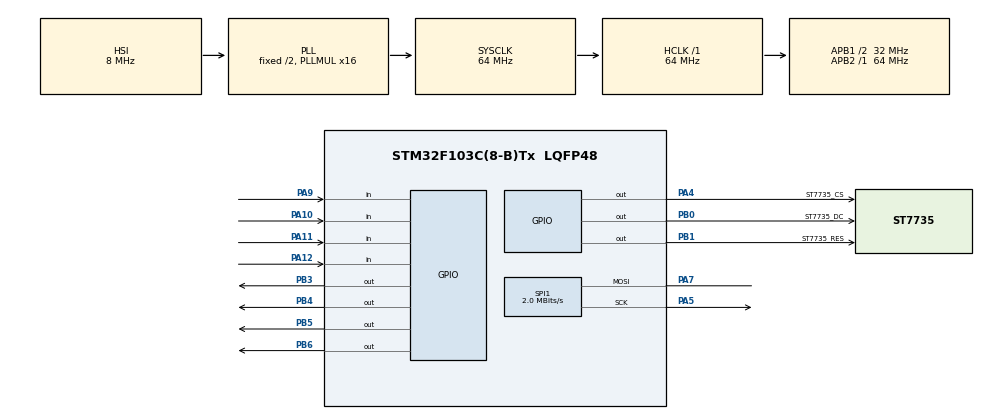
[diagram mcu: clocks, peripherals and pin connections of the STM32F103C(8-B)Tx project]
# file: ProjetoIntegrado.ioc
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Mcu.Family=STM32F1
Mcu.Name=STM32F103C(8-B)Tx
Mcu.Package=LQFP48
NVIC.PriorityGroup=NVIC_PRIORITYGROUP_4
PA10.GPIO_PuPd=GPIO_PULLUP
PA10.Signal=GPIO_Input
PA11.GPIO_PuPd=GPIO_PULLUP
PA11.Signal=GPIO_Input
PA12.GPIO_PuPd=GPIO_PULLUP
PA12.Signal=GPIO_Input
PA13.Mode=Serial_Wire
PA13.Signal=SYS_JTMS-SWDIO
PA14.Mode=Serial_Wire
PA14.Signal=SYS_JTCK-SWCLK
PA4.GPIO_Label=ST7735_CS
PA4.Signal=GPIO_Output
PA5.Mode=Simplex_Bidirectional_Master
PA5.Signal=SPI1_SCK
PA7.Mode=Simplex_Bidirectional_Master
PA7.Signal=SPI1_MOSI
PA9.GPIO_PuPd=GPIO_PULLUP
PA9.Signal=GPIO_Input
PB0.GPIO_Label=ST7735_DC
PB0.Signal=GPIO_Output
PB1.GPIO_Label=ST7735_RES
PB1.Signal=GPIO_Output
PB3.Signal=GPIO_Output
PB4.Signal=GPIO_Output
PB5.Signal=GPIO_Output
PB6.Signal=GPIO_Output
ProjectManager.HeapSize=0x200
ProjectManager.StackSize=0x400
ProjectManager.TargetToolchain=STM32CubeIDE
RCC.AHBFreq_Value=64000000
RCC.APB1CLKDivider=RCC_HCLK_DIV2
RCC.APB1Freq_Value=32000000
RCC.APB1TimFreq_Value=64000000
RCC.APB2Freq_Value=64000000
RCC.APB2TimFreq_Value=64000000
RCC.HCLKFreq_Value=64000000
RCC.PLLMUL=RCC_PLL_MUL16
RCC.SYSCLKFreq_VALUE=64000000
RCC.SYSCLKSource=RCC_SYSCLKSOURCE_PLLCLK
RCC.USBFreq_Value=64000000
SPI1.BaudRatePrescaler=SPI_BAUDRATEPRESCALER_32
SPI1.CalculateBaudRate=2.0 MBits/s
SPI1.Direction=SPI_DIRECTION_1LINE
SPI1.Mode=SPI_MODE_MASTER
SPI1.VirtualType=VM_MASTER
board=custom

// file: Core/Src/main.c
/* USER CODE BEGIN Header */
/**
  ******************************************************************************
  * @file           : main.c
  * @brief          : Main program body
  ******************************************************************************
  * @attention
  *
  * <h2><center>&copy; Copyright (c) 2025 STMicroelectronics.
  * All rights reserved.</center></h2>
  *
  * This software component is licensed by ST under BSD 3-Clause license,
  * the "License"; You may not use this file except in compliance with the
  * License. You may obtain a copy of the License at:
  *                        opensource.org/licenses/BSD-3-Clause
  *
  ******************************************************************************
  */
/* USER CODE END Header */
#include "main.h"
/* USER CODE BEGIN Includes */
#include "st7735\st7735.h"
#include <stdlib.h>
/* USER CODE END Includes */

SPI_HandleTypeDef hspi1;

/* USER CODE BEGIN PV */

static const uint16_t ImagemVitoria4[][60*80/2]   = {
  0x0000, 0x0000, 0x0000, 0x0000, 0x0000, 0x0000, 0x0000, 0x0000, 0x0000, 0x0000, 0x0000, 0x0000, 0x0000, 0x0000, 0x0000, 0x0000, 0x0000, 0x0000, 0x0000, 0x0000, 0x0000, 0x0000, 0x0000, 0x0000, 0x0000, 0x0000, 0x0000, 0x0000, 0x0000, 0x0000, 0x0000, 0x0000, 0x0000, 0x0000, 0x0000, 0x0000, 0x0000, 0x0000, 0x0000, 0x0000, 0x0000, 0x0000, 0x0000, 0x0000, 0x0000, 0x0000, 0x0000, 0x0000, 0x0000, 0x0000, 0x0000, 0x0000, 0x0000, 0x0000, 0x0000, 0x0000, 0x0000, 0x0000, 0x0000, 0x0000, 0x0000, 0x0000, 0x0000, 0x0000, 0x0000, 0x0000, 0x0000, 0x0000, 0x0000, 0x0000, 0x0000, 0x0000, 0x0000, 0x0000, 0x0000, 0x0000, 0x0000, 0x0000, 0x0000, 0x0000,
  0x0000, 0x0000, 0x0000, 0x0000, 0x0000, 0x0000, 0x0000, 0x0000, 0x0000, 0x0000, 0x0000, 0x0000, 0x0000, 0x0000, 0x0000, 0x0000, 0x0000, 0x0000, 0x0000, 0x0000, 0x0000, 0x0000, 0x0000, 0x0000, 0x0000, 0x0000, 0x0000, 0x0000, 0x0000, 0x0000, 0x0000, 0x0000, 0x0000, 0x0000, 0x0000, 0x0000, 0x0000, 0x0000, 0x0000, 0x0000, 0x0000, 0x0000, 0x0000, 0x0000, 0x0000, 0x0000, 0x0000, 0x0000, 0x0000, 0x0000, 0x0000, 0x0000, 0x0000, 0x0000, 0x0000, 0x0000, 0x0000, 0x0000, 0x0000, 0x0000, 0x0000, 0x0000, 0x0000, 0x0000, 0x0000, 0x0000, 0x0000, 0x0000, 0x0000, 0x0000, 0x0000, 0x0000, 0x0000, 0x0000, 0x0000, 0x0000, 0x0000, 0x0000, 0x0000, 0x0000,
  0x0000, 0x0000, 0x0000, 0x0000, 0x0000, 0x0000, 0x0000, 0x0000, 0x0000, 0x0000, 0x0000, 0x0000, 0x0000, 0x0000, 0x0000, 0x0000, 0x0000, 0x0000, 0x0000, 0x0000, 0x0000, 0x0000, 0x0000, 0x0000, 0x0000, 0x0000, 0x0000, 0x0000, 0x0000, 0x0000, 0x0000, 0x0000, 0x0000, 0x0000, 0x0000, 0x0000, 0x0000, 0x0000, 0x0000, 0x0000, 0x0000, 0x0000, 0x0000, 0x0000, 0x0000, 0x0000, 0x0000, 0x0000, 0x0000, 0x0000, 0x0000, 0x0000, 0x0000, 0x0000, 0x0000, 0x0000, 0x0000, 0x0000, 0x0000, 0x0000, 0x0000, 0x0000, 0x0000, 0x0000, 0x0000, 0x0000, 0x0000, 0x0000, 0x0000, 0x0000, 0x0000, 0x0000, 0x0000, 0x0000, 0x0000, 0x0000, 0x0000, 0x0000, 0x0000, 0x0000,
  0x0000, 0x0000, 0x0000, 0x0000, 0x0000, 0x0000, 0x0000, 0x0000, 0x0000, 0x0000, 0x0000, 0x0000, 0x0000, 0x0000, 0x0000, 0x0000, 0x0000, 0x0000, 0x0000, 0x0000, 0x0000, 0x0000, 0x0000, 0x0000, 0x0000, 0x0000, 0x0000, 0x0000, 0x0000, 0x0000, 0x0000, 0x0000, 0x0000, 0x0000, 0x0000, 0x0000, 0x0000, 0x0000, 0x0000, 0x0000, 0x0000, 0x0000, 0x0000, 0x0000, 0x0000, 0x0000, 0x0000, 0x0000, 0x0000, 0x0000, 0x0000, 0x0000, 0x0000, 0x0000, 0x0000, 0x0000, 0x0000, 0x0000, 0x0000, 0x0000, 0x0000, 0x0000, 0x0000, 0x0000, 0x0000, 0x0000, 0x0000, 0x0000, 0x0000, 0x0000, 0x0000, 0x0000, 0x0000, 0x0000, 0x0000, 0x0000, 0x0000, 0x0000, 0x0000, 0x0000,
  0x0000, 0x0000, 0x0000, 0x0000, 0x0000, 0x0000, 0x0000, 0x0000, 0x0000, 0x0000, 0x0000, 0x0000, 0x0000, 0x0000, 0x0000, 0x0000, 0x0000, 0x0000, 0x0000, 0x0000, 0x0000, 0x0000, 0x0000, 0x0000, 0x0000, 0x0000, 0x0000, 0x0000, 0x0000, 0x0000, 0x0000, 0x0000, 0x0000, 0x0000, 0x0000, 0x0000, 0x0000, 0x0000, 0x0000, 0x0000, 0x0000, 0x0000, 0x0000, 0x0000, 0x0000, 0x0000, 0x0000, 0x0000, 0x0000, 0x0000, 0x0000, 0x0000, 0x0000, 0x0000, 0x0000, 0x0000, 0x0000, 0x0000, 0x0000, 0x0000, 0x0000, 0x0000, 0x0000, 0x0000, 0x0000, 0x0000, 0x0000, 0x0000, 0x0000, 0x0000, 0x0000, 0x0000, 0x0000, 0x0000, 0x0000, 0x0000, 0x0000, 0x0000, 0x0000, 0x0000,
  0x0000, 0x0000, 0x0000, 0x0000, 0x0000, 0x0000, 0x0000, 0x0000, 0x0000, 0x0000, 0x0000, 0x0000, 0x0000, 0x0000, 0x0000, 0x0000, 0x0000, 0x0000, 0x0000, 0x0000, 0x0000, 0x0000, 0x0000, 0x0000, 0x0000, 0x0000, 0x0000, 0x0000, 0x0000, 0x0000, 0x0000, 0x0000, 0x0000, 0x0000, 0x0000, 0x0000, 0x0000, 0x0000, 0x0000, 0x0000, 0x0000, 0x0000, 0x0000, 0x0000, 0x0000, 0x0000, 0x0000, 0x0000, 0x0000, 0x0000, 0x0000, 0x0000, 0x0000, 0x0000, 0x0000, 0x0000, 0x0000, 0x0000, 0x0000, 0x0000, 0x0000, 0x0000, 0x0000, 0x0000, 0x0000, 0x0000, 0x0000, 0x0000, 0x0000, 0x0000, 0x0000, 0x0000, 0x0000, 0x0000, 0x0000, 0x0000, 0x0000, 0x0000, 0x0000, 0x0000,
  0x0000, 0x0000, 0x0000, 0x0000, 0x0000, 0x0000, 0x0000, 0x0000, 0x0000, 0x0000, 0x0000, 0x0000, 0x0000, 0x0000, 0x0000, 0x0000, 0x0000, 0x0000, 0x0000, 0x0000, 0x0000, 0x0000, 0x0000, 0x0000, 0x0000, 0x0000, 0x0000, 0x0000, 0x0000, 0x0000, 0x0000, 0x0000, 0x0000, 0x0000, 0x0000, 0x0000, 0x0000, 0x0000, 0x0000, 0x0000, 0x0000, 0x0000, 0x0000, 0x0000, 0x0000, 0x0000, 0x0000, 0x0000, 0x0000, 0x0000, 0x0000, 0x0000, 0x0000, 0x0000, 0x0000, 0x0000, 0x0000, 0x0000, 0x0000, 0x0000, 0x0000, 0x0000, 0x0000, 0x0000, 0x0000, 0x0000, 0x0000, 0x0000, 0x0000, 0x0000, 0x0000, 0x0000, 0x0000, 0x0000, 0x0000, 0x0000, 0x0000, 0x0000, 0x0000, 0x0000,
  0x0000, 0x0000, 0x0000, 0x0000, 0x0000, 0x0000, 0x0000, 0x0000, 0x0000, 0x0000, 0x0000, 0x0000, 0x0000, 0x0000, 0x0000, 0x0000, 0x0000, 0x0000, 0x0000, 0x0000, 0x0000, 0x0000, 0x0000, 0x0000, 0x0000, 0x0000, 0x0000, 0x0000, 0x0000, 0x0000, 0x0000, 0x0000, 0x0000, 0x0000, 0x0000, 0x0000, 0x0000, 0x0000, 0x0000, 0x0000, 0x0000, 0x0000, 0x0000, 0x0000, 0x0000, 0x0000, 0x0000, 0x0000, 0x0000, 0x0000, 0x0000, 0x0000, 0x0000, 0x0000, 0x0000, 0x0000, 0x0000, 0x0000, 0x0000, 0x0000, 0x0000, 0x0000, 0x0000, 0x0000, 0x0000, 0x0000, 0x0000, 0x0000, 0x0000, 0x0000, 0x0000, 0x0000, 0x0000, 0x0000, 0x0000, 0x0000, 0x0000, 0x0000, 0x0000, 0x0000,
  0x0000, 0x0000, 0x0000, 0x0000, 0x0000, 0x0000, 0x0000, 0x0000, 0x0000, 0x0000, 0x0000, 0x0000, 0x0000, 0x0000, 0x0000, 0x0000, 0x0000, 0x0000, 0x0000, 0x0000, 0x0000, 0x0000, 0x0000, 0x0000, 0x0000, 0x0000, 0x0000, 0x0000, 0x0000, 0x0000, 0x0000, 0x0000, 0x0000, 0x0000, 0x0000, 0x0000, 0x0000, 0x0000, 0x0000, 0x0000, 0x0000, 0x0000, 0x0000, 0x0000, 0x0000, 0x0000, 0x0000, 0x0000, 0x0000, 0x0000, 0x0000, 0x0000, 0x0000, 0x0000, 0x0000, 0x0000, 0x0000, 0x0000, 0x0000, 0x0000, 0x0000, 0x0000, 0x0000, 0x0000, 0x0000, 0x0000, 0x0000, 0x0000, 0x0000, 0x0000, 0x0000, 0x0000, 0x0000, 0x0000, 0x0000, 0x0000, 0x0000, 0x0000, 0x0000, 0x0000,
  0x0000, 0x0000, 0x0000, 0x0000, 0x0000, 0x0000, 0x0000, 0x0000, 0x0000, 0x0000, 0x0000, 0x0000, 0x0000, 0x0000, 0x0000, 0x0000, 0x0000, 0x0000, 0x0000, 0x0000, 0x0000, 0x0000, 0x0000, 0x0000, 0x0000, 0x0000, 0x0000, 0x0000, 0x0000, 0x0000, 0x0000, 0x0000, 0x0000, 0x0000, 0x0000, 0x0000, 0x0000, 0x0000, 0x0000, 0x0000, 0x0000, 0x0000, 0x0000, 0x0000, 0x0000, 0x0000, 0x0000, 0x0000, 0x0000, 0x0000, 0x0000, 0x0000, 0x0000, 0x0000, 0x0000, 0x0000, 0x0000, 0x0000, 0x0000, 0x0000, 0x0000, 0x0000, 0x0000, 0x0000, 0x0000, 0x0000, 0x0000, 0x0000, 0x0000, 0x0000, 0x0000, 0x0000, 0x0000, 0x0000, 0x0000, 0x0000, 0x0000, 0x0000, 0x0000, 0x0000,
  0x0000, 0x0000, 0x0000, 0x0000, 0x0000, 0x0000, 0x0000, 0x0000, 0x0000, 0x0000, 0x0000, 0x0000, 0x0000, 0x0000, 0x0000, 0x0000, 0x0000, 0x0000, 0x0000, 0x0000, 0x0000, 0x0000, 0x0000, 0x0000, 0x0000, 0x0000, 0x0000, 0x0000, 0x0000, 0x0000, 0x0000, 0x0000, 0x0000, 0x0000, 0x0000, 0x0000, 0x0000, 0x0000, 0x0000, 0x0000, 0x0000, 0x0000, 0x0000, 0x0000, 0x0000, 0x0000, 0x0000, 0x0000, 0x0000, 0x0000, 0x0000, 0x0000, 0x0000, 0x0000, 0x0000, 0x0000, 0x0000, 0x0000, 0x0000, 0x0000, 0x0000, 0x0000, 0x0000, 0x0000, 0x0000, 0x0000, 0x0000, 0x0000, 0x0000, 0x0000, 0x0000, 0x0000, 0x0000, 0x0000, 0x0000, 0x0000, 0x0000, 0x0000, 0x0000, 0x0000,
  0x0000, 0x0000, 0x0000, 0x0000, 0x0000, 0x0000, 0x0000, 0x0000, 0x0000, 0x0000, 0x0000, 0x0000, 0x0000, 0x0000, 0x0000, 0x0000, 0x0000, 0x0000, 0x0000, 0x0000, 0x0000, 0x0000, 0x0000, 0x0000, 0x0000, 0x0000, 0x0000, 0x0000, 0x0000, 0x0000, 0x0000, 0x0000, 0x0000, 0x0000, 0x0000, 0x0000, 0x0000, 0x0000, 0x0000, 0x0000, 0x0000, 0x0000, 0x0000, 0x0000, 0x0000, 0x0000, 0x0000, 0x0000, 0x0000, 0x0000, 0x0000, 0x0000, 0x0000, 0x0000, 0x0000, 0x0000, 0x0000, 0x0000, 0x0000, 0x0000, 0x0000, 0x0000, 0x0000, 0x0000, 0x0000, 0x0000, 0x0000, 0x0000, 0x0000, 0x0000, 0x0000, 0x0000, 0x0000, 0x0000, 0x0000, 0x0000, 0x0000, 0x0000, 0x0000, 0x0000,
  0x0000, 0x0000, 0x0000, 0x0000, 0x0000, 0x0000, 0x0000, 0x0000, 0x0000, 0x0000, 0x0000, 0x0000, 0x0000, 0x0000, 0x0000, 0x0000, 0x0000, 0x0000, 0x0000, 0x0000, 0x0000, 0x0000, 0x0000, 0x0000, 0x0000, 0x0000, 0x0000, 0x0000, 0x0000, 0x0000, 0x0000, 0x0000, 0x0000, 0x0000, 0x0000, 0x0000, 0x0000, 0x0000, 0x0000, 0x0000, 0x0000, 0x0000, 0x0000, 0x0000, 0x0000, 0x0000, 0x0000, 0x0000, 0x0000, 0x0000, 0x0000, 0x0000, 0x0000, 0x0000, 0x0000, 0x0000, 0x0000, 0x0000, 0x0000, 0x0000, 0x0000, 0x0000, 0x0000, 0x0000, 0x0000, 0x0000, 0x0000, 0x0000, 0x0000, 0x0000, 0x0000, 0x0000, 0x0000, 0x0000, 0x0000, 0x0000, 0x0000, 0x0000, 0x0000, 0x0000,
  0x0000, 0x0000, 0x0000, 0x0000, 0x0000, 0x0000, 0x0000, 0x0000, 0x0000, 0x0000, 0x0000, 0x0000, 0x0000, 0x0000, 0x0000, 0x0000, 0x0000, 0x0000, 0x0000, 0x0000, 0x0000, 0x0000, 0x0000, 0x0000, 0x0000, 0x0000, 0x0000, 0x0000, 0x0000, 0x0000, 0x0000, 0x0000, 0x0000, 0x0000, 0x0000, 0x0000, 0x0000, 0x0000, 0x0000, 0x0000, 0x0000, 0x0000, 0x0000, 0x0000, 0x0000, 0x0000, 0x0000, 0x0000, 0x0000, 0x0000, 0x0000, 0x0000, 0x0000, 0x0000, 0x0000, 0x0000, 0x0000, 0x0000, 0x0000, 0x0000, 0x0000, 0x0000, 0x0000, 0x0000, 0x0000, 0x0000, 0x0000, 0x0000, 0x0000, 0x0000, 0x0000, 0x0000, 0x0000, 0x0000, 0x0000, 0x0000, 0x0000, 0x0000, 0x0000, 0x0000,
  0x0000, 0x0000, 0x0000, 0x0000, 0x0000, 0x0000, 0x0000, 0x0000, 0x0000, 0x0000, 0x0000, 0x0000, 0x0000, 0x0000, 0x0000, 0x0000, 0x0000, 0x0000, 0x0000, 0x0000, 0x0000, 0x0000, 0x0000, 0x0000, 0x0000, 0x0000, 0x0000, 0x0000, 0x0000, 0x0000, 0x0000, 0x0000, 0x0000, 0x0000, 0x0000, 0x0000, 0x0000, 0x0000, 0x0000, 0x0000, 0x0000, 0x0000, 0x0000, 0x0000, 0x0000, 0x0000, 0x0000, 0x0000, 0x0000, 0x0000, 0x0000, 0x0000, 0x0000, 0x0000, 0x0000, 0x0000, 0x0000, 0x0000, 0x0000, 0x0000, 0x0000, 0x0000, 0x0000, 0x0000, 0x0000, 0x0000, 0x0000, 0x0000, 0x0000, 0x0000, 0x0000, 0x0000, 0x0000, 0x0000, 0x0000, 0x0000, 0x0000, 0x0000, 0x0000, 0x0000,
  0x0000, 0x0000, 0x0000, 0x0000, 0x0000, 0x0000, 0x0000, 0x0000, 0x0000, 0x0000, 0x0000, 0x0000, 0x0000, 0x0000, 0x0000, 0x0000, 0x0000, 0x0000, 0x0000, 0x0000, 0x0000, 0x0000, 0x0000, 0x0000, 0x0000, 0x0000, 0x0000, 0x0000, 0x0000, 0x0000, 0x0000, 0x0000, 0x0000, 0x0000, 0x0000, 0x0000, 0x0000, 0x0000, 0x0000, 0x0000, 0x0000, 0x0000, 0x0000, 0x0000, 0x0000, 0x0000, 0x0000, 0x0000, 0x0000, 0x0000, 0x0000, 0x0000, 0x0000, 0x0000, 0x0000, 0x0000, 0x0000, 0x0000, 0x0000, 0x0000, 0x0000, 0x0000, 0x0000, 0x0000, 0x0000, 0x0000, 0x0000, 0x0000, 0x0000, 0x0000, 0x0000, 0x0000, 0x0000, 0x0000, 0x0000, 0x0000, 0x0000, 0x0000, 0x0000, 0x0000,
  0x0000, 0x0000, 0x0000, 0x0000, 0x0000, 0x0000, 0x0000, 0x0000, 0x0000, 0x0000, 0x0000, 0x0000, 0x0000, 0x0000, 0x0000, 0x0000, 0x0000, 0x0000, 0x0000, 0x0000, 0x0000, 0x0000, 0x0000, 0x0000, 0x0000, 0x0000, 0x0000, 0x0000, 0x0000, 0x0000, 0x0000, 0x0000, 0x0000, 0x0000, 0x0000, 0x0000, 0x0000, 0x0000, 0x0000, 0x0000, 0x0000, 0x0000, 0x0000, 0x0000, 0x0000, 0x0000, 0x0000, 0x0000, 0x0000, 0x0000, 0x0000, 0x0000, 0x0000, 0x0000, 0x0000, 0x0000, 0x0000, 0x0000, 0x0000, 0x0000, 0x0000, 0x0000, 0x0000, 0x0000, 0x0000, 0x0000, 0x0000, 0x0000, 0x0000, 0x0000, 0x0000, 0x0000, 0x0000, 0x0000, 0x0000, 0x0000, 0x0000, 0x0000, 0x0000, 0x0000,
  0x0000, 0x0000, 0x0000, 0x0000, 0x0000, 0x0000, 0x0000, 0x0000, 0x0000, 0x0000, 0x0000, 0x0000, 0x0000, 0x0000, 0x0000, 0x0000, 0x0000, 0x0000, 0x0000, 0x0000, 0x0000, 0x0000, 0x0000, 0x0000, 0x0000, 0x0000, 0x0000, 0x0000, 0x0000, 0x0000, 0x0000, 0x0000, 0x0000, 0x0000, 0x0000, 0x0000, 0x0000, 0x0000, 0x0000, 0x0000, 0x0000, 0x0000, 0x0000, 0x0000, 0x0000, 0x0000, 0x0000, 0x0000, 0x0000, 0x0000, 0x0000, 0x0000, 0x0000, 0x0000, 0x0000, 0x0000, 0x0000, 0x0000, 0x0000, 0x0000, 0x0000, 0x0000, 0x0000, 0x0000, 0x0000, 0x0000, 0x0000, 0x0000, 0x0000, 0x0000, 0x0000, 0x0000, 0x0000, 0x0000, 0x0000, 0x0000, 0x0000, 0x0000, 0x0000, 0x0000,
  0x0000, 0x0000, 0x0000, 0x0000, 0x0000, 0x0000, 0x0000, 0x0000, 0x0000, 0x0000, 0x0000, 0x0000, 0x0000, 0x0000, 0x0000, 0x0000, 0x0000, 0x0000, 0x0000, 0x0000, 0x0000, 0x0000, 0x0000, 0x0000, 0x0000, 0x0000, 0x0000, 0x0000, 0x0000, 0x0000, 0x0000, 0x0000, 0x0000, 0x0000, 0x0000, 0x0000, 0x0000, 0x0000, 0x0000, 0x0000, 0x0000, 0x0000, 0x0000, 0x0000, 0x0000, 0x0000, 0x0000, 0x0000, 0x0000, 0x0000, 0x0000, 0x0000, 0x0000, 0x0000, 0x0000, 0x0000, 0x0000, 0x0000, 0x0000, 0x0000, 0x0000, 0x0000, 0x0000, 0x0000, 0x0000, 0x0000, 0x0000, 0x0000, 0x0000, 0x0000, 0x0000, 0x0000, 0x0000, 0x0000, 0x0000, 0x0000, 0x0000, 0x0000, 0x0000, 0x0000,
  0x0000, 0x0000, 0x0000, 0x0000, 0x0000, 0x0000, 0x0000, 0x0000, 0x0000, 0x0000, 0x0000, 0x0000, 0x0000, 0x0000, 0x0000, 0x0000, 0x0000, 0x0000, 0x0000, 0x0000, 0x0000, 0x0000, 0x0000, 0x0000, 0x0000, 0x0000, 0x0000, 0x0000, 0x0000, 0x0000, 0x0000, 0x0000, 0x0000, 0x0000, 0x0000, 0x0000, 0x0000, 0x0000, 0x0000, 0x0000, 0x0000, 0x0000, 0x0000, 0x0000, 0x0000, 0x0000, 0x0000, 0x0000, 0x0000, 0x0000, 0x0000, 0x0000, 0x0000, 0x0000, 0x0000, 0x0000, 0x0000, 0x0000, 0x0000, 0x0000, 0x0000, 0x0000, 0x0000, 0x0000, 0x0000, 0x0000, 0x0000, 0x0000, 0x0000, 0x0000, 0x0000, 0x0000, 0x0000, 0x0000, 0x0000, 0x0000, 0x0000, 0x0000, 0x0000, 0x0000,
  0x0000, 0x0000, 0x0000, 0x0000, 0x0000, 0x0000, 0x0000, 0x0000, 0x0000, 0x0000, 0x0000, 0x0000, 0x0000, 0x0000, 0x0000, 0x0000, 0x0000, 0x0000, 0x0000, 0x0000, 0x0000, 0x0000, 0x0000, 0x0000, 0x0000, 0x0000, 0x0000, 0x0000, 0x0000, 0x0000, 0x0000, 0x0000, 0x0000, 0x0000, 0x0000, 0x0000, 0x0000, 0x0000, 0x0000, 0x0000, 0x0000, 0x0000, 0x0000, 0x0000, 0x0000, 0x0000, 0x0000, 0x0000, 0x0000, 0x0000, 0x0000, 0x0000, 0x0000, 0x0000, 0x0000, 0x0000, 0x0000, 0x0000, 0x0000, 0x0000, 0x0000, 0x0000, 0x0000, 0x0000, 0x0000, 0x0000, 0x0000, 0x0000, 0x0000, 0x0000, 0x0000, 0x0000, 0x0000, 0x0000, 0x0000, 0x0000, 0x0000, 0x0000, 0x0000, 0x0000,
  0x0000, 0x0000, 0x0000, 0x0000, 0x0000, 0x0000, 0x0000, 0x0000, 0x0000, 0x0000, 0x0000, 0x0000, 0x0000, 0x0000, 0x0000, 0x0000, 0x0000, 0x0000, 0x0000, 0x0000, 0x0000, 0x0000, 0x0000, 0x0000, 0x0000, 0x0000, 0x0000, 0x0000, 0x0000, 0x0000, 0x0000, 0x0000, 0x0000, 0x0000, 0x0000, 0x0000, 0x0000, 0x0000, 0x0000, 0x0000, 0x0000, 0x0000, 0x0000, 0x0000, 0x0000, 0x0000, 0x0000, 0x0000, 0x0000, 0x0000, 0x0000, 0x0000, 0x0000, 0x0000, 0x0000, 0x0000, 0x0000, 0x0000, 0x0000, 0x0000, 0x0000, 0x0000, 0x0000, 0x0000, 0x0000, 0x0000, 0x0000, 0x0000, 0x0000, 0x0000, 0x0000, 0x0000, 0x0000, 0x0000, 0x0000, 0x0000, 0x0000, 0x0000, 0x0000, 0x0000,
  0x0000, 0x0000, 0x0000, 0x0000, 0x0000, 0x0000, 0x0000, 0x0000, 0x0000, 0x0000, 0x0000, 0x0000, 0x0000, 0x0000, 0x0000, 0x0000, 0x0000, 0x0000, 0x0000, 0x0000, 0x0000, 0x0000, 0x0000, 0x0000, 0x0000, 0x0000, 0x0000, 0x0000, 0x0000, 0x0000, 0x0000, 0x0000, 0x0000, 0x0000, 0x0000, 0x0000, 0x0000, 0x0000, 0x0000, 0x0000, 0x0000, 0x0000, 0x0000, 0x0000, 0x0000, 0x0000, 0x0000, 0x0000, 0x0000, 0x0000, 0x0000, 0x0000, 0x0000, 0x0000, 0x0000, 0x0000, 0x0000, 0x0000, 0x0000, 0x0000, 0x0000, 0x0000, 0x0000, 0x0000, 0x0000, 0x0000, 0x0000, 0x0000, 0x0000, 0x0000, 0x0000, 0x0000, 0x0000, 0x0000, 0x0000, 0x0000, 0x0000, 0x0000, 0x0000, 0x0000,
  0x0000, 0x0000, 0x0000, 0x0000, 0x0000, 0x0000, 0x0000, 0x0000, 0x0000, 0x0000, 0x0000, 0x0000, 0x0000, 0x0000, 0x0000, 0x0000, 0x0000, 0x0000, 0x0000, 0x0000, 0x0000, 0x0000, 0x0000, 0x0000, 0x0000, 0x0000, 0x0000, 0x0000, 0x0000, 0x0000, 0x0000, 0x0000, 0x0000, 0x0000, 0x0000, 0x0000, 0x0000, 0x0000, 0x0000, 0x0000, 0x0000, 0x0000, 0x0000, 0x0000, 0x0000, 0x0000, 0x0000, 0x0000, 0x0000, 0x0000, 0x0000, 0x0000, 0x0000, 0x0000, 0x0000, 0x0000, 0x0000, 0x0000, 0x0000, 0x0000, 0x0000, 0x0000, 0x0000, 0x0000, 0x0000, 0x0000, 0x0000, 0x0000, 0x0000, 0x0000, 0x0000, 0x0000, 0x0000, 0x0000, 0x0000, 0x0000, 0x0000, 0x0000, 0x0000, 0x0000,
  0x0000, 0x0000, 0x0000, 0x0000, 0x0000, 0x0000, 0x0000, 0x0000, 0x0000, 0x0000, 0x0000, 0x0000, 0x0000, 0x0000, 0x0000, 0x0000, 0x0000, 0x0000, 0x0000, 0x0000, 0x0000, 0x0000, 0x0000, 0x0000, 0x0000, 0x0000, 0x0000, 0x0000, 0x619c, 0x619c, 0x619c, 0x619c, 0x0000, 0x619c, 0x619c, 0x619c, 0x619c, 0x0000, 0x619c, 0x619c, 0x619c, 0x619c, 0x619c, 0x619c, 0x619c, 0x629c, 0x0000, 0x0000, 0x619c, 0x619c, 0x619c, 0x619c, 0x0000, 0x0000, 0x629c, 0x619c, 0x619c, 0x619c, 0x0000, 0x0000, 0x0000, 0x0000, 0x0000, 0x0000, 0x0000, 0x0000, 0x0000, 0x0000, 0x0000, 0x0000, 0x0000, 0x0000, 0x0000, 0x0000, 0x0000, 0x0000, 0x0000, 0x0000, 0x0000, 0x0000,
  0x0000, 0x0000, 0x0000, 0x0000, 0x0000, 0x0000, 0x0000, 0x0000, 0x0000, 0x0000, 0x0000, 0x0000, 0x0000, 0x0000, 0x0000, 0x0000, 0x0000, 0x0000, 0x0000, 0x0000, 0x0000, 0x0000, 0x0000, 0x0000, 0x0000, 0x0000, 0x0000, 0x00ce, 0xc0cd, 0x60bd, 0x81a4, 0x419c, 0x00ce, 0xc0cd, 0x60bd, 0x81a4, 0x419c, 0x00ce, 0xc0cd, 0x80bd, 0x80bd, 0x80bd, 0x80bd, 0x20b5, 0x619c, 0x619c, 0x619c, 0x00ce, 0xc0cd, 0x60bd, 0x81a4, 0x419c, 0x0000, 0xe0cd, 0xe0cd, 0x80c5, 0xc1a4, 0x419c, 0x0000, 0x0000, 0x0000, 0x0000, 0x0000, 0x0000, 0x0000, 0x0000, 0x0000, 0x0000, 0x0000, 0x0000, 0x0000, 0x0000, 0x0000, 0x0000, 0x0000, 0x0000, 0x0000, 0x0000, 0x0000, 0x0000,
  0x0000, 0x0000, 0x0000, 0x0000, 0x0000, 0x0000, 0x0000, 0x0000, 0x0000, 0x0000, 0x0000, 0x0000, 0x0000, 0x0000, 0x0000, 0x0000, 0x0000, 0x0000, 0x0000, 0x0000, 0x0000, 0x0000, 0x0000, 0x0000, 0x0000, 0x0000, 0x0000, 0xe0cd, 0x00ce, 0xc0cd, 0x81a4, 0x419c, 0xe0cd, 0x00ce, 0xc0cd, 0x81a4, 0x60bd, 0x00ce, 0xa0c5, 0xc1ac, 0x80bd, 0xe0cd, 0x00ce, 0xe0cd, 0x80bd, 0x81a4, 0x419c, 0xe0cd, 0x00ce, 0xc0cd, 0x81a4, 0x419c, 0x0000, 0x00ce, 0x00ce, 0x00ce, 0xe1ac, 0x419c, 0x0000, 0x0000, 0x0000, 0x0000, 0x0000, 0x0000, 0x0000, 0x0000, 0x0000, 0x0000, 0x0000, 0x0000, 0x0000, 0x0000, 0x0000, 0x0000, 0x0000, 0x0000, 0x0000, 0x0000, 0x0000, 0x0000,
  0x0000, 0x0000, 0x0000, 0x0000, 0x0000, 0x0000, 0x0000, 0x0000, 0x0000, 0x0000, 0x0000, 0x0000, 0x0000, 0x0000, 0x0000, 0x0000, 0x0000, 0x0000, 0x0000, 0x0000, 0x0000, 0x0000, 0x0000, 0x0000, 0x0000, 0x0000, 0x0000, 0xe0cd, 0x00ce, 0xc0cd, 0x81a4, 0x619c, 0x40b5, 0x00ce, 0x00ce, 0x01b5, 0xe0cd, 0x00ce, 0x80bd, 0x619c, 0x419c, 0x0000, 0xe0cd, 0x00ce, 0xc0cd, 0x81a4, 0x419c, 0xe0cd, 0x00ce, 0xc0cd, 0x81a4, 0x419c, 0x0000, 0x00ce, 0x00ce, 0x00ce, 0xe1ac, 0x419c, 0x0000, 0x0000, 0x0000, 0x0000, 0x0000, 0x0000, 0x0000, 0x0000, 0x0000, 0x0000, 0x0000, 0x0000, 0x0000, 0x0000, 0x0000, 0x0000, 0x0000, 0x0000, 0x0000, 0x0000, 0x0000, 0x0000,
  0x0000, 0x0000, 0x0000, 0x0000, 0x0000, 0x0000, 0x0000, 0x0000, 0x0000, 0x0000, 0x0000, 0x0000, 0x0000, 0x0000, 0x0000, 0x0000, 0x0000, 0x0000, 0x0000, 0x0000, 0x0000, 0x0000, 0x0000, 0x0000, 0x0000, 0x0000, 0x0000, 0x20c6, 0xe0cd, 0xe0cd, 0xc0cd, 0xc0cd, 0xe0cd, 0x00ce, 0x40d6, 0x40ad, 0x00ce, 0x00ce, 0x80bd, 0x619c, 0x419c, 0x0000, 0xe0cd, 0x00ce, 0xc0cd, 0x81a4, 0x419c, 0xe0cd, 0x00ce, 0xc0cd, 0x81a4, 0x419c, 0x0000, 0x00ce, 0x00ce, 0x00ce, 0xe1ac, 0x419c, 0x0000, 0x0000, 0x0000, 0x0000, 0x0000, 0x0000, 0x0000, 0x0000, 0x0000, 0x0000, 0x0000, 0x0000, 0x0000, 0x0000, 0x0000, 0x0000, 0x0000, 0x0000, 0x0000, 0x0000, 0x0000, 0x0000,
  0x0000, 0x0000, 0x0000, 0x0000, 0x0000, 0x0000, 0x0000, 0x0000, 0x0000, 0x0000, 0x0000, 0x0000, 0x0000, 0x0000, 0x0000, 0x0000, 0x0000, 0x0000, 0x0000, 0x0000, 0x0000, 0x0000, 0x0000, 0x0000, 0x0000, 0x0000, 0x0000, 0x0000, 0x40ad, 0x01ce, 0x00ce, 0x00ce, 0x20b5, 0x619c, 0x0000, 0x0000, 0x00ce, 0x00ce, 0x80bd, 0x619c, 0x419c, 0x0000, 0xe0cd, 0x00ce, 0xc0cd, 0x81a4, 0x419c, 0xe0cd, 0x00ce, 0xc0cd, 0x81a4, 0x419c, 0x0000, 0x00ce, 0x00ce, 0x00ce, 0xe1ac, 0x419c, 0x0000, 0x0000, 0x0000, 0x0000, 0x0000, 0x0000, 0x0000, 0x0000, 0x0000, 0x0000, 0x0000, 0x0000, 0x0000, 0x0000, 0x0000, 0x0000, 0x0000, 0x0000, 0x0000, 0x0000, 0x0000, 0x0000,
  0x0000, 0x0000, 0x0000, 0x0000, 0x0000, 0x0000, 0x0000, 0x0000, 0x0000, 0x0000, 0x0000, 0x0000, 0x0000, 0x0000, 0x0000, 0x0000, 0x0000, 0x0000, 0x0000, 0x0000, 0x0000, 0x0000, 0x0000, 0x0000, 0x0000, 0x0000, 0x0000, 0x0000, 0x0000, 0xc1cd, 0x00ce, 0x00ce, 0x20b5, 0x619c, 0x0000, 0x0000, 0x00ce, 0x00ce, 0x80c5, 0x619c, 0x619c, 0x619c, 0x20b5, 0x00ce, 0x00ce, 0x00ce, 0x0000, 0x00ce, 0x00ce, 0xc0cd, 0xa1a4, 0x619c, 0x619c, 0xe1ac, 0x00ce, 0x00ce, 0x00ce, 0x0000, 0x0000, 0x0000, 0x0000, 0x0000, 0x0000, 0x0000, 0x0000, 0x0000, 0x0000, 0x0000, 0x0000, 0x0000, 0x0000, 0x0000, 0x0000, 0x0000, 0x0000, 0x0000, 0x0000, 0x0000, 0x0000, 0x0000,
  0x0000, 0x0000, 0x0000, 0x0000, 0x0000, 0x0000, 0x0000, 0x0000, 0x0000, 0x0000, 0x0000, 0x0000, 0x0000, 0x0000, 0x0000, 0x0000, 0x0000, 0x0000, 0x0000, 0x0000, 0x0000, 0x0000, 0x0000, 0x0000, 0x0000, 0x0000, 0x0000, 0x0000, 0x0000, 0x40d6, 0x00ce, 0x00ce, 0xe0cd, 0x0000, 0x0000, 0x0000, 0x0000, 0xe0cd, 0x00ce, 0x00ce, 0x00ce, 0x00ce, 0x00ce, 0x00ce, 0x0000, 0x0000, 0x0000, 0x0000, 0x00ce, 0x00ce, 0x00ce, 0x00ce, 0x00ce, 0x00ce, 0x00ce, 0x40d6, 0x0000, 0x0000, 0x0000, 0x0000, 0x0000, 0x0000, 0x0000, 0x0000, 0x0000, 0x0000, 0x0000, 0x0000, 0x0000, 0x0000, 0x0000, 0x0000, 0x0000, 0x0000, 0x0000, 0x0000, 0x0000, 0x0000, 0x0000, 0x0000,
  0x0000, 0x0000, 0x0000, 0x0000, 0x0000, 0x0000, 0x0000, 0x0000, 0x0000, 0x0000, 0x0000, 0x0000, 0x0000, 0x0000, 0x0000, 0x0000, 0x0000, 0x0000, 0x0000, 0x0000, 0x0000, 0x0000, 0x0000, 0x0000, 0x0000, 0x0000, 0x819c, 0x619c, 0x819c, 0x0000, 0x0000, 0x0000, 0x0000, 0x0000, 0x0000, 0x0000, 0x819c, 0x619c, 0x819c, 0x0000, 0x0000, 0x819c, 0x619c, 0x619c, 0x619c, 0x619c, 0x409c, 0x0000, 0x409c, 0x619c, 0x619c, 0x409c, 0x0000, 0x0000, 0x0000, 0x0000, 0x0000, 0x819c, 0x619c, 0x60a4, 0x00bc, 0x0000, 0x0000, 0x0000, 0x0000, 0x0000, 0x0000, 0x0000, 0x0000, 0x0000, 0x0000, 0x0000, 0x0000, 0x0000, 0x0000, 0x0000, 0x0000, 0x0000, 0x0000, 0x0000,
  0x0000, 0x0000, 0x0000, 0x0000, 0x0000, 0x0000, 0x0000, 0x0000, 0x0000, 0x0000, 0x0000, 0x0000, 0x0000, 0x0000, 0x0000, 0x0000, 0x0000, 0x0000, 0x0000, 0x0000, 0x0000, 0x0000, 0x0000, 0x0000, 0xa0d6, 0xe0cd, 0xe1ac, 0x81a4, 0x619c, 0x0000, 0x0000, 0x609c, 0x619c, 0x609c, 0xa0d6, 0xe0cd, 0xe1ac, 0x81a4, 0x619c, 0xa0d6, 0xe0cd, 0xe1ac, 0xc1ac, 0xc1ac, 0xc1ac, 0x619c, 0x419c, 0xc1cd, 0x20b5, 0xc1a4, 0x619c, 0x619c, 0x819c, 0x0000, 0x0000, 0x0000, 0xe0cd, 0x01ad, 0xa1a4, 0x619c, 0x419c, 0x0000, 0x0000, 0x0000, 0x0000, 0x0000, 0x0000, 0x0000, 0x0000, 0x0000, 0x0000, 0x0000, 0x0000, 0x0000, 0x0000, 0x0000, 0x0000, 0x0000, 0x0000, 0x0000,
  0x0000, 0x0000, 0x0000, 0x0000, 0x0000, 0x0000, 0x0000, 0x0000, 0x0000, 0x0000, 0x0000, 0x0000, 0x0000, 0x0000, 0x0000, 0x0000, 0x0000, 0x0000, 0x0000, 0x0000, 0x0000, 0x0000, 0x0000, 0x0000, 0xc1cd, 0x00ce, 0x00ce, 0x20b5, 0x619c, 0xe0bd, 0x00ce, 0x01b5, 0xa1a4, 0x619c, 0xc1cd, 0x00ce, 0x00ce, 0x20b5, 0x619c, 0x20d6, 0x00ce, 0x00ce, 0x00ce, 0xc0cd, 0x80c5, 0x81bd, 0x0000, 0xe0cd, 0x00ce, 0xe0cd, 0x01ad, 0x81a4, 0x619c, 0x619c, 0x0000, 0x0000, 0x00ce, 0x00ce, 0x80bd, 0x619c, 0x419c, 0x0000, 0x0000, 0x0000, 0x0000, 0x0000, 0x0000, 0x0000, 0x0000, 0x0000, 0x0000, 0x0000, 0x0000, 0x0000, 0x0000, 0x0000, 0x0000, 0x0000, 0x0000, 0x0000,
  0x0000, 0x0000, 0x0000, 0x0000, 0x0000, 0x0000, 0x0000, 0x0000, 0x0000, 0x0000, 0x0000, 0x0000, 0x0000, 0x0000, 0x0000, 0x0000, 0x0000, 0x0000, 0x0000, 0x0000, 0x0000, 0x0000, 0x0000, 0x0000, 0xc1cd, 0x00ce, 0x00ce, 0x20b5, 0x619c, 0xc1cd, 0x00ce, 0x00ce, 0x20b5, 0x619c, 0xc1cd, 0x00ce, 0x00ce, 0x20b5, 0x619c, 0x0000, 0x0000, 0x00ce, 0x00ce, 0x80bd, 0x619c, 0x419c, 0x0000, 0xe0cd, 0x00ce, 0x00ce, 0x00ce, 0x40bd, 0xa1a4, 0x619c, 0x619c, 0x009c, 0x00ce, 0x00ce, 0x80bd, 0x619c, 0x419c, 0x0000, 0x0000, 0x0000, 0x0000, 0x0000, 0x0000, 0x0000, 0x0000, 0x0000, 0x0000, 0x0000, 0x0000, 0x0000, 0x0000, 0x0000, 0x0000, 0x0000, 0x0000, 0x0000,
  0x0000, 0x0000, 0x0000, 0x0000, 0x0000, 0x0000, 0x0000, 0x0000, 0x0000, 0x0000, 0x0000, 0x0000, 0x0000, 0x0000, 0x0000, 0x0000, 0x0000, 0x0000, 0x0000, 0x0000, 0x0000, 0x0000, 0x0000, 0x0000, 0xc1cd, 0x00ce, 0x00ce, 0x20b5, 0x619c, 0xc1cd, 0x00ce, 0x00ce, 0x20b5, 0x619c, 0xc1cd, 0x00ce, 0x00ce, 0x20b5, 0x619c, 0x0000, 0x0000, 0x00ce, 0x00ce, 0x80bd, 0x619c, 0x419c, 0x0000, 0xe0cd, 0x00ce, 0xe0cd, 0x60bd, 0xc0cd, 0x80c5, 0xe1ac, 0x619c, 0x619c, 0xc0c5, 0x00ce, 0x80bd, 0x619c, 0x419c, 0x0000, 0x0000, 0x0000, 0x0000, 0x0000, 0x0000, 0x0000, 0x0000, 0x0000, 0x0000, 0x0000, 0x0000, 0x0000, 0x0000, 0x0000, 0x0000, 0x0000, 0x0000, 0x0000,
  0x0000, 0x0000, 0x0000, 0x0000, 0x0000, 0x0000, 0x0000, 0x0000, 0x0000, 0x0000, 0x0000, 0x0000, 0x0000, 0x0000, 0x0000, 0x0000, 0x0000, 0x0000, 0x0000, 0x0000, 0x0000, 0x0000, 0x0000, 0x0000, 0xc1cd, 0x00ce, 0x00ce, 0x20b5, 0x619c, 0xa1a4, 0xe0cd, 0x00ce, 0x20b5, 0x619c, 0xa1a4, 0xe0cd, 0x00ce, 0x60bd, 0x619c, 0x0000, 0x0000, 0x00ce, 0x00ce, 0x80bd, 0x619c, 0x419c, 0x0000, 0xe0cd, 0x00ce, 0xc0cd, 0x81a4, 0x40b5, 0x00ce, 0xc0c5, 0x20b5, 0x819c, 0x80bd, 0x00ce, 0x80bd, 0x619c, 0x419c, 0x0000, 0x0000, 0x0000, 0x0000, 0x0000, 0x0000, 0x0000, 0x0000, 0x0000, 0x0000, 0x0000, 0x0000, 0x0000, 0x0000, 0x0000, 0x0000, 0x0000, 0x0000, 0x0000,
  0x0000, 0x0000, 0x0000, 0x0000, 0x0000, 0x0000, 0x0000, 0x0000, 0x0000, 0x0000, 0x0000, 0x0000, 0x0000, 0x0000, 0x0000, 0x0000, 0x0000, 0x0000, 0x0000, 0x0000, 0x0000, 0x0000, 0x0000, 0x0000, 0xc0d5, 0x00ce, 0xe0cd, 0xa0c5, 0x40bd, 0x60bd, 0xe0cd, 0x00ce, 0xa0c5, 0x40bd, 0x60bd, 0xe0cd, 0x00ce, 0x00d6, 0x0000, 0x0000, 0x0000, 0x00ce, 0x00ce, 0x80bd, 0x619c, 0x619c, 0x61a4, 0xe0cd, 0x00ce, 0xc0cd, 0x81a4, 0x419c, 0x00d6, 0x00ce, 0xe0cd, 0x60bd, 0xc0cd, 0x00ce, 0x80bd, 0x619c, 0x419c, 0x0000, 0x0000, 0x0000, 0x0000, 0x0000, 0x0000, 0x0000, 0x0000, 0x0000, 0x0000, 0x0000, 0x0000, 0x0000, 0x0000, 0x0000, 0x0000, 0x0000, 0x0000, 0x0000,
  0x0000, 0x0000, 0x0000, 0x0000, 0x0000, 0x0000, 0x0000, 0x0000, 0x0000, 0x0000, 0x0000, 0x0000, 0x0000, 0x0000, 0x0000, 0x0000, 0x0000, 0x0000, 0x0000, 0x0000, 0x0000, 0x0000, 0x0000, 0x0000, 0x0000, 0x0000, 0x00d6, 0x00ce, 0x00ce, 0x00ce, 0x00ce, 0xe0cd, 0x00ce, 0x00ce, 0x00ce, 0x00ce, 0xe1d5, 0x0000, 0x0000, 0xe0cd, 0x00ce, 0x00ce, 0x00ce, 0xc0cd, 0x60bd, 0xa1a4, 0x819c, 0xe0cd, 0x00ce, 0xe0cd, 0xc0ac, 0x819c, 0x0000, 0xe1d5, 0xe0cd, 0xe0cd, 0x00ce, 0x00ce, 0xc0c5, 0x619c, 0x009c, 0x0000, 0x0000, 0x0000, 0x0000, 0x0000, 0x0000, 0x0000, 0x0000, 0x0000, 0x0000, 0x0000, 0x0000, 0x0000, 0x0000, 0x0000, 0x0000, 0x0000, 0x0000, 0x0000,
  0x0000, 0x0000, 0x0000, 0x0000, 0x0000, 0x0000, 0x0000, 0x0000, 0x0000, 0x0000, 0x0000, 0x0000, 0x0000, 0x0000, 0x0000, 0x0000, 0x0000, 0x0000, 0x0000, 0x0000, 0x0000, 0x0000, 0x0000, 0x0000, 0x0000, 0x0000, 0x0000, 0x00d6, 0x00ce, 0x00ce, 0xe0bd, 0x0000, 0x00d6, 0x00ce, 0x00ce, 0xe0bd, 0x0000, 0x0000, 0x0000, 0xe0bd, 0x00ce, 0x00ce, 0x00ce, 0x00ce, 0x00ce, 0xe0bd, 0x0000, 0x00d6, 0x00ce, 0x00ce, 0xe0bd, 0x0000, 0x0000, 0x0000, 0x0000, 0x0000, 0xe0cd, 0x00ce, 0xe0cd, 0x0000, 0x0000, 0x0000, 0x0000, 0x0000, 0x0000, 0x0000, 0x0000, 0x0000, 0x0000, 0x0000, 0x0000, 0x0000, 0x0000, 0x0000, 0x0000, 0x0000, 0x0000, 0x0000, 0x0000, 0x0000,
  0x0000, 0x0000, 0x0000, 0x0000, 0x0000, 0x0000, 0x0000, 0x0000, 0x0000, 0x0000, 0x0000, 0x0000, 0x0000, 0x0000, 0x0000, 0x0000, 0x0000, 0x0000, 0x0000, 0x0000, 0x0000, 0x0000, 0x0000, 0x0000, 0x0000, 0x0000, 0x0000, 0x0000, 0x0000, 0x0000, 0x0000, 0x0000, 0x0000, 0x0000, 0x0000, 0x0000, 0x0000, 0x0000, 0x0000, 0x0000, 0x0000, 0x0000, 0x0000, 0x0000, 0x0000, 0x0000, 0x0000, 0x0000, 0x0000, 0x0000, 0x0000, 0x0000, 0x0000, 0x0000, 0x0000, 0x0000, 0x0000, 0x0000, 0x0000, 0x0000, 0x0000, 0x0000, 0x0000, 0x0000, 0x0000, 0x0000, 0x0000, 0x0000, 0x0000, 0x0000, 0x0000, 0x0000, 0x0000, 0x0000, 0x0000, 0x0000, 0x0000, 0x0000, 0x0000, 0x0000,
  0x0000, 0x0000, 0x0000, 0x0000, 0x0000, 0x0000, 0x0000, 0x0000, 0x0000, 0x0000, 0x0000, 0x0000, 0x0000, 0x0000, 0x0000, 0x0000, 0x0000, 0x0000, 0x0000, 0x0000, 0x0000, 0x0000, 0x0000, 0x0000, 0x0000, 0x0000, 0x0000, 0x0000, 0x0000, 0x0000, 0x0000, 0x0000, 0x0000, 0x0000, 0x0000, 0x0000, 0x0000, 0x0000, 0x0000, 0x0000, 0x0000, 0x0000, 0x0000, 0x0000, 0x0000, 0x0000, 0x0000, 0x0000, 0x0000, 0x0000, 0x0000, 0x0000, 0x0000, 0x0000, 0x0000, 0x0000, 0x0000, 0x0000, 0x0000, 0x0000, 0x0000, 0x0000, 0x0000, 0x0000, 0x0000, 0x0000, 0x0000, 0x0000, 0x0000, 0x0000, 0x0000, 0x0000, 0x0000, 0x0000, 0x0000, 0x0000, 0x0000, 0x0000, 0x0000, 0x0000,
  0x0000, 0x0000, 0x0000, 0x0000, 0x0000, 0x0000, 0x0000, 0x0000, 0x0000, 0x0000, 0x0000, 0x0000, 0x0000, 0x0000, 0x0000, 0x0000, 0x0000, 0x0000, 0x0000, 0x0000, 0x0000, 0x0000, 0x0000, 0x0000, 0x0000, 0x0000, 0x0000, 0x0000, 0x0000, 0x0000, 0x0000, 0x0000, 0x0000, 0x0000, 0x0000, 0x0000, 0x0000, 0x0000, 0x0000, 0x0000, 0x0000, 0x0000, 0x0000, 0x0000, 0x0000, 0x0000, 0x0000, 0x0000, 0x0000, 0x0000, 0x0000, 0x0000, 0x0000, 0x0000, 0x0000, 0x0000, 0x0000, 0x0000, 0x0000, 0x0000, 0x0000, 0x0000, 0x0000, 0x0000, 0x0000, 0x0000, 0x0000, 0x0000, 0x0000, 0x0000, 0x0000, 0x0000, 0x0000, 0x0000, 0x0000, 0x0000, 0x0000, 0x0000, 0x0000, 0x0000,
  0x0000, 0x0000, 0x0000, 0x0000, 0x0000, 0x0000, 0x0000, 0x0000, 0x0000, 0x0000, 0x0000, 0x0000, 0x0000, 0x0000, 0x0000, 0x0000, 0x0000, 0x0000, 0x0000, 0x0000, 0x0000, 0x0000, 0x0000, 0x0000, 0x0000, 0x0000, 0x0000, 0x0000, 0x0000, 0x0000, 0x0000, 0x0000, 0x0000, 0x0000, 0x0000, 0x0000, 0x0000, 0x0000, 0x0000, 0x0000, 0x0000, 0x0000, 0x0000, 0x0000, 0x0000, 0x0000, 0x0000, 0x0000, 0x0000, 0x0000, 0x0000, 0x0000, 0x0000, 0x0000, 0x0000, 0x0000, 0x0000, 0x0000, 0x0000, 0x0000, 0x0000, 0x0000, 0x0000, 0x0000, 0x0000, 0x0000, 0x0000, 0x0000, 0x0000, 0x0000, 0x0000, 0x0000, 0x0000, 0x0000, 0x0000, 0x0000, 0x0000, 0x0000, 0x0000, 0x0000,
  0x0000, 0x0000, 0x0000, 0x0000, 0x0000, 0x0000, 0x0000, 0x0000, 0x0000, 0x0000, 0x0000, 0x0000, 0x0000, 0x0000, 0x0000, 0x0000, 0x0000, 0x0000, 0x0000, 0x0000, 0x0000, 0x0000, 0x0000, 0x0000, 0x0000, 0x0000, 0x0000, 0x0000, 0x0000, 0x0000, 0x0000, 0x0000, 0x0000, 0x0000, 0x0000, 0x0000, 0x0000, 0x0000, 0x0000, 0x0000, 0x0000, 0x0000, 0x0000, 0x0000, 0x0000, 0x0000, 0x0000, 0x0000, 0x0000, 0x0000, 0x0000, 0x0000, 0x0000, 0x0000, 0x0000, 0x0000, 0x0000, 0x0000, 0x0000, 0x0000, 0x0000, 0x0000, 0x0000, 0x0000, 0x0000, 0x0000, 0x0000, 0x0000, 0x0000, 0x0000, 0x0000, 0x0000, 0x0000, 0x0000, 0x0000, 0x0000, 0x0000, 0x0000, 0x0000, 0x0000,
  0x0000, 0x0000, 0x0000, 0x0000, 0x0000, 0x0000, 0x0000, 0x0000, 0x0000, 0x0000, 0x0000, 0x0000, 0x0000, 0x0000, 0x0000, 0x0000, 0x0000, 0x0000, 0x0000, 0x0000, 0x0000, 0x0000, 0x0000, 0x0000, 0x0000, 0x0000, 0x0000, 0x0000, 0x0000, 0x0000, 0x0000, 0x0000, 0x0000, 0x0000, 0x0000, 0x0000, 0x0000, 0x0000, 0x0000, 0x0000, 0x0000, 0x0000, 0x0000, 0x0000, 0x0000, 0x0000, 0x0000, 0x0000, 0x0000, 0x0000, 0x0000, 0x0000, 0x0000, 0x0000, 0x0000, 0x0000, 0x0000, 0x0000, 0x0000, 0x0000, 0x0000, 0x0000, 0x0000, 0x0000, 0x0000, 0x0000, 0x0000, 0x0000, 0x0000, 0x0000, 0x0000, 0x0000, 0x0000, 0x0000, 0x0000, 0x0000, 0x0000, 0x0000, 0x0000, 0x0000,
  0x0000, 0x0000, 0x0000, 0x0000, 0x0000, 0x0000, 0x0000, 0x0000, 0x0000, 0x0000, 0x0000, 0x0000, 0x0000, 0x0000, 0x0000, 0x0000, 0x0000, 0x0000, 0x0000, 0x0000, 0x0000, 0x0000, 0x0000, 0x0000, 0x0000, 0x0000, 0x0000, 0x0000, 0x0000, 0x0000, 0x0000, 0x0000, 0x0000, 0x0000, 0x0000, 0x0000, 0x0000, 0x0000, 0x0000, 0x0000, 0x0000, 0x0000, 0x0000, 0x0000, 0x0000, 0x0000, 0x0000, 0x0000, 0x0000, 0x0000, 0x0000, 0x0000, 0x0000, 0x0000, 0x0000, 0x0000, 0x0000, 0x0000, 0x0000, 0x0000, 0x0000, 0x0000, 0x0000, 0x0000, 0x0000, 0x0000, 0x0000, 0x0000, 0x0000, 0x0000, 0x0000, 0x0000, 0x0000, 0x0000, 0x0000, 0x0000, 0x0000, 0x0000, 0x0000, 0x0000,
  0x0000, 0x0000, 0x0000, 0x0000, 0x0000, 0x0000, 0x0000, 0x0000, 0x0000, 0x0000, 0x0000, 0x0000, 0x0000, 0x0000, 0x0000, 0x0000, 0x0000, 0x0000, 0x0000, 0x0000, 0x0000, 0x0000, 0x0000, 0x0000, 0x0000, 0x0000, 0x0000, 0x0000, 0x0000, 0x0000, 0x0000, 0x0000, 0x0000, 0x0000, 0x0000, 0x0000, 0x0000, 0x0000, 0x0000, 0x0000, 0x0000, 0x0000, 0x0000, 0x0000, 0x0000, 0x0000, 0x0000, 0x0000, 0x0000, 0x0000, 0x0000, 0x0000, 0x0000, 0x0000, 0x0000, 0x0000, 0x0000, 0x0000, 0x0000, 0x0000, 0x0000, 0x0000, 0x0000, 0x0000, 0x0000, 0x0000, 0x0000, 0x0000, 0x0000, 0x0000, 0x0000, 0x0000, 0x0000, 0x0000, 0x0000, 0x0000, 0x0000, 0x0000, 0x0000, 0x0000,
  0x0000, 0x0000, 0x0000, 0x0000, 0x0000, 0x0000, 0x0000, 0x0000, 0x0000, 0x0000, 0x0000, 0x0000, 0x0000, 0x0000, 0x0000, 0x0000, 0x0000, 0x0000, 0x0000, 0x0000, 0x0000, 0x0000, 0x0000, 0x0000, 0x0000, 0x0000, 0x0000, 0x0000, 0x0000, 0x0000, 0x0000, 0x0000, 0x0000, 0x0000, 0x0000, 0x0000, 0x0000, 0x0000, 0x0000, 0x0000, 0x0000, 0x0000, 0x0000, 0x0000, 0x0000, 0x0000, 0x0000, 0x0000, 0x0000, 0x0000, 0x0000, 0x0000, 0x0000, 0x0000, 0x0000, 0x0000, 0x0000, 0x0000, 0x0000, 0x0000, 0x0000, 0x0000, 0x0000, 0x0000, 0x0000, 0x0000, 0x0000, 0x0000, 0x0000, 0x0000, 0x0000, 0x0000, 0x0000, 0x0000, 0x0000, 0x0000, 0x0000, 0x0000, 0x0000, 0x0000,
  0x0000, 0x0000, 0x0000, 0x0000, 0x0000, 0x0000, 0x0000, 0x0000, 0x0000, 0x0000, 0x0000, 0x0000, 0x0000, 0x0000, 0x0000, 0x0000, 0x0000, 0x0000, 0x0000, 0x0000, 0x0000, 0x0000, 0x0000, 0x0000, 0x0000, 0x0000, 0x0000, 0x0000, 0x0000, 0x0000, 0x0000, 0x0000, 0x0000, 0x0000, 0x0000, 0x0000, 0x0000, 0x0000, 0x0000, 0x0000, 0x0000, 0x0000, 0x0000, 0x0000, 0x0000, 0x0000, 0x0000, 0x0000, 0x0000, 0x0000, 0x0000, 0x0000, 0x0000, 0x0000, 0x0000, 0x0000, 0x0000, 0x0000, 0x0000, 0x0000, 0x0000, 0x0000, 0x0000, 0x0000, 0x0000, 0x0000, 0x0000, 0x0000, 0x0000, 0x0000, 0x0000, 0x0000, 0x0000, 0x0000, 0x0000, 0x0000, 0x0000, 0x0000, 0x0000, 0x0000,
  0x0000, 0x0000, 0x0000, 0x0000, 0x0000, 0x0000, 0x0000, 0x0000, 0x0000, 0x0000, 0x0000, 0x0000, 0x0000, 0x0000, 0x0000, 0x0000, 0x0000, 0x0000, 0x0000, 0x0000, 0x0000, 0x0000, 0x0000, 0x0000, 0x0000, 0x0000, 0x0000, 0x0000, 0x0000, 0x0000, 0x0000, 0x0000, 0x0000, 0x0000, 0x0000, 0x0000, 0x0000, 0x0000, 0x0000, 0x0000, 0x0000, 0x0000, 0x0000, 0x0000, 0x0000, 0x0000, 0x0000, 0x0000, 0x0000, 0x0000, 0x0000, 0x0000, 0x0000, 0x0000, 0x0000, 0x0000, 0x0000, 0x0000, 0x0000, 0x0000, 0x0000, 0x0000, 0x0000, 0x0000, 0x0000, 0x0000, 0x0000, 0x0000, 0x0000, 0x0000, 0x0000, 0x0000, 0x0000, 0x0000, 0x0000, 0x0000, 0x0000, 0x0000, 0x0000, 0x0000,
  0x0000, 0x0000, 0x0000, 0x0000, 0x0000, 0x0000, 0x0000, 0x0000, 0x0000, 0x0000, 0x0000, 0x0000, 0x0000, 0x0000, 0x0000, 0x0000, 0x0000, 0x0000, 0x0000, 0x0000, 0x0000, 0x0000, 0x0000, 0x0000, 0x0000, 0x0000, 0x0000, 0x0000, 0x0000, 0x0000, 0x0000, 0x0000, 0x0000, 0x0000, 0x0000, 0x0000, 0x0000, 0x0000, 0x0000, 0x0000, 0x0000, 0x0000, 0x0000, 0x0000, 0x0000, 0x0000, 0x0000, 0x0000, 0x0000, 0x0000, 0x0000, 0x0000, 0x0000, 0x0000, 0x0000, 0x0000, 0x0000, 0x0000, 0x0000, 0x0000, 0x0000, 0x0000, 0x0000, 0x0000, 0x0000, 0x0000, 0x0000, 0x0000, 0x0000, 0x0000, 0x0000, 0x0000, 0x0000, 0x0000, 0x0000, 0x0000, 0x0000, 0x0000, 0x0000, 0x0000,
  0x0000, 0x0000, 0x0000, 0x0000, 0x0000, 0x0000, 0x0000, 0x0000, 0x0000, 0x0000, 0x0000, 0x0000, 0x0000, 0x0000, 0x0000, 0x0000, 0x0000, 0x0000, 0x0000, 0x0000, 0x0000, 0x0000, 0x0000, 0x0000, 0x0000, 0x0000, 0x0000, 0x0000, 0x0000, 0x0000, 0x0000, 0x0000, 0x0000, 0x0000, 0x0000, 0x0000, 0x0000, 0x0000, 0x0000, 0x0000, 0x0000, 0x0000, 0x0000, 0x0000, 0x0000, 0x0000, 0x0000, 0x0000, 0x0000, 0x0000, 0x0000, 0x0000, 0x0000, 0x0000, 0x0000, 0x0000, 0x0000, 0x0000, 0x0000, 0x0000, 0x0000, 0x0000, 0x0000, 0x0000, 0x0000, 0x0000, 0x0000, 0x0000, 0x0000, 0x0000, 0x0000, 0x0000, 0x0000, 0x0000, 0x0000, 0x0000, 0x0000, 0x0000, 0x0000, 0x0000,
  0x0000, 0x0000, 0x0000, 0x0000, 0x0000, 0x0000, 0x0000, 0x0000, 0x0000, 0x0000, 0x0000, 0x0000, 0x0000, 0x0000, 0x0000, 0x0000, 0x0000, 0x0000, 0x0000, 0x0000, 0x0000, 0x0000, 0x0000, 0x0000, 0x0000, 0x0000, 0x0000, 0x0000, 0x0000, 0x0000, 0x0000, 0x0000, 0x0000, 0x0000, 0x0000, 0x0000, 0x0000, 0x0000, 0x0000, 0x0000, 0x0000, 0x0000, 0x0000, 0x0000, 0x0000, 0x0000, 0x0000, 0x0000, 0x0000, 0x0000, 0x0000, 0x0000, 0x0000, 0x0000, 0x0000, 0x0000, 0x0000, 0x0000, 0x0000, 0x0000, 0x0000, 0x0000, 0x0000, 0x0000, 0x0000, 0x0000, 0x0000, 0x0000, 0x0000, 0x0000, 0x0000, 0x0000, 0x0000, 0x0000, 0x0000, 0x0000, 0x0000, 0x0000, 0x0000, 0x0000,
  0x0000, 0x0000, 0x0000, 0x0000, 0x0000, 0x0000, 0x0000, 0x0000, 0x0000, 0x0000, 0x0000, 0x0000, 0x0000, 0x0000, 0x0000, 0x0000, 0x0000, 0x0000, 0x0000, 0x0000, 0x0000, 0x0000, 0x0000, 0x0000, 0x0000, 0x0000, 0x0000, 0x0000, 0x0000, 0x0000, 0x0000, 0x0000, 0x0000, 0x0000, 0x0000, 0x0000, 0x0000, 0x0000, 0x0000, 0x0000, 0x0000, 0x0000, 0x0000, 0x0000, 0x0000, 0x0000, 0x0000, 0x0000, 0x0000, 0x0000, 0x0000, 0x0000, 0x0000, 0x0000, 0x0000, 0x0000, 0x0000, 0x0000, 0x0000, 0x0000, 0x0000, 0x0000, 0x0000, 0x0000, 0x0000, 0x0000, 0x0000, 0x0000, 0x0000, 0x0000, 0x0000, 0x0000, 0x0000, 0x0000, 0x0000, 0x0000, 0x0000, 0x0000, 0x0000, 0x0000,
  0x0000, 0x0000, 0x0000, 0x0000, 0x0000, 0x0000, 0x0000, 0x0000, 0x0000, 0x0000, 0x0000, 0x0000, 0x0000, 0x0000, 0x0000, 0x0000, 0x0000, 0x0000, 0x0000, 0x0000, 0x0000, 0x0000, 0x0000, 0x0000, 0x0000, 0x0000, 0x0000, 0x0000, 0x0000, 0x0000, 0x0000, 0x0000, 0x0000, 0x0000, 0x0000, 0x0000, 0x0000, 0x0000, 0x0000, 0x0000, 0x0000, 0x0000, 0x0000, 0x0000, 0x0000, 0x0000, 0x0000, 0x0000, 0x0000, 0x0000, 0x0000, 0x0000, 0x0000, 0x0000, 0x0000, 0x0000, 0x0000, 0x0000, 0x0000, 0x0000, 0x0000, 0x0000, 0x0000, 0x0000, 0x0000, 0x0000, 0x0000, 0x0000, 0x0000, 0x0000, 0x0000, 0x0000, 0x0000, 0x0000, 0x0000, 0x0000, 0x0000, 0x0000, 0x0000, 0x0000,
  0x0000, 0x0000, 0x0000, 0x0000, 0x0000, 0x0000, 0x0000, 0x0000, 0x0000, 0x0000, 0x0000, 0x0000, 0x0000, 0x0000, 0x0000, 0x0000, 0x0000, 0x0000, 0x0000, 0x0000, 0x0000, 0x0000, 0x0000, 0x0000, 0x0000, 0x0000, 0x0000, 0x0000, 0x0000, 0x0000, 0x0000, 0x0000, 0x0000, 0x0000, 0x0000, 0x0000, 0x0000, 0x0000, 0x0000, 0x0000, 0x0000, 0x0000, 0x0000, 0x0000, 0x0000, 0x0000, 0x0000, 0x0000, 0x0000, 0x0000, 0x0000, 0x0000, 0x0000, 0x0000, 0x0000, 0x0000, 0x0000, 0x0000, 0x0000, 0x0000, 0x0000, 0x0000, 0x0000, 0x0000, 0x0000, 0x0000, 0x0000, 0x0000, 0x0000, 0x0000, 0x0000, 0x0000, 0x0000, 0x0000, 0x0000, 0x0000, 0x0000, 0x0000, 0x0000, 0x0000,
  0x0000, 0x0000, 0x0000, 0x0000, 0x0000, 0x0000, 0x0000, 0x0000, 0x0000, 0x0000, 0x0000, 0x0000, 0x0000, 0x0000, 0x0000, 0x0000, 0x0000, 0x0000, 0x0000, 0x0000, 0x0000, 0x0000, 0x0000, 0x0000, 0x0000, 0x0000, 0x0000, 0x0000, 0x0000, 0x0000, 0x0000, 0x0000, 0x0000, 0x0000, 0x0000, 0x0000, 0x0000, 0x0000, 0x0000, 0x0000, 0x0000, 0x0000, 0x0000, 0x0000, 0x0000, 0x0000, 0x0000, 0x0000, 0x0000, 0x0000, 0x0000, 0x0000, 0x0000, 0x0000, 0x0000, 0x0000, 0x0000, 0x0000, 0x0000, 0x0000, 0x0000, 0x0000, 0x0000, 0x0000, 0x0000, 0x0000, 0x0000, 0x0000, 0x0000, 0x0000, 0x0000, 0x0000, 0x0000, 0x0000, 0x0000, 0x0000, 0x0000, 0x0000, 0x0000, 0x0000,
  0x0000, 0x0000, 0x0000, 0x0000, 0x0000, 0x0000, 0x0000, 0x0000, 0x0000, 0x0000, 0x0000, 0x0000, 0x0000, 0x0000, 0x0000, 0x0000, 0x0000, 0x0000, 0x0000, 0x0000, 0x0000, 0x0000, 0x0000, 0x0000, 0x0000, 0x0000, 0x0000, 0x0000, 0x0000, 0x0000, 0x0000, 0x0000, 0x0000, 0x0000, 0x0000, 0x0000, 0x0000, 0x0000, 0x0000, 0x0000, 0x0000, 0x0000, 0x0000, 0x0000, 0x0000, 0x0000, 0x0000, 0x0000, 0x0000, 0x0000, 0x0000, 0x0000, 0x0000, 0x0000, 0x0000, 0x0000, 0x0000, 0x0000, 0x0000, 0x0000, 0x0000, 0x0000, 0x0000, 0x0000, 0x0000, 0x0000, 0x0000, 0x0000, 0x0000, 0x0000, 0x0000, 0x0000, 0x0000, 0x0000, 0x0000, 0x0000, 0x0000, 0x0000, 0x0000, 0x0000
};

static const uint16_t ImagemVitoria3[][60*80/2] = {
  0x0000, 0x0000, 0x0000, 0x0000, 0x0000, 0x0000, 0x0000, 0x0000, 0x0000, 0x0000, 0x0000, 0x0000, 0x0000, 0x0000, 0x0000, 0x0000, 0x0000, 0x0000, 0x0000, 0x0000, 0x0000, 0x0000, 0x0000, 0x0000, 0x0000, 0x0000, 0x0000, 0x0000, 0x0000, 0x0000, 0x0000, 0x0000, 0x0000, 0x0000, 0x0000, 0x0000, 0x0000, 0x0000, 0x0000, 0x0000, 0x0000, 0x0000, 0x0000, 0x0000, 0x0000, 0x0000, 0x0000, 0x0000, 0x0000, 0x0000, 0x0000, 0x0000, 0x0000, 0x0000, 0x0000, 0x0000, 0x0000, 0x0000, 0x0000, 0x0000, 0x0000, 0x0000, 0x0000, 0x0000, 0x0000, 0x0000, 0x0000, 0x0000, 0x0000, 0x0000, 0x0000, 0x0000, 0x0000, 0x0000, 0x0000, 0x0000, 0x0000, 0x0000, 0x0000, 0x0000,
  0x0000, 0x0000, 0x0000, 0x0000, 0x0000, 0x0000, 0x0000, 0x0000, 0x0000, 0x0000, 0x0000, 0x0000, 0x0000, 0x0000, 0x0000, 0x0000, 0x0000, 0x0000, 0x0000, 0x0000, 0x0000, 0x0000, 0x0000, 0x0000, 0x0000, 0x0000, 0x0000, 0x0000, 0x0000, 0x0000, 0x0000, 0x0000, 0x0000, 0x0000, 0x0000, 0x0000, 0x0000, 0x0000, 0x0000, 0x0000, 0x0000, 0x0000, 0x0000, 0x0000, 0x0000, 0x0000, 0x0000, 0x0000, 0x0000, 0x0000, 0x0000, 0x0000, 0x0000, 0x0000, 0x0000, 0x0000, 0x0000, 0x0000, 0x0000, 0x0000, 0x0000, 0x0000, 0x0000, 0x0000, 0x0000, 0x0000, 0x0000, 0x0000, 0x0000, 0x0000, 0x0000, 0x0000, 0x0000, 0x0000, 0x0000, 0x0000, 0x0000, 0x0000, 0x0000, 0x0000,
  0x0000, 0x0000, 0x0000, 0x0000, 0x0000, 0x0000, 0x0000, 0x0000, 0x0000, 0x0000, 0x0000, 0x0000, 0x0000, 0x0000, 0x0000, 0x0000, 0x0000, 0x0000, 0x0000, 0x0000, 0x0000, 0x0000, 0x0000, 0x0000, 0x0000, 0x0000, 0x0000, 0x0000, 0x0000, 0x0000, 0x0000, 0x0000, 0x0000, 0x0000, 0x0000, 0x0000, 0x0000, 0x0000, 0x0000, 0x0000, 0x0000, 0x0000, 0x0000, 0x0000, 0x0000, 0x0000, 0x0000, 0x0000, 0x0000, 0x0000, 0x0000, 0x0000, 0x0000, 0x0000, 0x0000, 0x0000, 0x0000, 0x0000, 0x0000, 0x0000, 0x0000, 0x0000, 0x0000, 0x0000, 0x0000, 0x0000, 0x0000, 0x0000, 0x0000, 0x0000, 0x0000, 0x0000, 0x0000, 0x0000, 0x0000, 0x0000, 0x0000, 0x0000, 0x0000, 0x0000,
  0x0000, 0x0000, 0x0000, 0x0000, 0x0000, 0x0000, 0x0000, 0x0000, 0x0000, 0x0000, 0x0000, 0x0000, 0x0000, 0x0000, 0x0000, 0x0000, 0x0000, 0x0000, 0x0000, 0x0000, 0x0000, 0x0000, 0x0000, 0x0000, 0x0000, 0x0000, 0x0000, 0x0000, 0x0000, 0x0000, 0x0000, 0x0000, 0x0000, 0x0000, 0x0000, 0x0000, 0x0000, 0x0000, 0x0000, 0x0000, 0x0000, 0x0000, 0x0000, 0x0000, 0x0000, 0x0000, 0x0000, 0x0000, 0x0000, 0x0000, 0x0000, 0x0000, 0x0000, 0x0000, 0x0000, 0x0000, 0x0000, 0x0000, 0x0000, 0x0000, 0x0000, 0x0000, 0x0000, 0x0000, 0x0000, 0x0000, 0x0000, 0x0000, 0x0000, 0x0000, 0x0000, 0x0000, 0x0000, 0x0000, 0x0000, 0x0000, 0x0000, 0x0000, 0x0000, 0x0000,
  0x0000, 0x0000, 0x0000, 0x0000, 0x0000, 0x0000, 0x0000, 0x0000, 0x0000, 0x0000, 0x0000, 0x0000, 0x0000, 0x0000, 0x0000, 0x0000, 0x0000, 0x0000, 0x0000, 0x0000, 0x0000, 0x0000, 0x0000, 0x0000, 0x0000, 0x0000, 0x0000, 0x0000, 0x0000, 0x0000, 0x0000, 0x0000, 0x0000, 0x0000, 0x0000, 0x0000, 0x0000, 0x0000, 0x0000, 0x0000, 0x0000, 0x0000, 0x0000, 0x0000, 0x0000, 0x0000, 0x0000, 0x0000, 0x0000, 0x0000, 0x0000, 0x0000, 0x0000, 0x0000, 0x0000, 0x0000, 0x0000, 0x0000, 0x0000, 0x0000, 0x0000, 0x0000, 0x0000, 0x0000, 0x0000, 0x0000, 0x0000, 0x0000, 0x0000, 0x0000, 0x0000, 0x0000, 0x0000, 0x0000, 0x0000, 0x0000, 0x0000, 0x0000, 0x0000, 0x0000,
  0x0000, 0x0000, 0x0000, 0x0000, 0x0000, 0x0000, 0x0000, 0x0000, 0x0000, 0x0000, 0x0000, 0x0000, 0x0000, 0x0000, 0x0000, 0x0000, 0x0000, 0x0000, 0x0000, 0x0000, 0x0000, 0x0000, 0x0000, 0x0000, 0x0000, 0x0000, 0x0000, 0x0000, 0x0000, 0x0000, 0x0000, 0x0000, 0x0000, 0x0000, 0x0000, 0x0000, 0x0000, 0x0000, 0x0000, 0x0000, 0x0000, 0x0000, 0x0000, 0x0000, 0x0000, 0x0000, 0x0000, 0x0000, 0x0000, 0x0000, 0x0000, 0x0000, 0x0000, 0x0000, 0x0000, 0x0000, 0x0000, 0x0000, 0x0000, 0x0000, 0x0000, 0x0000, 0x0000, 0x0000, 0x0000, 0x0000, 0x0000, 0x0000, 0x0000, 0x0000, 0x0000, 0x0000, 0x0000, 0x0000, 0x0000, 0x0000, 0x0000, 0x0000, 0x0000, 0x0000,
  0x0000, 0x0000, 0x0000, 0x0000, 0x0000, 0x0000, 0x0000, 0x0000, 0x0000, 0x0000, 0x0000, 0x0000, 0x0000, 0x0000, 0x0000, 0x0000, 0x0000, 0x0000, 0x0000, 0x0000, 0x0000, 0x0000, 0x0000, 0x0000, 0x0000, 0x0000, 0x0000, 0x0000, 0x0000, 0x0000, 0x0000, 0x0000, 0x0000, 0x0000, 0x0000, 0x0000, 0x0000, 0x0000, 0x0000, 0x0000, 0x0000, 0x0000, 0x0000, 0x0000, 0x0000, 0x0000, 0x0000, 0x0000, 0x0000, 0x0000, 0x0000, 0x0000, 0x0000, 0x0000, 0x0000, 0x0000, 0x0000, 0x0000, 0x0000, 0x0000, 0x0000, 0x0000, 0x0000, 0x0000, 0x0000, 0x0000, 0x0000, 0x0000, 0x0000, 0x0000, 0x0000, 0x0000, 0x0000, 0x0000, 0x0000, 0x0000, 0x0000, 0x0000, 0x0000, 0x0000,
  0x0000, 0x0000, 0x0000, 0x0000, 0x0000, 0x0000, 0x0000, 0x0000, 0x0000, 0x0000, 0x0000, 0x0000, 0x0000, 0x0000, 0x0000, 0x0000, 0x0000, 0x0000, 0x0000, 0x0000, 0x0000, 0x0000, 0x0000, 0x0000, 0x0000, 0x0000, 0x0000, 0x0000, 0x0000, 0x0000, 0x0000, 0x0000, 0x0000, 0x0000, 0x0000, 0x0000, 0x0000, 0x0000, 0x0000, 0x0000, 0x0000, 0x0000, 0x0000, 0x0000, 0x0000, 0x0000, 0x0000, 0x0000, 0x0000, 0x0000, 0x0000, 0x0000, 0x0000, 0x0000, 0x0000, 0x0000, 0x0000, 0x0000, 0x0000, 0x0000, 0x0000, 0x0000, 0x0000, 0x0000, 0x0000, 0x0000, 0x0000, 0x0000, 0x0000, 0x0000, 0x0000, 0x0000, 0x0000, 0x0000, 0x0000, 0x0000, 0x0000, 0x0000, 0x0000, 0x0000,
  0x0000, 0x0000, 0x0000, 0x0000, 0x0000, 0x0000, 0x0000, 0x0000, 0x0000, 0x0000, 0x0000, 0x0000, 0x0000, 0x0000, 0x0000, 0x0000, 0x0000, 0x0000, 0x0000, 0x0000, 0x0000, 0x0000, 0x0000, 0x0000, 0x0000, 0x0000, 0x0000, 0x0000, 0x0000, 0x0000, 0x0000, 0x0000, 0x0000, 0x0000, 0x0000, 0x0000, 0x0000, 0x0000, 0x0000, 0x0000, 0x0000, 0x0000, 0x0000, 0x0000, 0x0000, 0x0000, 0x0000, 0x0000, 0x0000, 0x0000, 0x0000, 0x0000, 0x0000, 0x0000, 0x0000, 0x0000, 0x0000, 0x0000, 0x0000, 0x0000, 0x0000, 0x0000, 0x0000, 0x0000, 0x0000, 0x0000, 0x0000, 0x0000, 0x0000, 0x0000, 0x0000, 0x0000, 0x0000, 0x0000, 0x0000, 0x0000, 0x0000, 0x0000, 0x0000, 0x0000,
  0x0000, 0x0000, 0x0000, 0x0000, 0x0000, 0x0000, 0x0000, 0x0000, 0x0000, 0x0000, 0x0000, 0x0000, 0x0000, 0x0000, 0x0000, 0x0000, 0x0000, 0x0000, 0x0000, 0x0000, 0x0000, 0x0000, 0x0000, 0x0000, 0x0000, 0x0000, 0x0000, 0x0000, 0x0000, 0x0000, 0x0000, 0x0000, 0x0000, 0x0000, 0x0000, 0x0000, 0x0000, 0x0000, 0x0000, 0x0000, 0x0000, 0x0000, 0x0000, 0x0000, 0x0000, 0x0000, 0x0000, 0x0000, 0x0000, 0x0000, 0x0000, 0x0000, 0x0000, 0x0000, 0x0000, 0x0000, 0x0000, 0x0000, 0x0000, 0x0000, 0x0000, 0x0000, 0x0000, 0x0000, 0x0000, 0x0000, 0x0000, 0x0000, 0x0000, 0x0000, 0x0000, 0x0000, 0x0000, 0x0000, 0x0000, 0x0000, 0x0000, 0x0000, 0x0000, 0x0000,
  0x0000, 0x0000, 0x0000, 0x0000, 0x0000, 0x0000, 0x0000, 0x0000, 0x0000, 0x0000, 0x0000, 0x0000, 0x0000, 0x0000, 0x0000, 0x0000, 0x0000, 0x0000, 0x0000, 0x0000, 0x0000, 0x0000, 0x0000, 0x0000, 0x0000, 0x0000, 0x0000, 0x0000, 0x0000, 0x0000, 0x0000, 0x0000, 0x0000, 0x0000, 0x0000, 0x0000, 0x0000, 0x0000, 0x0000, 0x0000, 0x0000, 0x0000, 0x0000, 0x0000, 0x0000, 0x0000, 0x0000, 0x0000, 0x0000, 0x0000, 0x0000, 0x0000, 0x0000, 0x0000, 0x0000, 0x0000, 0x0000, 0x0000, 0x0000, 0x0000, 0x0000, 0x0000, 0x0000, 0x0000, 0x0000, 0x0000, 0x0000, 0x0000, 0x0000, 0x0000, 0x0000, 0x0000, 0x0000, 0x0000, 0x0000, 0x0000, 0x0000, 0x0000, 0x0000, 0x0000,
  0x0000, 0x0000, 0x0000, 0x0000, 0x0000, 0x0000, 0x0000, 0x0000, 0x0000, 0x0000, 0x0000, 0x0000, 0x0000, 0x0000, 0x0000, 0x0000, 0x0000, 0x0000, 0x0000, 0x0000, 0x0000, 0x0000, 0x0000, 0x0000, 0x0000, 0x0000, 0x0000, 0x0000, 0x0000, 0x0000, 0x0000, 0x0000, 0x0000, 0x0000, 0x0000, 0x0000, 0x0000, 0x0000, 0x0000, 0x0000, 0x0000, 0x0000, 0x0000, 0x0000, 0x0000, 0x0000, 0x0000, 0x0000, 0x0000, 0x0000, 0x0000, 0x0000, 0x0000, 0x0000, 0x0000, 0x0000, 0x0000, 0x0000, 0x0000, 0x0000, 0x0000, 0x0000, 0x0000, 0x0000, 0x0000, 0x0000, 0x0000, 0x0000, 0x0000, 0x0000, 0x0000, 0x0000, 0x0000, 0x0000, 0x0000, 0x0000, 0x0000, 0x0000, 0x0000, 0x0000,
  0x0000, 0x0000, 0x0000, 0x0000, 0x0000, 0x0000, 0x0000, 0x0000, 0x0000, 0x0000, 0x0000, 0x0000, 0x0000, 0x0000, 0x0000, 0x0000, 0x0000, 0x0000, 0x0000, 0x0000, 0x0000, 0x0000, 0x0000, 0x0000, 0x0000, 0x0000, 0x0000, 0x0000, 0x0000, 0x0000, 0x0000, 0x0000, 0x0000, 0x0000, 0x0000, 0x0000, 0x0000, 0x0000, 0x0000, 0x0000, 0x0000, 0x0000, 0x0000, 0x0000, 0x0000, 0x0000, 0x0000, 0x0000, 0x0000, 0x0000, 0x0000, 0x0000, 0x0000, 0x0000, 0x0000, 0x0000, 0x0000, 0x0000, 0x0000, 0x0000, 0x0000, 0x0000, 0x0000, 0x0000, 0x0000, 0x0000, 0x0000, 0x0000, 0x0000, 0x0000, 0x0000, 0x0000, 0x0000, 0x0000, 0x0000, 0x0000, 0x0000, 0x0000, 0x0000, 0x0000,
  0x0000, 0x0000, 0x0000, 0x0000, 0x0000, 0x0000, 0x0000, 0x0000, 0x0000, 0x0000, 0x0000, 0x0000, 0x0000, 0x0000, 0x0000, 0x0000, 0x0000, 0x0000, 0x0000, 0x0000, 0x0000, 0x0000, 0x0000, 0x0000, 0x0000, 0x0000, 0x0000, 0x0000, 0x0000, 0x0000, 0x0000, 0x0000, 0x0000, 0x0000, 0x0000, 0x0000, 0x0000, 0x0000, 0x0000, 0x0000, 0x0000, 0x0000, 0x0000, 0x0000, 0x0000, 0x0000, 0x0000, 0x0000, 0x0000, 0x0000, 0x0000, 0x0000, 0x0000, 0x0000, 0x0000, 0x0000, 0x0000, 0x0000, 0x0000, 0x0000, 0x0000, 0x0000, 0x0000, 0x0000, 0x0000, 0x0000, 0x0000, 0x0000, 0x0000, 0x0000, 0x0000, 0x0000, 0x0000, 0x0000, 0x0000, 0x0000, 0x0000, 0x0000, 0x0000, 0x0000,
  0x0000, 0x0000, 0x0000, 0x0000, 0x0000, 0x0000, 0x0000, 0x0000, 0x0000, 0x0000, 0x0000, 0x0000, 0x0000, 0x0000, 0x0000, 0x0000, 0x0000, 0x0000, 0x0000, 0x0000, 0x0000, 0x0000, 0x0000, 0x0000, 0x0000, 0x0000, 0x0000, 0x0000, 0x0000, 0x0000, 0x0000, 0x0000, 0x0000, 0x0000, 0x0000, 0x0000, 0x0000, 0x0000, 0x0000, 0x0000, 0x0000, 0x0000, 0x0000, 0x0000, 0x0000, 0x0000, 0x0000, 0x0000, 0x0000, 0x0000, 0x0000, 0x0000, 0x0000, 0x0000, 0x0000, 0x0000, 0x0000, 0x0000, 0x0000, 0x0000, 0x0000, 0x0000, 0x0000, 0x0000, 0x0000, 0x0000, 0x0000, 0x0000, 0x0000, 0x0000, 0x0000, 0x0000, 0x0000, 0x0000, 0x0000, 0x0000, 0x0000, 0x0000, 0x0000, 0x0000,
  0x0000, 0x0000, 0x0000, 0x0000, 0x0000, 0x0000, 0x0000, 0x0000, 0x0000, 0x0000, 0x0000, 0x0000, 0x0000, 0x0000, 0x0000, 0x0000, 0x0000, 0x0000, 0x0000, 0x0000, 0x0000, 0x0000, 0x0000, 0x0000, 0x0000, 0x0000, 0x0000, 0x0000, 0x0000, 0x0000, 0x0000, 0x0000, 0x0000, 0x0000, 0x0000, 0x0000, 0x0000, 0x0000, 0x0000, 0x0000, 0x0000, 0x0000, 0x0000, 0x0000, 0x0000, 0x0000, 0x0000, 0x0000, 0x0000, 0x0000, 0x0000, 0x0000, 0x0000, 0x0000, 0x0000, 0x0000, 0x0000, 0x0000, 0x0000, 0x0000, 0x0000, 0x0000, 0x0000, 0x0000, 0x0000, 0x0000, 0x0000, 0x0000, 0x0000, 0x0000, 0x0000, 0x0000, 0x0000, 0x0000, 0x0000, 0x0000, 0x0000, 0x0000, 0x0000, 0x0000,
  0x0000, 0x0000, 0x0000, 0x0000, 0x0000, 0x0000, 0x0000, 0x0000, 0x0000, 0x0000, 0x0000, 0x0000, 0x0000, 0x0000, 0x0000, 0x0000, 0x0000, 0x0000, 0x0000, 0x0000, 0x0000, 0x0000, 0x0000, 0x0000, 0x0000, 0x0000, 0x0000, 0x0000, 0x0000, 0x0000, 0x0000, 0x0000, 0x0000, 0x0000, 0x0000, 0x0000, 0x0000, 0x0000, 0x0000, 0x0000, 0x0000, 0x0000, 0x0000, 0x0000, 0x0000, 0x0000, 0x0000, 0x0000, 0x0000, 0x0000, 0x0000, 0x0000, 0x0000, 0x0000, 0x0000, 0x0000, 0x0000, 0x0000, 0x0000, 0x0000, 0x0000, 0x0000, 0x0000, 0x0000, 0x0000, 0x0000, 0x0000, 0x0000, 0x0000, 0x0000, 0x0000, 0x0000, 0x0000, 0x0000, 0x0000, 0x0000, 0x0000, 0x0000, 0x0000, 0x0000,
  0x0000, 0x0000, 0x0000, 0x0000, 0x0000, 0x0000, 0x0000, 0x0000, 0x0000, 0x0000, 0x0000, 0x0000, 0x0000, 0x0000, 0x0000, 0x0000, 0x0000, 0x0000, 0x0000, 0x0000, 0x0000, 0x0000, 0x0000, 0x0000, 0x0000, 0x0000, 0x0000, 0x0000, 0x0000, 0x0000, 0x0000, 0x0000, 0x0000, 0x0000, 0x0000, 0x0000, 0x0000, 0x0000, 0x0000, 0x0000, 0x0000, 0x0000, 0x0000, 0x0000, 0x0000, 0x0000, 0x0000, 0x0000, 0x0000, 0x0000, 0x0000, 0x0000, 0x0000, 0x0000, 0x0000, 0x0000, 0x0000, 0x0000, 0x0000, 0x0000, 0x0000, 0x0000, 0x0000, 0x0000, 0x0000, 0x0000, 0x0000, 0x0000, 0x0000, 0x0000, 0x0000, 0x0000, 0x0000, 0x0000, 0x0000, 0x0000, 0x0000, 0x0000, 0x0000, 0x0000,
  0x0000, 0x0000, 0x0000, 0x0000, 0x0000, 0x0000, 0x0000, 0x0000, 0x0000, 0x0000, 0x0000, 0x0000, 0x0000, 0x0000, 0x0000, 0x0000, 0x0000, 0x0000, 0x0000, 0x0000, 0x0000, 0x0000, 0x0000, 0x0000, 0x0000, 0x0000, 0x0000, 0x0000, 0x0000, 0x0000, 0x0000, 0x0000, 0x0000, 0x0000, 0x0000, 0x0000, 0x0000, 0x0000, 0x0000, 0x0000, 0x0000, 0x0000, 0x0000, 0x0000, 0x0000, 0x0000, 0x0000, 0x0000, 0x0000, 0x0000, 0x0000, 0x0000, 0x0000, 0x0000, 0x0000, 0x0000, 0x0000, 0x0000, 0x0000, 0x0000, 0x0000, 0x0000, 0x0000, 0x0000, 0x0000, 0x0000, 0x0000, 0x0000, 0x0000, 0x0000, 0x0000, 0x0000, 0x0000, 0x0000, 0x0000, 0x0000, 0x0000, 0x0000, 0x0000, 0x0000,
  0x0000, 0x0000, 0x0000, 0x0000, 0x0000, 0x0000, 0x0000, 0x0000, 0x0000, 0x0000, 0x0000, 0x0000, 0x0000, 0x0000, 0x0000, 0x0000, 0x0000, 0x0000, 0x0000, 0x0000, 0x0000, 0x0000, 0x0000, 0x0000, 0x0000, 0x0000, 0x0000, 0x0000, 0x0000, 0x0000, 0x0000, 0x0000, 0x0000, 0x0000, 0x0000, 0x0000, 0x0000, 0x0000, 0x0000, 0x0000, 0x0000, 0x0000, 0x0000, 0x0000, 0x0000, 0x0000, 0x0000, 0x0000, 0x0000, 0x0000, 0x0000, 0x0000, 0x0000, 0x0000, 0x0000, 0x0000, 0x0000, 0x0000, 0x0000, 0x0000, 0x0000, 0x0000, 0x0000, 0x0000, 0x0000, 0x0000, 0x0000, 0x0000, 0x0000, 0x0000, 0x0000, 0x0000, 0x0000, 0x0000, 0x0000, 0x0000, 0x0000, 0x0000, 0x0000, 0x0000,
  0x0000, 0x0000, 0x0000, 0x0000, 0x0000, 0x0000, 0x0000, 0x0000, 0x0000, 0x0000, 0x0000, 0x0000, 0x0000, 0x0000, 0x0000, 0x0000, 0x0000, 0x0000, 0x0000, 0x0000, 0x0000, 0x0000, 0x0000, 0x0000, 0x0000, 0x0000, 0x0000, 0x0000, 0x0000, 0x0000, 0x0000, 0x0000, 0x0000, 0x0000, 0x0000, 0x0000, 0x0000, 0x0000, 0x0000, 0x0000, 0x0000, 0x0000, 0x0000, 0x0000, 0x0000, 0x0000, 0x0000, 0x0000, 0x0000, 0x0000, 0x0000, 0x0000, 0x0000, 0x0000, 0x0000, 0x0000, 0x0000, 0x0000, 0x0000, 0x0000, 0x0000, 0x0000, 0x0000, 0x0000, 0x0000, 0x0000, 0x0000, 0x0000, 0x0000, 0x0000, 0x0000, 0x0000, 0x0000, 0x0000, 0x0000, 0x0000, 0x0000, 0x0000, 0x0000, 0x0000,
  0x0000, 0x0000, 0x0000, 0x0000, 0x0000, 0x0000, 0x0000, 0x0000, 0x0000, 0x0000, 0x0000, 0x0000, 0x0000, 0x0000, 0x0000, 0x0000, 0x0000, 0x0000, 0x0000, 0x0000, 0x0000, 0x0000, 0x0000, 0x0000, 0x0000, 0x0000, 0x0000, 0x0000, 0x0000, 0x0000, 0x0000, 0x0000, 0x0000, 0x0000, 0x0000, 0x0000, 0x0000, 0x0000, 0x0000, 0x0000, 0x0000, 0x0000, 0x0000, 0x0000, 0x0000, 0x0000, 0x0000, 0x0000, 0x0000, 0x0000, 0x0000, 0x0000, 0x0000, 0x0000, 0x0000, 0x0000, 0x0000, 0x0000, 0x0000, 0x0000, 0x0000, 0x0000, 0x0000, 0x0000, 0x0000, 0x0000, 0x0000, 0x0000, 0x0000, 0x0000, 0x0000, 0x0000, 0x0000, 0x0000, 0x0000, 0x0000, 0x0000, 0x0000, 0x0000, 0x0000,
  0x0000, 0x0000, 0x0000, 0x0000, 0x0000, 0x0000, 0x0000, 0x0000, 0x0000, 0x0000, 0x0000, 0x0000, 0x0000, 0x0000, 0x0000, 0x0000, 0x0000, 0x0000, 0x0000, 0x0000, 0x0000, 0x0000, 0x0000, 0x0000, 0x0000, 0x0000, 0x0000, 0x0000, 0x0000, 0x0000, 0x0000, 0x0000, 0x0000, 0x0000, 0x0000, 0x0000, 0x0000, 0x0000, 0x0000, 0x0000, 0x0000, 0x0000, 0x0000, 0x0000, 0x0000, 0x0000, 0x0000, 0x0000, 0x0000, 0x0000, 0x0000, 0x0000, 0x0000, 0x0000, 0x0000, 0x0000, 0x0000, 0x0000, 0x0000, 0x0000, 0x0000, 0x0000, 0x0000, 0x0000, 0x0000, 0x0000, 0x0000, 0x0000, 0x0000, 0x0000, 0x0000, 0x0000, 0x0000, 0x0000, 0x0000, 0x0000, 0x0000, 0x0000, 0x0000, 0x0000,
  0x0000, 0x0000, 0x0000, 0x0000, 0x0000, 0x0000, 0x0000, 0x0000, 0x0000, 0x0000, 0x0000, 0x0000, 0x0000, 0x0000, 0x0000, 0x0000, 0x0000, 0x0000, 0x0000, 0x0000, 0x0000, 0x0000, 0x0000, 0x0000, 0x0000, 0x0000, 0x0000, 0x0000, 0x0000, 0x0000, 0x0000, 0x0000, 0x0000, 0x0000, 0x0000, 0x0000, 0x0000, 0x0000, 0x0000, 0x0000, 0x0000, 0x0000, 0x0000, 0x0000, 0x0000, 0x0000, 0x0000, 0x0000, 0x0000, 0x0000, 0x0000, 0x0000, 0x0000, 0x0000, 0x0000, 0x0000, 0x0000, 0x0000, 0x0000, 0x0000, 0x0000, 0x0000, 0x0000, 0x0000, 0x0000, 0x0000, 0x0000, 0x0000, 0x0000, 0x0000, 0x0000, 0x0000, 0x0000, 0x0000, 0x0000, 0x0000, 0x0000, 0x0000, 0x0000, 0x0000,
  0x0000, 0x0000, 0x0000, 0x0000, 0x0000, 0x0000, 0x0000, 0x0000, 0x0000, 0x0000, 0x0000, 0x0000, 0x0000, 0x0000, 0x0000, 0x0000, 0x0000, 0x0000, 0x0000, 0x0000, 0x0000, 0x0000, 0x0000, 0x0000, 0x0000, 0x0000, 0x0000, 0x0000, 0x619c, 0x619c, 0x619c, 0x619c, 0x0000, 0x619c, 0x619c, 0x619c, 0x619c, 0x0000, 0x619c, 0x619c, 0x619c, 0x619c, 0x619c, 0x619c, 0x619c, 0x629c, 0x0000, 0x0000, 0x619c, 0x619c, 0x619c, 0x619c, 0x0000, 0x0000, 0x629c, 0x619c, 0x619c, 0x619c, 0x0000, 0x0000, 0x0000, 0x0000, 0x0000, 0x0000, 0x0000, 0x0000, 0x0000, 0x0000, 0x0000, 0x0000, 0x0000, 0x0000, 0x0000, 0x0000, 0x0000, 0x0000, 0x0000, 0x0000, 0x0000, 0x0000,
  0x0000, 0x0000, 0x0000, 0x0000, 0x0000, 0x0000, 0x0000, 0x0000, 0x0000, 0x0000, 0x0000, 0x0000, 0x0000, 0x0000, 0x0000, 0x0000, 0x0000, 0x0000, 0x0000, 0x0000, 0x0000, 0x0000, 0x0000, 0x0000, 0x0000, 0x0000, 0x0000, 0x00ce, 0xc0cd, 0x60bd, 0x81a4, 0x419c, 0x00ce, 0xc0cd, 0x60bd, 0x81a4, 0x419c, 0x00ce, 0xc0cd, 0x80bd, 0x80bd, 0x80bd, 0x80bd, 0x20b5, 0x619c, 0x619c, 0x619c, 0x00ce, 0xc0cd, 0x60bd, 0x81a4, 0x419c, 0x0000, 0xe0cd, 0xe0cd, 0x80c5, 0xc1a4, 0x419c, 0x0000, 0x0000, 0x0000, 0x0000, 0x0000, 0x0000, 0x0000, 0x0000, 0x0000, 0x0000, 0x0000, 0x0000, 0x0000, 0x0000, 0x0000, 0x0000, 0x0000, 0x0000, 0x0000, 0x0000, 0x0000, 0x0000,
  0x0000, 0x0000, 0x0000, 0x0000, 0x0000, 0x0000, 0x0000, 0x0000, 0x0000, 0x0000, 0x0000, 0x0000, 0x0000, 0x0000, 0x0000, 0x0000, 0x0000, 0x0000, 0x0000, 0x0000, 0x0000, 0x0000, 0x0000, 0x0000, 0x0000, 0x0000, 0x0000, 0xe0cd, 0x00ce, 0xc0cd, 0x81a4, 0x419c, 0xe0cd, 0x00ce, 0xc0cd, 0x81a4, 0x60bd, 0x00ce, 0xa0c5, 0xc1ac, 0x80bd, 0xe0cd, 0x00ce, 0xe0cd, 0x80bd, 0x81a4, 0x419c, 0xe0cd, 0x00ce, 0xc0cd, 0x81a4, 0x419c, 0x0000, 0x00ce, 0x00ce, 0x00ce, 0xe1ac, 0x419c, 0x0000, 0x0000, 0x0000, 0x0000, 0x0000, 0x0000, 0x0000, 0x0000, 0x0000, 0x0000, 0x0000, 0x0000, 0x0000, 0x0000, 0x0000, 0x0000, 0x0000, 0x0000, 0x0000, 0x0000, 0x0000, 0x0000,
  0x0000, 0x0000, 0x0000, 0x0000, 0x0000, 0x0000, 0x0000, 0x0000, 0x0000, 0x0000, 0x0000, 0x0000, 0x0000, 0x0000, 0x0000, 0x0000, 0x0000, 0x0000, 0x0000, 0x0000, 0x0000, 0x0000, 0x0000, 0x0000, 0x0000, 0x0000, 0x0000, 0xe0cd, 0x00ce, 0xc0cd, 0x81a4, 0x619c, 0x40b5, 0x00ce, 0x00ce, 0x01b5, 0xe0cd, 0x00ce, 0x80bd, 0x619c, 0x419c, 0x0000, 0xe0cd, 0x00ce, 0xc0cd, 0x81a4, 0x419c, 0xe0cd, 0x00ce, 0xc0cd, 0x81a4, 0x419c, 0x0000, 0x00ce, 0x00ce, 0x00ce, 0xe1ac, 0x419c, 0x0000, 0x0000, 0x0000, 0x0000, 0x0000, 0x0000, 0x0000, 0x0000, 0x0000, 0x0000, 0x0000, 0x0000, 0x0000, 0x0000, 0x0000, 0x0000, 0x0000, 0x0000, 0x0000, 0x0000, 0x0000, 0x0000,
  0x0000, 0x0000, 0x0000, 0x0000, 0x0000, 0x0000, 0x0000, 0x0000, 0x0000, 0x0000, 0x0000, 0x0000, 0x0000, 0x0000, 0x0000, 0x0000, 0x0000, 0x0000, 0x0000, 0x0000, 0x0000, 0x0000, 0x0000, 0x0000, 0x0000, 0x0000, 0x0000, 0x20c6, 0xe0cd, 0xe0cd, 0xc0cd, 0xc0cd, 0xe0cd, 0x00ce, 0x40d6, 0x40ad, 0x00ce, 0x00ce, 0x80bd, 0x619c, 0x419c, 0x0000, 0xe0cd, 0x00ce, 0xc0cd, 0x81a4, 0x419c, 0xe0cd, 0x00ce, 0xc0cd, 0x81a4, 0x419c, 0x0000, 0x00ce, 0x00ce, 0x00ce, 0xe1ac, 0x419c, 0x0000, 0x0000, 0x0000, 0x0000, 0x0000, 0x0000, 0x0000, 0x0000, 0x0000, 0x0000, 0x0000, 0x0000, 0x0000, 0x0000, 0x0000, 0x0000, 0x0000, 0x0000, 0x0000, 0x0000, 0x0000, 0x0000,
  0x0000, 0x0000, 0x0000, 0x0000, 0x0000, 0x0000, 0x0000, 0x0000, 0x0000, 0x0000, 0x0000, 0x0000, 0x0000, 0x0000, 0x0000, 0x0000, 0x0000, 0x0000, 0x0000, 0x0000, 0x0000, 0x0000, 0x0000, 0x0000, 0x0000, 0x0000, 0x0000, 0x0000, 0x40ad, 0x01ce, 0x00ce, 0x00ce, 0x20b5, 0x619c, 0x0000, 0x0000, 0x00ce, 0x00ce, 0x80bd, 0x619c, 0x419c, 0x0000, 0xe0cd, 0x00ce, 0xc0cd, 0x81a4, 0x419c, 0xe0cd, 0x00ce, 0xc0cd, 0x81a4, 0x419c, 0x0000, 0x00ce, 0x00ce, 0x00ce, 0xe1ac, 0x419c, 0x0000, 0x0000, 0x0000, 0x0000, 0x0000, 0x0000, 0x0000, 0x0000, 0x0000, 0x0000, 0x0000, 0x0000, 0x0000, 0x0000, 0x0000, 0x0000, 0x0000, 0x0000, 0x0000, 0x0000, 0x0000, 0x0000,
  0x0000, 0x0000, 0x0000, 0x0000, 0x0000, 0x0000, 0x0000, 0x0000, 0x0000, 0x0000, 0x0000, 0x0000, 0x0000, 0x0000, 0x0000, 0x0000, 0x0000, 0x0000, 0x0000, 0x0000, 0x0000, 0x0000, 0x0000, 0x0000, 0x0000, 0x0000, 0x0000, 0x0000, 0x0000, 0xc1cd, 0x00ce, 0x00ce, 0x20b5, 0x619c, 0x0000, 0x0000, 0x00ce, 0x00ce, 0x80c5, 0x619c, 0x619c, 0x619c, 0x20b5, 0x00ce, 0x00ce, 0x00ce, 0x0000, 0x00ce, 0x00ce, 0xc0cd, 0xa1a4, 0x619c, 0x619c, 0xe1ac, 0x00ce, 0x00ce, 0x00ce, 0x0000, 0x0000, 0x0000, 0x0000, 0x0000, 0x0000, 0x0000, 0x0000, 0x0000, 0x0000, 0x0000, 0x0000, 0x0000, 0x0000, 0x0000, 0x0000, 0x0000, 0x0000, 0x0000, 0x0000, 0x0000, 0x0000, 0x0000,
  0x0000, 0x0000, 0x0000, 0x0000, 0x0000, 0x0000, 0x0000, 0x0000, 0x0000, 0x0000, 0x0000, 0x0000, 0x0000, 0x0000, 0x0000, 0x0000, 0x0000, 0x0000, 0x0000, 0x0000, 0x0000, 0x0000, 0x0000, 0x0000, 0x0000, 0x0000, 0x0000, 0x0000, 0x0000, 0x40d6, 0x00ce, 0x00ce, 0xe0cd, 0x0000, 0x0000, 0x0000, 0x0000, 0xe0cd, 0x00ce, 0x00ce, 0x00ce, 0x00ce, 0x00ce, 0x00ce, 0x0000, 0x0000, 0x0000, 0x0000, 0x00ce, 0x00ce, 0x00ce, 0x00ce, 0x00ce, 0x00ce, 0x00ce, 0x40d6, 0x0000, 0x0000, 0x0000, 0x0000, 0x0000, 0x0000, 0x0000, 0x0000, 0x0000, 0x0000, 0x0000, 0x0000, 0x0000, 0x0000, 0x0000, 0x0000, 0x0000, 0x0000, 0x0000, 0x0000, 0x0000, 0x0000, 0x0000, 0x0000,
  0x0000, 0x0000, 0x0000, 0x0000, 0x0000, 0x0000, 0x0000, 0x0000, 0x0000, 0x0000, 0x0000, 0x0000, 0x0000, 0x0000, 0x0000, 0x0000, 0x0000, 0x0000, 0x0000, 0x0000, 0x0000, 0x0000, 0x0000, 0x0000, 0x0000, 0x0000, 0x819c, 0x619c, 0x819c, 0x0000, 0x0000, 0x0000, 0x0000, 0x0000, 0x0000, 0x0000, 0x819c, 0x619c, 0x819c, 0x0000, 0x0000, 0x819c, 0x619c, 0x619c, 0x619c, 0x619c, 0x409c, 0x0000, 0x409c, 0x619c, 0x619c, 0x409c, 0x0000, 0x0000, 0x0000, 0x0000, 0x0000, 0x819c, 0x619c, 0x60a4, 0x00bc, 0x0000, 0x0000, 0x0000, 0x0000, 0x0000, 0x0000, 0x0000, 0x0000, 0x0000, 0x0000, 0x0000, 0x0000, 0x0000, 0x0000, 0x0000, 0x0000, 0x0000, 0x0000, 0x0000,
  0x0000, 0x0000, 0x0000, 0x0000, 0x0000, 0x0000, 0x0000, 0x0000, 0x0000, 0x0000, 0x0000, 0x0000, 0x0000, 0x0000, 0x0000, 0x0000, 0x0000, 0x0000, 0x0000, 0x0000, 0x0000, 0x0000, 0x0000, 0x0000, 0xa0d6, 0xe0cd, 0xe1ac, 0x81a4, 0x619c, 0x0000, 0x0000, 0x609c, 0x619c, 0x609c, 0xa0d6, 0xe0cd, 0xe1ac, 0x81a4, 0x619c, 0xa0d6, 0xe0cd, 0xe1ac, 0xc1ac, 0xc1ac, 0xc1ac, 0x619c, 0x419c, 0xc1cd, 0x20b5, 0xc1a4, 0x619c, 0x619c, 0x819c, 0x0000, 0x0000, 0x0000, 0xe0cd, 0x01ad, 0xa1a4, 0x619c, 0x419c, 0x0000, 0x0000, 0x0000, 0x0000, 0x0000, 0x0000, 0x0000, 0x0000, 0x0000, 0x0000, 0x0000, 0x0000, 0x0000, 0x0000, 0x0000, 0x0000, 0x0000, 0x0000, 0x0000,
  0x0000, 0x0000, 0x0000, 0x0000, 0x0000, 0x0000, 0x0000, 0x0000, 0x0000, 0x0000, 0x0000, 0x0000, 0x0000, 0x0000, 0x0000, 0x0000, 0x0000, 0x0000, 0x0000, 0x0000, 0x0000, 0x0000, 0x0000, 0x0000, 0xc1cd, 0x00ce, 0x00ce, 0x20b5, 0x619c, 0xe0bd, 0x00ce, 0x01b5, 0xa1a4, 0x619c, 0xc1cd, 0x00ce, 0x00ce, 0x20b5, 0x619c, 0x20d6, 0x00ce, 0x00ce, 0x00ce, 0xc0cd, 0x80c5, 0x81bd, 0x0000, 0xe0cd, 0x00ce, 0xe0cd, 0x01ad, 0x81a4, 0x619c, 0x619c, 0x0000, 0x0000, 0x00ce, 0x00ce, 0x80bd, 0x619c, 0x419c, 0x0000, 0x0000, 0x0000, 0x0000, 0x0000, 0x0000, 0x0000, 0x0000, 0x0000, 0x0000, 0x0000, 0x0000, 0x0000, 0x0000, 0x0000, 0x0000, 0x0000, 0x0000, 0x0000,
  0x0000, 0x0000, 0x0000, 0x0000, 0x0000, 0x0000, 0x0000, 0x0000, 0x0000, 0x0000, 0x0000, 0x0000, 0x0000, 0x0000, 0x0000, 0x0000, 0x0000, 0x0000, 0x0000, 0x0000, 0x0000, 0x0000, 0x0000, 0x0000, 0xc1cd, 0x00ce, 0x00ce, 0x20b5, 0x619c, 0xc1cd, 0x00ce, 0x00ce, 0x20b5, 0x619c, 0xc1cd, 0x00ce, 0x00ce, 0x20b5, 0x619c, 0x0000, 0x0000, 0x00ce, 0x00ce, 0x80bd, 0x619c, 0x419c, 0x0000, 0xe0cd, 0x00ce, 0x00ce, 0x00ce, 0x40bd, 0xa1a4, 0x619c, 0x619c, 0x009c, 0x00ce, 0x00ce, 0x80bd, 0x619c, 0x419c, 0x0000, 0x0000, 0x0000, 0x0000, 0x0000, 0x0000, 0x0000, 0x0000, 0x0000, 0x0000, 0x0000, 0x0000, 0x0000, 0x0000, 0x0000, 0x0000, 0x0000, 0x0000, 0x0000,
  0x0000, 0x0000, 0x0000, 0x0000, 0x0000, 0x0000, 0x0000, 0x0000, 0x0000, 0x0000, 0x0000, 0x0000, 0x0000, 0x0000, 0x0000, 0x0000, 0x0000, 0x0000, 0x0000, 0x0000, 0x0000, 0x0000, 0x0000, 0x0000, 0xc1cd, 0x00ce, 0x00ce, 0x20b5, 0x619c, 0xc1cd, 0x00ce, 0x00ce, 0x20b5, 0x619c, 0xc1cd, 0x00ce, 0x00ce, 0x20b5, 0xa49b, 0x3690, 0x17a0, 0x00ce, 0x00ce, 0x80bd, 0x619c, 0x419c, 0x0000, 0xe0cd, 0x00ce, 0xe0cd, 0x60bd, 0xc0cd, 0x80c5, 0xe1ac, 0x619c, 0x619c, 0xc0c5, 0x00ce, 0x80bd, 0x619c, 0x419c, 0x0000, 0x0000, 0x4145, 0x4134, 0x4000, 0x0000, 0x0000, 0x0000, 0x0000, 0x0000, 0x0000, 0x0000, 0x0000, 0x0000, 0x0000, 0x0000, 0x0000, 0x0000, 0x0000,
  0x0000, 0x0000, 0x0000, 0x0000, 0x0000, 0x0000, 0x0000, 0x0000, 0x0000, 0x0000, 0x0000, 0x0000, 0x0000, 0x0000, 0x0000, 0x0000, 0x0000, 0x0000, 0x0000, 0x0000, 0x0000, 0x0000, 0x0000, 0x0000, 0xc1cd, 0x00ce, 0x00ce, 0x20b5, 0x619c, 0xa1a4, 0xe0cd, 0x00ce, 0x20b5, 0x619c, 0xa1a4, 0xe0cd, 0x00ce, 0x60bd, 0x279b, 0x3590, 0x1698, 0x00ce, 0x00ce, 0x80bd, 0x619c, 0x419c, 0x3690, 0x07bc, 0x00ce, 0xc0cd, 0x81a4, 0x40b5, 0x00ce, 0xc0c5, 0x20b5, 0x819c, 0x80bd, 0x00ce, 0x80bd, 0x619c, 0x419c, 0x0000, 0x0000, 0x614d, 0x613c, 0x4000, 0x0000, 0x0000, 0x0000, 0x0000, 0x0000, 0x0000, 0x0000, 0x0000, 0x0000, 0x0000, 0x0000, 0x0000, 0x0000, 0x0000,
  0x0000, 0x0000, 0x0000, 0x0000, 0x0000, 0x0000, 0x0000, 0x0000, 0x0000, 0x0000, 0x0000, 0x0000, 0x0000, 0x0000, 0x0000, 0x0000, 0x0000, 0x0000, 0x0000, 0x0000, 0x0000, 0x6145, 0x6145, 0x0000, 0xc0d5, 0x00ce, 0xe0cd, 0xa0c5, 0x40bd, 0x60bd, 0xe0cd, 0x00ce, 0xa0c5, 0x40bd, 0x60bd, 0xe0cd, 0x00ce, 0xe85b, 0x4e02, 0x0000, 0x0000, 0x00ce, 0x00ce, 0x80bd, 0x619c, 0x619c, 0xae99, 0x27bc, 0x00ce, 0xc0cd, 0x81a4, 0x419c, 0x00d6, 0x00ce, 0xe0cd, 0x60bd, 0xc0cd, 0x00ce, 0x80bd, 0x619c, 0x419c, 0x3690, 0x3690, 0x0000, 0x0000, 0x0000, 0x0000, 0x0000, 0x0000, 0x0000, 0x0000, 0x0000, 0x0000, 0x0000, 0x0000, 0x0000, 0x0000, 0x0000, 0x0000, 0x0000,
  0x0000, 0x0000, 0x0000, 0x0000, 0x0000, 0x0000, 0x0000, 0x0000, 0x0000, 0x0000, 0x0000, 0x0000, 0x0000, 0x0000, 0x0000, 0x0000, 0x0000, 0x0000, 0x0000, 0x7504, 0x9604, 0x0a2d, 0x6145, 0x0000, 0x00a8, 0x20b0, 0x80c3, 0x00ce, 0x00ce, 0x00ce, 0x00ce, 0xe0cd, 0x00ce, 0x00ce, 0x00ce, 0x00ce, 0xe1d5, 0x2e02, 0x4e02, 0xe0cd, 0x00ce, 0x00ce, 0x00ce, 0xc0cd, 0x60bd, 0xa1a4, 0x819c, 0xe0cd, 0x00ce, 0xe0cd, 0xc0ac, 0x819c, 0x0000, 0xe1d5, 0xe0cd, 0xe0cd, 0x00ce, 0x00ce, 0xc0c5, 0x619c, 0x009c, 0x5698, 0x3598, 0x9504, 0xf203, 0x4100, 0x0000, 0x0000, 0x0000, 0x0000, 0x0000, 0x0000, 0x0000, 0x0000, 0x0000, 0x0000, 0x0000, 0x0000, 0x0000, 0x0000,
  0x0000, 0x0000, 0x0000, 0x0000, 0x0000, 0x0000, 0x0000, 0x0000, 0x0000, 0x0000, 0x0000, 0x0000, 0x0000, 0x0000, 0x0000, 0x0000, 0x0000, 0x0000, 0x0000, 0x1304, 0x9604, 0xe490, 0x20b0, 0x0000, 0x0098, 0x20b0, 0x41b0, 0x00d6, 0x00ce, 0xa5a5, 0xb50c, 0x9504, 0x00d6, 0x00ce, 0x00ce, 0xe0bd, 0x20a8, 0x20b0, 0x0000, 0xe0bd, 0x00ce, 0x00ce, 0x00ce, 0x00ce, 0x00ce, 0xe0bd, 0x0000, 0x00d6, 0x00ce, 0x00ce, 0xe0bd, 0x0000, 0x4e02, 0x4e02, 0x0000, 0x0000, 0xe0cd, 0x00ce, 0xe0cd, 0x0000, 0x0000, 0x0000, 0x4e02, 0xb002, 0x5003, 0x2000, 0x0000, 0x0000, 0x0000, 0x0000, 0x0000, 0x0000, 0x0000, 0x0000, 0x0000, 0x0000, 0x0000, 0x0000, 0x0000, 0x0000,
  0x0000, 0x0000, 0x0000, 0x0000, 0x0000, 0x0000, 0x0000, 0x0000, 0x0000, 0x0000, 0x0000, 0x0000, 0x0000, 0x0000, 0x0000, 0x0000, 0x0000, 0x0000, 0x0000, 0x0000, 0x0000, 0x20b0, 0x41b0, 0x0000, 0x1698, 0x3690, 0x3690, 0x0000, 0x0000, 0x1504, 0x9504, 0x433d, 0x6145, 0x0000, 0x0000, 0x0000, 0x20b0, 0x41b0, 0x0000, 0x0000, 0x0000, 0x0000, 0x0000, 0x6145, 0x6145, 0x2145, 0x0000, 0x3590, 0x3590, 0x00b0, 0x20b0, 0x20b0, 0x6e02, 0x4e02, 0x1698, 0x3690, 0x3690, 0x0000, 0x20b0, 0x20b0, 0x00b0, 0x0000, 0x6e02, 0x4e02, 0x0000, 0x0000, 0x0000, 0x0000, 0x0000, 0x0000, 0x0000, 0x0000, 0x0000, 0x0000, 0x0000, 0x0000, 0x0000, 0x0000, 0x0000, 0x0000,
  0x0000, 0x0000, 0x0000, 0x0000, 0x0000, 0x0000, 0x0000, 0x0000, 0x0000, 0x0000, 0x0000, 0x0000, 0x0000, 0x0000, 0x0000, 0x0000, 0x0000, 0x0000, 0x0000, 0x6145, 0x6145, 0x414d, 0x0000, 0x4f02, 0x4e0a, 0xf360, 0x1698, 0x0000, 0x41a8, 0x20b0, 0x61a8, 0x4145, 0x414d, 0x414d, 0x6145, 0x6145, 0x4e02, 0x4e02, 0x0000, 0x550c, 0x9604, 0x950c, 0x0000, 0x824d, 0x614d, 0xe045, 0x0000, 0x7698, 0x5698, 0x00b8, 0x20b0, 0x00b0, 0x0000, 0x4f02, 0x4e0a, 0xf360, 0x1698, 0x9604, 0x3414, 0x20b0, 0x00b8, 0x6145, 0x6145, 0x0000, 0x0000, 0x0000, 0x0000, 0x0000, 0x0000, 0x0000, 0x0000, 0x0000, 0x0000, 0x0000, 0x0000, 0x0000, 0x0000, 0x0000, 0x0000, 0x0000,
  0x0000, 0x0000, 0x0000, 0x0000, 0x0000, 0x0000, 0x0000, 0x0000, 0x0000, 0x0000, 0x0000, 0x0000, 0x0000, 0x0000, 0x0000, 0x0000, 0x0000, 0x0000, 0x0000, 0x4055, 0x8145, 0xe044, 0x0000, 0x1002, 0x6f02, 0xaa02, 0x9604, 0x9504, 0x0098, 0x41b0, 0x00a8, 0x0000, 0x0000, 0xe044, 0x8145, 0x4055, 0x2e02, 0x7580, 0x3690, 0x5505, 0x960c, 0x1304, 0x0000, 0x20b0, 0x20b0, 0x41b0, 0x0000, 0x9504, 0x9604, 0x0000, 0x0000, 0x0000, 0x0000, 0x1002, 0x6f02, 0xaa02, 0x0000, 0x5604, 0x7504, 0x0000, 0x0000, 0x4145, 0x824d, 0x0000, 0x0000, 0x0000, 0x0000, 0x0000, 0x0000, 0x0000, 0x0000, 0x0000, 0x0000, 0x0000, 0x0000, 0x0000, 0x0000, 0x0000, 0x0000, 0x0000,
  0x0000, 0x0000, 0x0000, 0x0000, 0x0000, 0x0000, 0x0000, 0x0000, 0x0000, 0x0000, 0x0000, 0x0000, 0x0000, 0x0000, 0x0000, 0x0000, 0x0000, 0x0000, 0x0000, 0x0000, 0x0000, 0x0000, 0x0000, 0x0000, 0x0000, 0x0000, 0x2000, 0x0000, 0x0000, 0x0000, 0x0000, 0x0000, 0x0000, 0x0000, 0x0000, 0x0000, 0x0000, 0x0000, 0x0000, 0x0000, 0x0000, 0x0000, 0x0000, 0x0000, 0x0000, 0x0000, 0x0000, 0x0000, 0x2000, 0x0000, 0x0000, 0x0000, 0x0000, 0x0000, 0x0000, 0x0000, 0x0000, 0x0000, 0x0000, 0x0000, 0x0000, 0x0000, 0x0000, 0x0000, 0x0000, 0x0000, 0x0000, 0x0000, 0x0000, 0x0000, 0x0000, 0x0000, 0x0000, 0x0000, 0x0000, 0x0000, 0x0000, 0x0000, 0x0000, 0x0000,
  0x0000, 0x0000, 0x0000, 0x0000, 0x0000, 0x0000, 0x0000, 0x0000, 0x0000, 0x0000, 0x0000, 0x0000, 0x0000, 0x0000, 0x0000, 0x0000, 0x0000, 0x0000, 0x0000, 0x0000, 0x0000, 0x0000, 0x0000, 0x0000, 0x0000, 0x0000, 0x0000, 0x0000, 0x0000, 0x0000, 0x0000, 0x0000, 0x0000, 0x0000, 0x0000, 0x0000, 0x0000, 0x0000, 0x0000, 0x0000, 0x0000, 0x0000, 0x0000, 0x0000, 0x0000, 0x0000, 0x0000, 0x0000, 0x0000, 0x0000, 0x0000, 0x0000, 0x0000, 0x0000, 0x0000, 0x0000, 0x0000, 0x0000, 0x0000, 0x0000, 0x0000, 0x0000, 0x0000, 0x0000, 0x0000, 0x0000, 0x0000, 0x0000, 0x0000, 0x0000, 0x0000, 0x0000, 0x0000, 0x0000, 0x0000, 0x0000, 0x0000, 0x0000, 0x0000, 0x0000,
  0x0000, 0x0000, 0x0000, 0x0000, 0x0000, 0x0000, 0x0000, 0x0000, 0x0000, 0x0000, 0x0000, 0x0000, 0x0000, 0x0000, 0x0000, 0x0000, 0x0000, 0x0000, 0x0000, 0x0000, 0x0000, 0x0000, 0x0000, 0x0000, 0x0000, 0x0000, 0x0000, 0x0000, 0x0000, 0x0000, 0x0000, 0x0000, 0x0000, 0x0000, 0x0000, 0x0000, 0x0000, 0x0000, 0x0000, 0x0000, 0x0000, 0x0000, 0x0000, 0x0000, 0x0000, 0x0000, 0x0000, 0x0000, 0x0000, 0x0000, 0x0000, 0x0000, 0x0000, 0x0000, 0x0000, 0x0000, 0x0000, 0x0000, 0x0000, 0x0000, 0x0000, 0x0000, 0x0000, 0x0000, 0x0000, 0x0000, 0x0000, 0x0000, 0x0000, 0x0000, 0x0000, 0x0000, 0x0000, 0x0000, 0x0000, 0x0000, 0x0000, 0x0000, 0x0000, 0x0000,
  0x0000, 0x0000, 0x0000, 0x0000, 0x0000, 0x0000, 0x0000, 0x0000, 0x0000, 0x0000, 0x0000, 0x0000, 0x0000, 0x0000, 0x0000, 0x0000, 0x0000, 0x0000, 0x0000, 0x0000, 0x0000, 0x0000, 0x0000, 0x0000, 0x0000, 0x0000, 0x0000, 0x0000, 0x0000, 0x0000, 0x0000, 0x0000, 0x0000, 0x0000, 0x0000, 0x0000, 0x0000, 0x0000, 0x0000, 0x0000, 0x0000, 0x0000, 0x0000, 0x0000, 0x0000, 0x0000, 0x0000, 0x0000, 0x0000, 0x0000, 0x0000, 0x0000, 0x0000, 0x0000, 0x0000, 0x0000, 0x0000, 0x0000, 0x0000, 0x0000, 0x0000, 0x0000, 0x0000, 0x0000, 0x0000, 0x0000, 0x0000, 0x0000, 0x0000, 0x0000, 0x0000, 0x0000, 0x0000, 0x0000, 0x0000, 0x0000, 0x0000, 0x0000, 0x0000, 0x0000,
  0x0000, 0x0000, 0x0000, 0x0000, 0x0000, 0x0000, 0x0000, 0x0000, 0x0000, 0x0000, 0x0000, 0x0000, 0x0000, 0x0000, 0x0000, 0x0000, 0x0000, 0x0000, 0x0000, 0x0000, 0x0000, 0x0000, 0x0000, 0x0000, 0x0000, 0x0000, 0x0000, 0x0000, 0x0000, 0x0000, 0x0000, 0x0000, 0x0000, 0x0000, 0x0000, 0x0000, 0x0000, 0x0000, 0x0000, 0x0000, 0x0000, 0x0000, 0x0000, 0x0000, 0x0000, 0x0000, 0x0000, 0x0000, 0x0000, 0x0000, 0x0000, 0x0000, 0x0000, 0x0000, 0x0000, 0x0000, 0x0000, 0x0000, 0x0000, 0x0000, 0x0000, 0x0000, 0x0000, 0x0000, 0x0000, 0x0000, 0x0000, 0x0000, 0x0000, 0x0000, 0x0000, 0x0000, 0x0000, 0x0000, 0x0000, 0x0000, 0x0000, 0x0000, 0x0000, 0x0000,
  0x0000, 0x0000, 0x0000, 0x0000, 0x0000, 0x0000, 0x0000, 0x0000, 0x0000, 0x0000, 0x0000, 0x0000, 0x0000, 0x0000, 0x0000, 0x0000, 0x0000, 0x0000, 0x0000, 0x0000, 0x0000, 0x0000, 0x0000, 0x0000, 0x0000, 0x0000, 0x0000, 0x0000, 0x0000, 0x0000, 0x0000, 0x0000, 0x0000, 0x0000, 0x0000, 0x0000, 0x0000, 0x0000, 0x0000, 0x0000, 0x0000, 0x0000, 0x0000, 0x0000, 0x0000, 0x0000, 0x0000, 0x0000, 0x0000, 0x0000, 0x0000, 0x0000, 0x0000, 0x0000, 0x0000, 0x0000, 0x0000, 0x0000, 0x0000, 0x0000, 0x0000, 0x0000, 0x0000, 0x0000, 0x0000, 0x0000, 0x0000, 0x0000, 0x0000, 0x0000, 0x0000, 0x0000, 0x0000, 0x0000, 0x0000, 0x0000, 0x0000, 0x0000, 0x0000, 0x0000,
  0x0000, 0x0000, 0x0000, 0x0000, 0x0000, 0x0000, 0x0000, 0x0000, 0x0000, 0x0000, 0x0000, 0x0000, 0x0000, 0x0000, 0x0000, 0x0000, 0x0000, 0x0000, 0x0000, 0x0000, 0x0000, 0x0000, 0x0000, 0x0000, 0x0000, 0x0000, 0x0000, 0x0000, 0x0000, 0x0000, 0x0000, 0x0000, 0x0000, 0x0000, 0x0000, 0x0000, 0x0000, 0x0000, 0x0000, 0x0000, 0x0000, 0x0000, 0x0000, 0x0000, 0x0000, 0x0000, 0x0000, 0x0000, 0x0000, 0x0000, 0x0000, 0x0000, 0x0000, 0x0000, 0x0000, 0x0000, 0x0000, 0x0000, 0x0000, 0x0000, 0x0000, 0x0000, 0x0000, 0x0000, 0x0000, 0x0000, 0x0000, 0x0000, 0x0000, 0x0000, 0x0000, 0x0000, 0x0000, 0x0000, 0x0000, 0x0000, 0x0000, 0x0000, 0x0000, 0x0000,
  0x0000, 0x0000, 0x0000, 0x0000, 0x0000, 0x0000, 0x0000, 0x0000, 0x0000, 0x0000, 0x0000, 0x0000, 0x0000, 0x0000, 0x0000, 0x0000, 0x0000, 0x0000, 0x0000, 0x0000, 0x0000, 0x0000, 0x0000, 0x0000, 0x0000, 0x0000, 0x0000, 0x0000, 0x0000, 0x0000, 0x0000, 0x0000, 0x0000, 0x0000, 0x0000, 0x0000, 0x0000, 0x0000, 0x0000, 0x0000, 0x0000, 0x0000, 0x0000, 0x0000, 0x0000, 0x0000, 0x0000, 0x0000, 0x0000, 0x0000, 0x0000, 0x0000, 0x0000, 0x0000, 0x0000, 0x0000, 0x0000, 0x0000, 0x0000, 0x0000, 0x0000, 0x0000, 0x0000, 0x0000, 0x0000, 0x0000, 0x0000, 0x0000, 0x0000, 0x0000, 0x0000, 0x0000, 0x0000, 0x0000, 0x0000, 0x0000, 0x0000, 0x0000, 0x0000, 0x0000,
  0x0000, 0x0000, 0x0000, 0x0000, 0x0000, 0x0000, 0x0000, 0x0000, 0x0000, 0x0000, 0x0000, 0x0000, 0x0000, 0x0000, 0x0000, 0x0000, 0x0000, 0x0000, 0x0000, 0x0000, 0x0000, 0x0000, 0x0000, 0x0000, 0x0000, 0x0000, 0x0000, 0x0000, 0x0000, 0x0000, 0x0000, 0x0000, 0x0000, 0x0000, 0x0000, 0x0000, 0x0000, 0x0000, 0x0000, 0x0000, 0x0000, 0x0000, 0x0000, 0x0000, 0x0000, 0x0000, 0x0000, 0x0000, 0x0000, 0x0000, 0x0000, 0x0000, 0x0000, 0x0000, 0x0000, 0x0000, 0x0000, 0x0000, 0x0000, 0x0000, 0x0000, 0x0000, 0x0000, 0x0000, 0x0000, 0x0000, 0x0000, 0x0000, 0x0000, 0x0000, 0x0000, 0x0000, 0x0000, 0x0000, 0x0000, 0x0000, 0x0000, 0x0000, 0x0000, 0x0000,
  0x0000, 0x0000, 0x0000, 0x0000, 0x0000, 0x0000, 0x0000, 0x0000, 0x0000, 0x0000, 0x0000, 0x0000, 0x0000, 0x0000, 0x0000, 0x0000, 0x0000, 0x0000, 0x0000, 0x0000, 0x0000, 0x0000, 0x0000, 0x0000, 0x0000, 0x0000, 0x0000, 0x0000, 0x0000, 0x0000, 0x0000, 0x0000, 0x0000, 0x0000, 0x0000, 0x0000, 0x0000, 0x0000, 0x0000, 0x0000, 0x0000, 0x0000, 0x0000, 0x0000, 0x0000, 0x0000, 0x0000, 0x0000, 0x0000, 0x0000, 0x0000, 0x0000, 0x0000, 0x0000, 0x0000, 0x0000, 0x0000, 0x0000, 0x0000, 0x0000, 0x0000, 0x0000, 0x0000, 0x0000, 0x0000, 0x0000, 0x0000, 0x0000, 0x0000, 0x0000, 0x0000, 0x0000, 0x0000, 0x0000, 0x0000, 0x0000, 0x0000, 0x0000, 0x0000, 0x0000,
  0x0000, 0x0000, 0x0000, 0x0000, 0x0000, 0x0000, 0x0000, 0x0000, 0x0000, 0x0000, 0x0000, 0x0000, 0x0000, 0x0000, 0x0000, 0x0000, 0x0000, 0x0000, 0x0000, 0x0000, 0x0000, 0x0000, 0x0000, 0x0000, 0x0000, 0x0000, 0x0000, 0x0000, 0x0000, 0x0000, 0x0000, 0x0000, 0x0000, 0x0000, 0x0000, 0x0000, 0x0000, 0x0000, 0x0000, 0x0000, 0x0000, 0x0000, 0x0000, 0x0000, 0x0000, 0x0000, 0x0000, 0x0000, 0x0000, 0x0000, 0x0000, 0x0000, 0x0000, 0x0000, 0x0000, 0x0000, 0x0000, 0x0000, 0x0000, 0x0000, 0x0000, 0x0000, 0x0000, 0x0000, 0x0000, 0x0000, 0x0000, 0x0000, 0x0000, 0x0000, 0x0000, 0x0000, 0x0000, 0x0000, 0x0000, 0x0000, 0x0000, 0x0000, 0x0000, 0x0000,
  0x0000, 0x0000, 0x0000, 0x0000, 0x0000, 0x0000, 0x0000, 0x0000, 0x0000, 0x0000, 0x0000, 0x0000, 0x0000, 0x0000, 0x0000, 0x0000, 0x0000, 0x0000, 0x0000, 0x0000, 0x0000, 0x0000, 0x0000, 0x0000, 0x0000, 0x0000, 0x0000, 0x0000, 0x0000, 0x0000, 0x0000, 0x0000, 0x0000, 0x0000, 0x0000, 0x0000, 0x0000, 0x0000, 0x0000, 0x0000, 0x0000, 0x0000, 0x0000, 0x0000, 0x0000, 0x0000, 0x0000, 0x0000, 0x0000, 0x0000, 0x0000, 0x0000, 0x0000, 0x0000, 0x0000, 0x0000, 0x0000, 0x0000, 0x0000, 0x0000, 0x0000, 0x0000, 0x0000, 0x0000, 0x0000, 0x0000, 0x0000, 0x0000, 0x0000, 0x0000, 0x0000, 0x0000, 0x0000, 0x0000, 0x0000, 0x0000, 0x0000, 0x0000, 0x0000, 0x0000,
  0x0000, 0x0000, 0x0000, 0x0000, 0x0000, 0x0000, 0x0000, 0x0000, 0x0000, 0x0000, 0x0000, 0x0000, 0x0000, 0x0000, 0x0000, 0x0000, 0x0000, 0x0000, 0x0000, 0x0000, 0x0000, 0x0000, 0x0000, 0x0000, 0x0000, 0x0000, 0x0000, 0x0000, 0x0000, 0x0000, 0x0000, 0x0000, 0x0000, 0x0000, 0x0000, 0x0000, 0x0000, 0x0000, 0x0000, 0x0000, 0x0000, 0x0000, 0x0000, 0x0000, 0x0000, 0x0000, 0x0000, 0x0000, 0x0000, 0x0000, 0x0000, 0x0000, 0x0000, 0x0000, 0x0000, 0x0000, 0x0000, 0x0000, 0x0000, 0x0000, 0x0000, 0x0000, 0x0000, 0x0000, 0x0000, 0x0000, 0x0000, 0x0000, 0x0000, 0x0000, 0x0000, 0x0000, 0x0000, 0x0000, 0x0000, 0x0000, 0x0000, 0x0000, 0x0000, 0x0000,
  0x0000, 0x0000, 0x0000, 0x0000, 0x0000, 0x0000, 0x0000, 0x0000, 0x0000, 0x0000, 0x0000, 0x0000, 0x0000, 0x0000, 0x0000, 0x0000, 0x0000, 0x0000, 0x0000, 0x0000, 0x0000, 0x0000, 0x0000, 0x0000, 0x0000, 0x0000, 0x0000, 0x0000, 0x0000, 0x0000, 0x0000, 0x0000, 0x0000, 0x0000, 0x0000, 0x0000, 0x0000, 0x0000, 0x0000, 0x0000, 0x0000, 0x0000, 0x0000, 0x0000, 0x0000, 0x0000, 0x0000, 0x0000, 0x0000, 0x0000, 0x0000, 0x0000, 0x0000, 0x0000, 0x0000, 0x0000, 0x0000, 0x0000, 0x0000, 0x0000, 0x0000, 0x0000, 0x0000, 0x0000, 0x0000, 0x0000, 0x0000, 0x0000, 0x0000, 0x0000, 0x0000, 0x0000, 0x0000, 0x0000, 0x0000, 0x0000, 0x0000, 0x0000, 0x0000, 0x0000,
  0x0000, 0x0000, 0x0000, 0x0000, 0x0000, 0x0000, 0x0000, 0x0000, 0x0000, 0x0000, 0x0000, 0x0000, 0x0000, 0x0000, 0x0000, 0x0000, 0x0000, 0x0000, 0x0000, 0x0000, 0x0000, 0x0000, 0x0000, 0x0000, 0x0000, 0x0000, 0x0000, 0x0000, 0x0000, 0x0000, 0x0000, 0x0000, 0x0000, 0x0000, 0x0000, 0x0000, 0x0000, 0x0000, 0x0000, 0x0000, 0x0000, 0x0000, 0x0000, 0x0000, 0x0000, 0x0000, 0x0000, 0x0000, 0x0000, 0x0000, 0x0000, 0x0000, 0x0000, 0x0000, 0x0000, 0x0000, 0x0000, 0x0000, 0x0000, 0x0000, 0x0000, 0x0000, 0x0000, 0x0000, 0x0000, 0x0000, 0x0000, 0x0000, 0x0000, 0x0000, 0x0000, 0x0000, 0x0000, 0x0000, 0x0000, 0x0000, 0x0000, 0x0000, 0x0000, 0x0000,
  0x0000, 0x0000, 0x0000, 0x0000, 0x0000, 0x0000, 0x0000, 0x0000, 0x0000, 0x0000, 0x0000, 0x0000, 0x0000, 0x0000, 0x0000, 0x0000, 0x0000, 0x0000, 0x0000, 0x0000, 0x0000, 0x0000, 0x0000, 0x0000, 0x0000, 0x0000, 0x0000, 0x0000, 0x0000, 0x0000, 0x0000, 0x0000, 0x0000, 0x0000, 0x0000, 0x0000, 0x0000, 0x0000, 0x0000, 0x0000, 0x0000, 0x0000, 0x0000, 0x0000, 0x0000, 0x0000, 0x0000, 0x0000, 0x0000, 0x0000, 0x0000, 0x0000, 0x0000, 0x0000, 0x0000, 0x0000, 0x0000, 0x0000, 0x0000, 0x0000, 0x0000, 0x0000, 0x0000, 0x0000, 0x0000, 0x0000, 0x0000, 0x0000, 0x0000, 0x0000, 0x0000, 0x0000, 0x0000, 0x0000, 0x0000, 0x0000, 0x0000, 0x0000, 0x0000, 0x0000
};
static const uint16_t ImagemVitoria2[][60*80/2]  = {
  0x0000, 0x0000, 0x0000, 0x0000, 0x0000, 0x0000, 0x0000, 0x0000, 0x0000, 0x0000, 0x0000, 0x0000, 0x0000, 0x0000, 0x0000, 0x0000, 0x0000, 0x0000, 0x0000, 0x0000, 0x0000, 0x0000, 0x0000, 0x0000, 0x0000, 0x0000, 0x0000, 0x0000, 0x0000, 0x0000, 0x0000, 0x0000, 0x0000, 0x0000, 0x0000, 0x0000, 0x0000, 0x0000, 0x0000, 0x0000, 0x0000, 0x0000, 0x0000, 0x0000, 0x0000, 0x0000, 0x0000, 0x0000, 0x0000, 0x0000, 0x0000, 0x0000, 0x0000, 0x0000, 0x0000, 0x0000, 0x0000, 0x0000, 0x0000, 0x0000, 0x0000, 0x0000, 0x0000, 0x0000, 0x0000, 0x0000, 0x0000, 0x0000, 0x0000, 0x0000, 0x0000, 0x0000, 0x0000, 0x0000, 0x0000, 0x0000, 0x0000, 0x0000, 0x0000, 0x0000,
  0x0000, 0x0000, 0x0000, 0x0000, 0x0000, 0x0000, 0x0000, 0x0000, 0x0000, 0x0000, 0x0000, 0x0000, 0x0000, 0x0000, 0x0000, 0x0000, 0x0000, 0x0000, 0x0000, 0x0000, 0x0000, 0x0000, 0x0000, 0x0000, 0x0000, 0x0000, 0x0000, 0x0000, 0x0000, 0x0000, 0x0000, 0x0000, 0x0000, 0x0000, 0x0000, 0x0000, 0x0000, 0x0000, 0x0000, 0x0000, 0x0000, 0x0000, 0x0000, 0x0000, 0x0000, 0x0000, 0x0000, 0x0000, 0x0000, 0x0000, 0x0000, 0x0000, 0x0000, 0x0000, 0x0000, 0x0000, 0x0000, 0x0000, 0x0000, 0x0000, 0x0000, 0x0000, 0x0000, 0x0000, 0x0000, 0x0000, 0x0000, 0x0000, 0x0000, 0x0000, 0x0000, 0x0000, 0x0000, 0x0000, 0x0000, 0x0000, 0x0000, 0x0000, 0x0000, 0x0000,
  0x0000, 0x0000, 0x0000, 0x0000, 0x0000, 0x0000, 0x0000, 0x0000, 0x0000, 0x0000, 0x0000, 0x0000, 0x0000, 0x0000, 0x0000, 0x0000, 0x0000, 0x0000, 0x0000, 0x0000, 0x0000, 0x0000, 0x0000, 0x0000, 0x0000, 0x0000, 0x0000, 0x0000, 0x0000, 0x0000, 0x0000, 0x0000, 0x0000, 0x0000, 0x0000, 0x0000, 0x0000, 0x0000, 0x0000, 0x0000, 0x0000, 0x0000, 0x0000, 0x0000, 0x0000, 0x0000, 0x0000, 0x0000, 0x0000, 0x0000, 0x0000, 0x0000, 0x0000, 0x0000, 0x0000, 0x0000, 0x0000, 0x0000, 0x0000, 0x0000, 0x0000, 0x0000, 0x0000, 0x0000, 0x0000, 0x0000, 0x0000, 0x0000, 0x0000, 0x0000, 0x0000, 0x0000, 0x0000, 0x0000, 0x0000, 0x0000, 0x0000, 0x0000, 0x0000, 0x0000,
  0x0000, 0x0000, 0x0000, 0x0000, 0x0000, 0x0000, 0x0000, 0x0000, 0x0000, 0x0000, 0x0000, 0x0000, 0x0000, 0x0000, 0x0000, 0x0000, 0x0000, 0x0000, 0x0000, 0x0000, 0x0000, 0x0000, 0x0000, 0x0000, 0x0000, 0x0000, 0x0000, 0x0000, 0x0000, 0x0000, 0x0000, 0x0000, 0x0000, 0x0000, 0x0000, 0x0000, 0x0000, 0x0000, 0x0000, 0x0000, 0x0000, 0x0000, 0x0000, 0x0000, 0x0000, 0x0000, 0x0000, 0x0000, 0x0000, 0x0000, 0x0000, 0x0000, 0x0000, 0x0000, 0x0000, 0x0000, 0x0000, 0x0000, 0x0000, 0x0000, 0x0000, 0x0000, 0x0000, 0x0000, 0x0000, 0x0000, 0x0000, 0x0000, 0x0000, 0x0000, 0x0000, 0x0000, 0x0000, 0x0000, 0x0000, 0x0000, 0x0000, 0x0000, 0x0000, 0x0000,
  0x0000, 0x0000, 0x0000, 0x0000, 0x0000, 0x0000, 0x0000, 0x0000, 0x0000, 0x0000, 0x0000, 0x0000, 0x0000, 0x0000, 0x0000, 0x0000, 0x0000, 0x0000, 0x0000, 0x0000, 0x0000, 0x0000, 0x0000, 0x0000, 0x0000, 0x0000, 0x0000, 0x0000, 0x0000, 0x0000, 0x0000, 0x0000, 0x0000, 0x0000, 0x0000, 0x0000, 0x0000, 0x0000, 0x0000, 0x0000, 0x0000, 0x0000, 0x0000, 0x0000, 0x0000, 0x0000, 0x0000, 0x0000, 0x0000, 0x0000, 0x0000, 0x0000, 0x0000, 0x0000, 0x0000, 0x0000, 0x0000, 0x0000, 0x0000, 0x0000, 0x0000, 0x0000, 0x0000, 0x0000, 0x0000, 0x0000, 0x0000, 0x0000, 0x0000, 0x0000, 0x0000, 0x0000, 0x0000, 0x0000, 0x0000, 0x0000, 0x0000, 0x0000, 0x0000, 0x0000,
  0x0000, 0x0000, 0x0000, 0x0000, 0x0000, 0x0000, 0x0000, 0x0000, 0x0000, 0x0000, 0x0000, 0x0000, 0x0000, 0x0000, 0x0000, 0x0000, 0x0000, 0x0000, 0x0000, 0x0000, 0x0000, 0x0000, 0x0000, 0x0000, 0x0000, 0x0000, 0x0000, 0x0000, 0x0000, 0x0000, 0x0000, 0x0000, 0x0000, 0x0000, 0x0000, 0x0000, 0x0000, 0x0000, 0x0000, 0x0000, 0x0000, 0x0000, 0x0000, 0x0000, 0x0000, 0x0000, 0x0000, 0x0000, 0x0000, 0x0000, 0x0000, 0x0000, 0x0000, 0x0000, 0x0000, 0x0000, 0x0000, 0x0000, 0x0000, 0x0000, 0x0000, 0x0000, 0x0000, 0x0000, 0x0000, 0x0000, 0x0000, 0x0000, 0x0000, 0x0000, 0x0000, 0x0000, 0x0000, 0x0000, 0x0000, 0x0000, 0x0000, 0x0000, 0x0000, 0x0000,
  0x0000, 0x0000, 0x0000, 0x0000, 0x0000, 0x0000, 0x0000, 0x0000, 0x0000, 0x0000, 0x0000, 0x0000, 0x0000, 0x0000, 0x0000, 0x0000, 0x0000, 0x0000, 0x0000, 0x0000, 0x0000, 0x0000, 0x0000, 0x0000, 0x0000, 0x0000, 0x0000, 0x0000, 0x0000, 0x0000, 0x0000, 0x0000, 0x0000, 0x0000, 0x0000, 0x0000, 0x0000, 0x0000, 0x0000, 0x0000, 0x0000, 0x0000, 0x0000, 0x0000, 0x0000, 0x0000, 0x0000, 0x0000, 0x0000, 0x0000, 0x0000, 0x0000, 0x0000, 0x0000, 0x0000, 0x0000, 0x0000, 0x0000, 0x0000, 0x0000, 0x0000, 0x0000, 0x0000, 0x0000, 0x0000, 0x0000, 0x0000, 0x0000, 0x0000, 0x0000, 0x0000, 0x0000, 0x0000, 0x0000, 0x0000, 0x0000, 0x0000, 0x0000, 0x0000, 0x0000,
  0x0000, 0x0000, 0x0000, 0x0000, 0x0000, 0x0000, 0x0000, 0x0000, 0x0000, 0x0000, 0x0000, 0x0000, 0x0000, 0x0000, 0x0000, 0x0000, 0x0000, 0x0000, 0x0000, 0x0000, 0x0000, 0x0000, 0x0000, 0x0000, 0x0000, 0x0000, 0x0000, 0x0000, 0x0000, 0x0000, 0x0000, 0x0000, 0x0000, 0x0000, 0x0000, 0x0000, 0x0000, 0x0000, 0x0000, 0x0000, 0x0000, 0x0000, 0x0000, 0x0000, 0x0000, 0x0000, 0x0000, 0x0000, 0x0000, 0x0000, 0x0000, 0x0000, 0x0000, 0x0000, 0x0000, 0x0000, 0x0000, 0x0000, 0x0000, 0x0000, 0x0000, 0x0000, 0x0000, 0x0000, 0x0000, 0x0000, 0x0000, 0x0000, 0x0000, 0x0000, 0x0000, 0x0000, 0x0000, 0x0000, 0x0000, 0x0000, 0x0000, 0x0000, 0x0000, 0x0000,
  0x0000, 0x0000, 0x0000, 0x0000, 0x0000, 0x0000, 0x0000, 0x0000, 0x0000, 0x0000, 0x0000, 0x0000, 0x0000, 0x0000, 0x0000, 0x0000, 0x0000, 0x0000, 0x0000, 0x0000, 0x0000, 0x0000, 0x0000, 0x0000, 0x0000, 0x0000, 0x0000, 0x0000, 0x0000, 0x0000, 0x0000, 0x0000, 0x0000, 0x0000, 0x0000, 0x0000, 0x0000, 0x0000, 0x0000, 0x0000, 0x0000, 0x0000, 0x0000, 0x0000, 0x0000, 0x0000, 0x0000, 0x0000, 0x0000, 0x0000, 0x0000, 0x0000, 0x0000, 0x0000, 0x0000, 0x0000, 0x0000, 0x0000, 0x0000, 0x0000, 0x0000, 0x0000, 0x0000, 0x0000, 0x0000, 0x0000, 0x0000, 0x0000, 0x0000, 0x0000, 0x0000, 0x0000, 0x0000, 0x0000, 0x0000, 0x0000, 0x0000, 0x0000, 0x0000, 0x0000,
  0x0000, 0x0000, 0x0000, 0x0000, 0x0000, 0x0000, 0x0000, 0x0000, 0x0000, 0x0000, 0x0000, 0x0000, 0x0000, 0x0000, 0x0000, 0x0000, 0x0000, 0x0000, 0x0000, 0x0000, 0x0000, 0x0000, 0x0000, 0x0000, 0x0000, 0x0000, 0x0000, 0x0000, 0x0000, 0x0000, 0x0000, 0x0000, 0x0000, 0x0000, 0x0000, 0x0000, 0x0000, 0x0000, 0x0000, 0x0000, 0x0000, 0x0000, 0x0000, 0x0000, 0x0000, 0x0000, 0x0000, 0x0000, 0x0000, 0x0000, 0x0000, 0x0000, 0x0000, 0x0000, 0x0000, 0x0000, 0x0000, 0x0000, 0x0000, 0x0000, 0x0000, 0x0000, 0x0000, 0x0000, 0x0000, 0x0000, 0x0000, 0x0000, 0x0000, 0x0000, 0x0000, 0x0000, 0x0000, 0x0000, 0x0000, 0x0000, 0x0000, 0x0000, 0x0000, 0x0000,
  0x0000, 0x0000, 0x0000, 0x0000, 0x0000, 0x0000, 0x0000, 0x0000, 0x0000, 0x0000, 0x0000, 0x0000, 0x0000, 0x0000, 0x0000, 0x0000, 0x0000, 0x0000, 0x0000, 0x0000, 0x0000, 0x0000, 0x0000, 0x0000, 0x0000, 0x0000, 0x0000, 0x0000, 0x0000, 0x0000, 0x0000, 0x0000, 0x0000, 0x0000, 0x0000, 0x0000, 0x0000, 0x0000, 0x0000, 0x0000, 0x0000, 0x0000, 0x0000, 0x0000, 0x0000, 0x0000, 0x0000, 0x0000, 0x0000, 0x0000, 0x0000, 0x0000, 0x0000, 0x0000, 0x0000, 0x0000, 0x0000, 0x0000, 0x0000, 0x0000, 0x0000, 0x0000, 0x0000, 0x0000, 0x0000, 0x0000, 0x0000, 0x0000, 0x0000, 0x0000, 0x0000, 0x0000, 0x0000, 0x0000, 0x0000, 0x0000, 0x0000, 0x0000, 0x0000, 0x0000,
  0x0000, 0x0000, 0x0000, 0x0000, 0x0000, 0x0000, 0x0000, 0x0000, 0x0000, 0x0000, 0x0000, 0x0000, 0x0000, 0x0000, 0x0000, 0x0000, 0x0000, 0x0000, 0x0000, 0x0000, 0x0000, 0x0000, 0x0000, 0x0000, 0x0000, 0x0000, 0x0000, 0x0000, 0x0000, 0x0000, 0x0000, 0x0000, 0x0000, 0x0000, 0x0000, 0x0000, 0x0000, 0x0000, 0x0000, 0x0000, 0x0000, 0x0000, 0x0000, 0x0000, 0x0000, 0x0000, 0x0000, 0x0000, 0x0000, 0x0000, 0x0000, 0x0000, 0x0000, 0x0000, 0x0000, 0x0000, 0x0000, 0x0000, 0x0000, 0x0000, 0x0000, 0x0000, 0x0000, 0x0000, 0x0000, 0x0000, 0x0000, 0x0000, 0x0000, 0x0000, 0x0000, 0x0000, 0x0000, 0x0000, 0x0000, 0x0000, 0x0000, 0x0000, 0x0000, 0x0000,
  0x0000, 0x0000, 0x0000, 0x0000, 0x0000, 0x0000, 0x0000, 0x0000, 0x0000, 0x0000, 0x0000, 0x0000, 0x0000, 0x0000, 0x0000, 0x0000, 0x0000, 0x0000, 0x0000, 0x0000, 0x0000, 0x0000, 0x0000, 0x0000, 0x0000, 0x0000, 0x0000, 0x0000, 0x0000, 0x0000, 0x0000, 0x0000, 0x0000, 0x0000, 0x0000, 0x0000, 0x0000, 0x0000, 0x0000, 0x0000, 0x0000, 0x0000, 0x0000, 0x0000, 0x0000, 0x0000, 0x0000, 0x0000, 0x0000, 0x0000, 0x0000, 0x0000, 0x0000, 0x0000, 0x0000, 0x0000, 0x0000, 0x0000, 0x0000, 0x0000, 0x0000, 0x0000, 0x0000, 0x0000, 0x0000, 0x0000, 0x0000, 0x0000, 0x0000, 0x0000, 0x0000, 0x0000, 0x0000, 0x0000, 0x0000, 0x0000, 0x0000, 0x0000, 0x0000, 0x0000,
  0x0000, 0x0000, 0x0000, 0x0000, 0x0000, 0x0000, 0x0000, 0x0000, 0x0000, 0x0000, 0x0000, 0x0000, 0x0000, 0x0000, 0x0000, 0x0000, 0x0000, 0x0000, 0x0000, 0x0000, 0x0000, 0x0000, 0x0000, 0x0000, 0x0000, 0x0000, 0x0000, 0x0000, 0x0000, 0x0000, 0x0000, 0x0000, 0x0000, 0x0000, 0x0000, 0x0000, 0x0000, 0x0000, 0x0000, 0x0000, 0x0000, 0x0000, 0x0000, 0x0000, 0x0000, 0x0000, 0x0000, 0x0000, 0x0000, 0x0000, 0x0000, 0x0000, 0x0000, 0x0000, 0x0000, 0x0000, 0x0000, 0x0000, 0x0000, 0x0000, 0x0000, 0x0000, 0x0000, 0x0000, 0x0000, 0x0000, 0x0000, 0x0000, 0x0000, 0x0000, 0x0000, 0x0000, 0x0000, 0x0000, 0x0000, 0x0000, 0x0000, 0x0000, 0x0000, 0x0000,
  0x0000, 0x0000, 0x0000, 0x0000, 0x0000, 0x0000, 0x0000, 0x0000, 0x0000, 0x0000, 0x0000, 0x0000, 0x0000, 0x0000, 0x0000, 0x0000, 0x0000, 0x0000, 0x0000, 0x0000, 0x0000, 0x0000, 0x0000, 0x0000, 0x0000, 0x0000, 0x0000, 0x0000, 0x0000, 0x0000, 0x0000, 0x0000, 0x0000, 0x0000, 0x0000, 0x0000, 0x0000, 0x0000, 0x0000, 0x0000, 0x0000, 0x0000, 0x0000, 0x0000, 0x0000, 0x0000, 0x0000, 0x0000, 0x0000, 0x0000, 0x0000, 0x0000, 0x0000, 0x0000, 0x0000, 0x0000, 0x0000, 0x0000, 0x0000, 0x0000, 0x0000, 0x0000, 0x0000, 0x0000, 0x0000, 0x0000, 0x0000, 0x0000, 0x0000, 0x0000, 0x0000, 0x0000, 0x0000, 0x0000, 0x0000, 0x0000, 0x0000, 0x0000, 0x0000, 0x0000,
  0x0000, 0x0000, 0x0000, 0x0000, 0x0000, 0x0000, 0x0000, 0x0000, 0x0000, 0x0000, 0x0000, 0x0000, 0x0000, 0x0000, 0x0000, 0x0000, 0x0000, 0x0000, 0x0000, 0x0000, 0x0000, 0x0000, 0x0000, 0x0000, 0x0000, 0x0000, 0x0000, 0x0000, 0x0000, 0x0000, 0x0000, 0x0000, 0x0000, 0x0000, 0x0000, 0x0000, 0x0000, 0x0000, 0x0000, 0x0000, 0x0000, 0x0000, 0x0000, 0x0000, 0x0000, 0x0000, 0x0000, 0x0000, 0x0000, 0x0000, 0x0000, 0x0000, 0x0000, 0x0000, 0x0000, 0x0000, 0x0000, 0x0000, 0x0000, 0x0000, 0x0000, 0x0000, 0x0000, 0x0000, 0x0000, 0x0000, 0x0000, 0x0000, 0x0000, 0x0000, 0x0000, 0x0000, 0x0000, 0x0000, 0x0000, 0x0000, 0x0000, 0x0000, 0x0000, 0x0000,
  0x0000, 0x0000, 0x0000, 0x0000, 0x0000, 0x0000, 0x0000, 0x0000, 0x0000, 0x0000, 0x0000, 0x0000, 0x0000, 0x0000, 0x0000, 0x0000, 0x0000, 0x0000, 0x0000, 0x0000, 0x0000, 0x0000, 0x0000, 0x0000, 0x0000, 0x0000, 0x0000, 0x0000, 0x0000, 0x0000, 0x0000, 0x0000, 0x0000, 0x0000, 0x0000, 0x0000, 0x0000, 0x0000, 0x0000, 0x0000, 0x0000, 0x0000, 0x0000, 0x0000, 0x0000, 0x0000, 0x0000, 0x0000, 0x0000, 0x0000, 0x0000, 0x0000, 0x0000, 0x0000, 0x0000, 0x0000, 0x0000, 0x0000, 0x0000, 0x0000, 0x0000, 0x0000, 0x0000, 0x0000, 0x0000, 0x0000, 0x0000, 0x0000, 0x0000, 0x0000, 0x0000, 0x0000, 0x0000, 0x0000, 0x0000, 0x0000, 0x0000, 0x0000, 0x0000, 0x0000,
  0x0000, 0x0000, 0x0000, 0x0000, 0x0000, 0x0000, 0x0000, 0x0000, 0x0000, 0x0000, 0x0000, 0x0000, 0x0000, 0x0000, 0x0000, 0x0000, 0x0000, 0x0000, 0x0000, 0x0000, 0x0000, 0x0000, 0x0000, 0x0000, 0x0000, 0x0000, 0x0000, 0x0000, 0x0000, 0x0000, 0x0000, 0x0000, 0x0000, 0x0000, 0x0000, 0x0000, 0x0000, 0x0000, 0x0000, 0x0000, 0x0000, 0x0000, 0x0000, 0x0000, 0x0000, 0x0000, 0x0000, 0x0000, 0x0000, 0x0000, 0x0000, 0x0000, 0x0000, 0x0000, 0x0000, 0x0000, 0x0000, 0x0000, 0x0000, 0x0000, 0x0000, 0x0000, 0x0000, 0x0000, 0x0000, 0x0000, 0x0000, 0x0000, 0x0000, 0x0000, 0x0000, 0x0000, 0x0000, 0x0000, 0x0000, 0x0000, 0x0000, 0x0000, 0x0000, 0x0000,
  0x0000, 0x0000, 0x0000, 0x0000, 0x0000, 0x0000, 0x0000, 0x0000, 0x0000, 0x0000, 0x0000, 0x0000, 0x0000, 0x0000, 0x0000, 0x0000, 0x0000, 0x0000, 0x0000, 0x0000, 0x0000, 0x0000, 0x0000, 0x0000, 0x0000, 0x0000, 0x0000, 0x0000, 0x0000, 0x0000, 0x0000, 0x0000, 0x0000, 0x0000, 0x0000, 0x0000, 0x0000, 0x0000, 0x0000, 0x0000, 0x0000, 0x0000, 0x0000, 0x0000, 0x0000, 0x0000, 0x0000, 0x0000, 0x0000, 0x0000, 0x0000, 0x0000, 0x0000, 0x0000, 0x0000, 0x0000, 0x0000, 0x0000, 0x0000, 0x0000, 0x0000, 0x0000, 0x0000, 0x0000, 0x0000, 0x0000, 0x0000, 0x0000, 0x0000, 0x0000, 0x0000, 0x0000, 0x0000, 0x0000, 0x0000, 0x0000, 0x0000, 0x0000, 0x0000, 0x0000,
  0x0000, 0x0000, 0x0000, 0x0000, 0x0000, 0x0000, 0x0000, 0x0000, 0x0000, 0x0000, 0x0000, 0x0000, 0x0000, 0x0000, 0x0000, 0x0000, 0x0000, 0x0000, 0x0000, 0x0000, 0x0000, 0x0000, 0x0000, 0x0000, 0x0000, 0x0000, 0x0000, 0x0000, 0x0000, 0x0000, 0x0000, 0x0000, 0x0000, 0x0000, 0x0000, 0x0000, 0x0000, 0x0000, 0x0000, 0x0000, 0x0000, 0x0000, 0x0000, 0x0000, 0x0000, 0x0000, 0x0000, 0x0000, 0x0000, 0x0000, 0x0000, 0x0000, 0x0000, 0x0000, 0x0000, 0x0000, 0x0000, 0x0000, 0x0000, 0x0000, 0x0000, 0x0000, 0x0000, 0x0000, 0x0000, 0x0000, 0x0000, 0x0000, 0x0000, 0x0000, 0x0000, 0x0000, 0x0000, 0x0000, 0x0000, 0x0000, 0x0000, 0x0000, 0x0000, 0x0000,
  0x0000, 0x0000, 0x0000, 0x0000, 0x0000, 0x0000, 0x0000, 0x0000, 0x0000, 0x0000, 0x0000, 0x0000, 0x0000, 0x0000, 0x0000, 0x0000, 0x0000, 0x0000, 0x0000, 0x0000, 0x0000, 0x0000, 0x0000, 0x0000, 0x0000, 0x0000, 0x0000, 0x0000, 0x0000, 0x0000, 0x0000, 0x0000, 0x0000, 0x0000, 0x0000, 0x0000, 0x0000, 0x0000, 0x0000, 0x0000, 0x0000, 0x0000, 0x0000, 0x0000, 0x0000, 0x0000, 0x0000, 0x0000, 0x0000, 0x0000, 0x0000, 0x0000, 0x0000, 0x0000, 0x0000, 0x0000, 0x0000, 0x0000, 0x0000, 0x0000, 0x0000, 0x0000, 0x0000, 0x0000, 0x0000, 0x0000, 0x0000, 0x0000, 0x0000, 0x0000, 0x0000, 0x0000, 0x0000, 0x0000, 0x0000, 0x0000, 0x0000, 0x0000, 0x0000, 0x0000,
  0x0000, 0x0000, 0x0000, 0x0000, 0x0000, 0x0000, 0x0000, 0x0000, 0x0000, 0x0000, 0x0000, 0x0000, 0x0000, 0x0000, 0x0000, 0x0000, 0x0000, 0x0000, 0x0000, 0x0000, 0x0000, 0x0000, 0x0000, 0x0000, 0x0000, 0x0000, 0x0000, 0x0000, 0x0000, 0x0000, 0x0000, 0x0000, 0x0000, 0x0000, 0x0000, 0x0000, 0x0000, 0x0000, 0x0000, 0x0000, 0x0000, 0x0000, 0x0000, 0x0000, 0x0000, 0x0000, 0x0000, 0x0000, 0x0000, 0x0000, 0x0000, 0x0000, 0x0000, 0x0000, 0x0000, 0x0000, 0x0000, 0x0000, 0x0000, 0x0000, 0x0000, 0x0000, 0x0000, 0x0000, 0x0000, 0x0000, 0x0000, 0x0000, 0x0000, 0x0000, 0x0000, 0x0000, 0x0000, 0x0000, 0x0000, 0x0000, 0x0000, 0x0000, 0x0000, 0x0000,
  0x0000, 0x0000, 0x0000, 0x0000, 0x0000, 0x0000, 0x0000, 0x0000, 0x0000, 0x0000, 0x0000, 0x0000, 0x0000, 0x0000, 0x0000, 0x0000, 0x0000, 0x0000, 0x0000, 0x0000, 0x0000, 0x0000, 0x0000, 0x0000, 0x0000, 0x0000, 0x0000, 0x0000, 0x0000, 0x0000, 0x0000, 0x0000, 0x0000, 0x0000, 0x0000, 0x0000, 0x0000, 0x0000, 0x0000, 0x0000, 0x0000, 0x0000, 0x0000, 0x0000, 0x0000, 0x0000, 0x0000, 0x0000, 0x0000, 0x0000, 0x0000, 0x0000, 0x0000, 0x0000, 0x0000, 0x0000, 0x0000, 0x0000, 0x0000, 0x0000, 0x0000, 0x0000, 0x0000, 0x0000, 0x0000, 0x0000, 0x0000, 0x0000, 0x0000, 0x0000, 0x0000, 0x0000, 0x0000, 0x0000, 0x0000, 0x0000, 0x0000, 0x0000, 0x0000, 0x0000,
  0x0000, 0x0000, 0x0000, 0x0000, 0x0000, 0x0000, 0x0000, 0x0000, 0x0000, 0x0000, 0x0000, 0x0000, 0x0000, 0x0000, 0x0000, 0x0000, 0x0000, 0x0000, 0x0000, 0x0000, 0x0000, 0x0000, 0x0000, 0x0000, 0x0000, 0x0000, 0x0000, 0x0000, 0x0000, 0x0000, 0x0000, 0x0000, 0x0000, 0x0000, 0x0000, 0x0000, 0x0000, 0x0000, 0x0000, 0x0000, 0x0000, 0x0000, 0x0000, 0x0000, 0x0000, 0x0000, 0x0000, 0x0000, 0x0000, 0x0000, 0x0000, 0x0000, 0x0000, 0x0000, 0x0000, 0x0000, 0x0000, 0x0000, 0x0000, 0x0000, 0x0000, 0x0000, 0x0000, 0x0000, 0x0000, 0x0000, 0x0000, 0x0000, 0x0000, 0x0000, 0x0000, 0x0000, 0x0000, 0x0000, 0x0000, 0x0000, 0x0000, 0x0000, 0x0000, 0x0000,
  0x0000, 0x0000, 0x0000, 0x0000, 0x0000, 0x0000, 0x0000, 0x0000, 0x0000, 0x0000, 0x0000, 0x0000, 0x0000, 0x0000, 0x0000, 0x0000, 0x0000, 0x0000, 0x0000, 0x0000, 0x0000, 0x0000, 0x0000, 0x0000, 0x0000, 0x0000, 0x0000, 0x0000, 0x619c, 0x619c, 0x619c, 0x619c, 0x0000, 0x619c, 0x619c, 0x619c, 0x619c, 0x0000, 0x619c, 0x619c, 0x619c, 0x619c, 0x619c, 0x619c, 0x619c, 0x629c, 0x0000, 0x0000, 0x619c, 0x619c, 0x619c, 0x619c, 0x0000, 0x0000, 0x629c, 0x619c, 0x619c, 0x619c, 0x0000, 0x0000, 0x0000, 0x0000, 0x0000, 0x0000, 0x0000, 0x0000, 0x0000, 0x0000, 0x0000, 0x0000, 0x0000, 0x0000, 0x0000, 0x0000, 0x0000, 0x0000, 0x0000, 0x0000, 0x0000, 0x0000,
  0x0000, 0x0000, 0x0000, 0x0000, 0x0000, 0x0000, 0x0000, 0x0000, 0x0000, 0x0000, 0x0000, 0x0000, 0x0000, 0x0000, 0x0000, 0x0000, 0x0000, 0x0000, 0x0000, 0x0000, 0x0000, 0x0000, 0x0000, 0x0000, 0x0000, 0x0000, 0x0000, 0x00ce, 0xc0cd, 0x60bd, 0x81a4, 0x419c, 0x00ce, 0xc0cd, 0x60bd, 0x81a4, 0x419c, 0x00ce, 0xc0cd, 0x80bd, 0x80bd, 0x80bd, 0x80bd, 0x20b5, 0x619c, 0x619c, 0x619c, 0x00ce, 0xc0cd, 0x60bd, 0x81a4, 0x419c, 0x0000, 0xe0cd, 0xe0cd, 0x80c5, 0xc1a4, 0x419c, 0x0000, 0x0000, 0x0000, 0x0000, 0x0000, 0x0000, 0x0000, 0x0000, 0x0000, 0x0000, 0x0000, 0x0000, 0x0000, 0x0000, 0x0000, 0x0000, 0x0000, 0x0000, 0x0000, 0x0000, 0x0000, 0x0000,
  0x0000, 0x0000, 0x0000, 0x0000, 0x0000, 0x0000, 0x0000, 0x0000, 0x0000, 0x0000, 0x0000, 0x0000, 0x0000, 0x0000, 0x0000, 0x0000, 0x0000, 0x0000, 0x0000, 0x0000, 0x0000, 0x0000, 0x0000, 0x0000, 0x0000, 0x0000, 0x0000, 0xe0cd, 0x00ce, 0xc0cd, 0x81a4, 0x419c, 0xe0cd, 0x00ce, 0xc0cd, 0x81a4, 0x60bd, 0x00ce, 0xa0c5, 0xc1ac, 0x80bd, 0xe0cd, 0x00ce, 0xe0cd, 0x80bd, 0x81a4, 0x419c, 0xe0cd, 0x00ce, 0xc0cd, 0x81a4, 0x419c, 0x0000, 0x00ce, 0x00ce, 0x00ce, 0xe1ac, 0x419c, 0x0000, 0x0000, 0x0000, 0x0000, 0x0000, 0x0000, 0x0000, 0x0000, 0x0000, 0x0000, 0x0000, 0x0000, 0x0000, 0x0000, 0x0000, 0x0000, 0x0000, 0x0000, 0x0000, 0x0000, 0x0000, 0x0000,
  0x0000, 0x0000, 0x0000, 0x0000, 0x0000, 0x0000, 0x0000, 0x0000, 0x0000, 0x0000, 0x0000, 0x0000, 0x0000, 0x0000, 0x0000, 0x0000, 0x0000, 0x0000, 0x0000, 0x0000, 0x0000, 0x0000, 0x0000, 0x0000, 0x0000, 0x0000, 0x0000, 0xe0cd, 0x00ce, 0xc0cd, 0x81a4, 0x619c, 0x40b5, 0x00ce, 0x00ce, 0x01b5, 0xe0cd, 0x00ce, 0x80bd, 0x619c, 0x419c, 0x0000, 0xe0cd, 0x00ce, 0xc0cd, 0x81a4, 0x419c, 0xe0cd, 0x00ce, 0xc0cd, 0x81a4, 0x419c, 0x0000, 0x00ce, 0x00ce, 0x00ce, 0xe1ac, 0x419c, 0x0000, 0x0000, 0x0000, 0x3690, 0x3690, 0x0000, 0x0000, 0x0000, 0x0000, 0x0000, 0x0000, 0x0000, 0x0000, 0x0000, 0x0000, 0x0000, 0x0000, 0x0000, 0x0000, 0x0000, 0x0000, 0x0000,
  0x0000, 0x0000, 0x0000, 0x0000, 0x0000, 0x0000, 0x0000, 0x0000, 0x0000, 0x0000, 0x0000, 0x0000, 0x0000, 0x0000, 0x0000, 0x0000, 0x0000, 0x0000, 0x0000, 0x6f02, 0x4e02, 0x4e02, 0x0000, 0x0000, 0x0000, 0x0000, 0x0000, 0x20c6, 0xe0cd, 0xe0cd, 0xc0cd, 0xc0cd, 0xe0cd, 0x00ce, 0x40d6, 0x40ad, 0x00ce, 0x00ce, 0x80bd, 0x619c, 0x419c, 0x0000, 0xe0cd, 0x00ce, 0xc0cd, 0x81a4, 0x419c, 0xe0cd, 0x00ce, 0xc0cd, 0x81a4, 0x419c, 0x0000, 0x00ce, 0x00ce, 0x00ce, 0xe1ac, 0x419c, 0x0000, 0x0000, 0x0000, 0x1598, 0x1698, 0x3698, 0x3380, 0x0208, 0x0000, 0x0000, 0x0000, 0x0000, 0x0000, 0x0000, 0x0000, 0x0000, 0x0000, 0x0000, 0x0000, 0x0000, 0x0000, 0x0000,
  0x0000, 0x0000, 0x0000, 0x0000, 0x0000, 0x0000, 0x0000, 0x0000, 0x0000, 0x0000, 0x0000, 0x0000, 0x0000, 0x0000, 0x0000, 0x0000, 0x0000, 0x0000, 0x0000, 0x0000, 0x1002, 0xaa02, 0x0000, 0x9604, 0x9604, 0x750c, 0x6145, 0x6145, 0x40ad, 0x01ce, 0x00ce, 0x00ce, 0x20b5, 0x619c, 0x41a8, 0x20b0, 0x40c4, 0x00ce, 0x80bd, 0x619c, 0x419c, 0x0000, 0xe0cd, 0x00ce, 0xc0cd, 0x81a4, 0x419c, 0xe0cd, 0x00ce, 0xc0cd, 0x81a4, 0x419c, 0x0000, 0x00ce, 0x00ce, 0x00ce, 0xe1ac, 0x419c, 0x6145, 0x6145, 0x6145, 0x4e02, 0x4e02, 0x15a8, 0x0520, 0x0000, 0x0000, 0x0000, 0x0000, 0x0000, 0x0000, 0x0000, 0x0000, 0x0000, 0x0000, 0x0000, 0x0000, 0x0000, 0x0000, 0x0000,
  0x0000, 0x0000, 0x0000, 0x0000, 0x0000, 0x0000, 0x0000, 0x0000, 0x0000, 0x0000, 0x0000, 0x0000, 0x0000, 0x0000, 0x0000, 0x0000, 0x0000, 0x0000, 0x4601, 0x9604, 0x750c, 0x0000, 0xe045, 0x4055, 0x0000, 0x0000, 0xb002, 0x1002, 0x0000, 0xc1cd, 0x00ce, 0x00ce, 0x20b5, 0x619c, 0x0000, 0x0000, 0x00ce, 0x00ce, 0x80c5, 0x619c, 0x619c, 0x619c, 0x20b5, 0x00ce, 0x00ce, 0x039d, 0xaa02, 0x00ce, 0x00ce, 0xc0cd, 0xa1a4, 0x619c, 0x619c, 0xe1ac, 0x00ce, 0x00ce, 0x00ce, 0x00b8, 0x00a8, 0xff07, 0xf704, 0x5505, 0x0000, 0x0000, 0x0000, 0x0000, 0x0000, 0x0000, 0x0000, 0x0000, 0x0000, 0x0000, 0x0000, 0x0000, 0x0000, 0x0000, 0x0000, 0x0000, 0x0000, 0x0000,
  0x0000, 0x0000, 0x0000, 0x0000, 0x0000, 0x0000, 0x0000, 0x0000, 0x0000, 0x0000, 0x0000, 0x0000, 0x0000, 0x0000, 0x0000, 0x0000, 0x0000, 0x0000, 0x0000, 0x0000, 0x0000, 0x0000, 0x4145, 0x6145, 0x0000, 0x0000, 0x4e02, 0x4e02, 0x0000, 0x40d6, 0x00ce, 0x00ce, 0xe0cd, 0xe044, 0x8145, 0x4055, 0x0000, 0xe0cd, 0xc1cd, 0x62cd, 0xe0cd, 0x00ce, 0x00ce, 0x00ce, 0x6f02, 0x4e02, 0xcb29, 0x00b0, 0x00ce, 0x00ce, 0x00ce, 0x00ce, 0x00ce, 0x00ce, 0x00ce, 0x40d6, 0x0000, 0x20a8, 0x20b0, 0x960c, 0x9604, 0x9604, 0x824d, 0x4145, 0x0000, 0x0000, 0x0000, 0x0000, 0x0000, 0x0000, 0x0000, 0x0000, 0x0000, 0x0000, 0x0000, 0x0000, 0x0000, 0x0000, 0x0000, 0x0000,
  0x0000, 0x0000, 0x0000, 0x0000, 0x0000, 0x0000, 0x0000, 0x0000, 0x0000, 0x0000, 0x0000, 0x0000, 0x0000, 0x0000, 0x0000, 0x0000, 0x0000, 0x0000, 0x0000, 0x00b8, 0x20b0, 0x00b0, 0x7698, 0x5698, 0x0000, 0x0000, 0x819c, 0x619c, 0x819c, 0x00b8, 0x20b0, 0x00b0, 0x0000, 0x414d, 0x6145, 0x6145, 0x819c, 0x619c, 0x8f99, 0x3690, 0x7590, 0x819c, 0x619c, 0x619c, 0x619c, 0x619c, 0x80a8, 0x20b0, 0x409c, 0x619c, 0x619c, 0x409c, 0x0000, 0x824d, 0x614d, 0xe045, 0x0000, 0x819c, 0x619c, 0xe39b, 0x9490, 0x1698, 0x6145, 0x6145, 0x0000, 0x0000, 0x0000, 0x0000, 0x0000, 0x0000, 0x0000, 0x0000, 0x0000, 0x0000, 0x0000, 0x0000, 0x0000, 0x0000, 0x0000, 0x0000,
  0x0000, 0x0000, 0x0000, 0x0000, 0x0000, 0x0000, 0x0000, 0x0000, 0x0000, 0x0000, 0x0000, 0x0000, 0x0000, 0x0000, 0x0000, 0x0000, 0x0000, 0x0000, 0x0000, 0x00b0, 0x20b0, 0x20b0, 0x3590, 0x3590, 0xa0d6, 0xe0cd, 0xe1ac, 0x81a4, 0x619c, 0x00b0, 0x20b0, 0xe1a1, 0x619c, 0x609c, 0xa0d6, 0xe0cd, 0xe1ac, 0x81a4, 0x619c, 0xa0d6, 0xe0cd, 0xe1ac, 0xc1ac, 0xc1ac, 0xc1ac, 0x619c, 0x419c, 0xc1cd, 0x20b5, 0xc1a4, 0x619c, 0x619c, 0x819c, 0x6145, 0x6145, 0x2145, 0xe0cd, 0x01ad, 0xa1a4, 0x039c, 0x9379, 0x5671, 0x0000, 0x0000, 0x0000, 0x0000, 0x0000, 0x0000, 0x0000, 0x0000, 0x0000, 0x0000, 0x0000, 0x0000, 0x0000, 0x0000, 0x0000, 0x0000, 0x0000, 0x0000,
  0x0000, 0x0000, 0x0000, 0x0000, 0x0000, 0x0000, 0x0000, 0x0000, 0x0000, 0x0000, 0x0000, 0x0000, 0x0000, 0x0000, 0x0000, 0x0000, 0x0000, 0x0000, 0x0000, 0x1002, 0x4e02, 0x6f02, 0x0000, 0x0000, 0xc1cd, 0x00ce, 0x00ce, 0x20b5, 0x619c, 0xe0bd, 0x00ce, 0x01b5, 0xa1a4, 0x619c, 0xc1cd, 0x00ce, 0x00ce, 0x20b5, 0x619c, 0x20d6, 0x00ce, 0x00ce, 0x00ce, 0xc0cd, 0x80c5, 0x81bd, 0x0000, 0xe0cd, 0x00ce, 0xe0cd, 0x01ad, 0x81a4, 0x619c, 0x619c, 0x0000, 0x0000, 0x00ce, 0x00ce, 0x80bd, 0x6294, 0x931c, 0x9504, 0x20a8, 0x20a8, 0x0000, 0x0000, 0x0000, 0x0000, 0x0000, 0x0000, 0x0000, 0x0000, 0x0000, 0x0000, 0x0000, 0x0000, 0x0000, 0x0000, 0x0000, 0x0000,
  0x0000, 0x0000, 0x0000, 0x0000, 0x0000, 0x0000, 0x0000, 0x0000, 0x0000, 0x0000, 0x0000, 0x0000, 0x0000, 0x0000, 0x0000, 0x0000, 0x0000, 0x0000, 0x0000, 0x9002, 0x4e02, 0x4e02, 0x0000, 0x0000, 0xc1cd, 0x00ce, 0x00ce, 0x20b5, 0x619c, 0xc1cd, 0x00ce, 0x00ce, 0x20b5, 0x619c, 0xc1cd, 0x00ce, 0x00ce, 0x20b5, 0x619c, 0x0000, 0x0000, 0x00ce, 0x00ce, 0x80bd, 0x619c, 0x419c, 0x4e02, 0x049d, 0x00ce, 0x00ce, 0x00ce, 0x40bd, 0xa1a4, 0x619c, 0x619c, 0x009c, 0x00ce, 0x00ce, 0x80bd, 0x619c, 0x419c, 0x0000, 0x20b0, 0x20b0, 0x0000, 0x0000, 0x0000, 0x0000, 0x0000, 0x0000, 0x0000, 0x0000, 0x0000, 0x0000, 0x0000, 0x0000, 0x0000, 0x0000, 0x0000, 0x0000,
  0x0000, 0x0000, 0x0000, 0x0000, 0x0000, 0x0000, 0x0000, 0x0000, 0x0000, 0x0000, 0x0000, 0x0000, 0x0000, 0x0000, 0x0000, 0x0000, 0x0000, 0x0000, 0x0318, 0x3690, 0x17a0, 0x0000, 0x20b0, 0x20b0, 0xc1cd, 0x00ce, 0x00ce, 0x20b5, 0x619c, 0xc1cd, 0x00ce, 0x00ce, 0x20b5, 0x619c, 0xc1cd, 0x00ce, 0x00ce, 0x20b5, 0xa49b, 0x3690, 0x17a0, 0x00ce, 0x00ce, 0x80bd, 0x619c, 0x419c, 0x4e02, 0xa584, 0x00ce, 0xe0cd, 0x60bd, 0xc0cd, 0x80c5, 0xe1ac, 0x619c, 0x619c, 0xc0c5, 0x00ce, 0x80bd, 0x619c, 0x419c, 0x9604, 0xb604, 0x4145, 0x4134, 0x4000, 0x0000, 0x0000, 0x0000, 0x0000, 0x0000, 0x0000, 0x0000, 0x0000, 0x0000, 0x0000, 0x0000, 0x0000, 0x0000, 0x0000,
  0x0000, 0x0000, 0x0000, 0x0000, 0x0000, 0x0000, 0x0000, 0x0000, 0x0000, 0x0000, 0x0000, 0x0000, 0x0000, 0x0000, 0x0000, 0x0000, 0x0000, 0x0000, 0x0318, 0x3590, 0x1698, 0x0000, 0x20a8, 0x20b0, 0xc1cd, 0x00ce, 0x00ce, 0x20b5, 0x619c, 0xa1a4, 0xe0cd, 0x00ce, 0x20b5, 0x619c, 0xa1a4, 0xe0cd, 0x00ce, 0x60bd, 0x279b, 0x3590, 0x1698, 0x00ce, 0x00ce, 0x80bd, 0x619c, 0x419c, 0x3690, 0x07bc, 0x00ce, 0xc0cd, 0x81a4, 0x40b5, 0x00ce, 0xc0c5, 0x20b5, 0x819c, 0x80bd, 0x00ce, 0x80bd, 0x619c, 0x419c, 0x9604, 0x7504, 0x614d, 0x613c, 0x4000, 0x0000, 0x0000, 0x0000, 0x0000, 0x0000, 0x0000, 0x0000, 0x0000, 0x0000, 0x0000, 0x0000, 0x0000, 0x0000, 0x0000,
  0x0000, 0x0000, 0x0000, 0x0000, 0x0000, 0x0000, 0x0000, 0x0000, 0x0000, 0x0000, 0x0000, 0x0000, 0x0000, 0x0000, 0x0000, 0x0000, 0x0000, 0x0000, 0x0000, 0x0000, 0x0000, 0x6145, 0x6145, 0x0000, 0xc0d5, 0x00ce, 0xe0cd, 0xa0c5, 0x40bd, 0x60bd, 0xe0cd, 0x00ce, 0xa0c5, 0x40bd, 0x60bd, 0xe0cd, 0x00ce, 0xe85b, 0x4e02, 0x0000, 0x0000, 0x00ce, 0x00ce, 0x80bd, 0x619c, 0x619c, 0xae99, 0x27bc, 0x00ce, 0xc0cd, 0x81a4, 0x419c, 0x00d6, 0x00ce, 0xe0cd, 0x60bd, 0xc0cd, 0x00ce, 0x80bd, 0x619c, 0x419c, 0x3690, 0x3690, 0x0000, 0x0000, 0x0000, 0x0000, 0x0000, 0x0000, 0x0000, 0x0000, 0x0000, 0x0000, 0x0000, 0x0000, 0x0000, 0x0000, 0x0000, 0x0000, 0x0000,
  0x0000, 0x0000, 0x0000, 0x0000, 0x0000, 0x0000, 0x0000, 0x0000, 0x0000, 0x0000, 0x0000, 0x0000, 0x0000, 0x0000, 0x0000, 0x0000, 0x0000, 0x0000, 0x0000, 0x7504, 0x9604, 0x0a2d, 0x6145, 0x0000, 0x00a8, 0x20b0, 0x80c3, 0x00ce, 0x00ce, 0x00ce, 0x00ce, 0xe0cd, 0x00ce, 0x00ce, 0x00ce, 0x00ce, 0xe1d5, 0x2e02, 0x4e02, 0xe0cd, 0x00ce, 0x00ce, 0x00ce, 0xc0cd, 0x60bd, 0xa1a4, 0x819c, 0xe0cd, 0x00ce, 0xe0cd, 0xc0ac, 0x819c, 0x0000, 0xe1d5, 0xe0cd, 0xe0cd, 0x00ce, 0x00ce, 0xc0c5, 0x619c, 0x009c, 0x5698, 0x3598, 0x9504, 0xf203, 0x4100, 0x0000, 0x0000, 0x0000, 0x0000, 0x0000, 0x0000, 0x0000, 0x0000, 0x0000, 0x0000, 0x0000, 0x0000, 0x0000, 0x0000,
  0x0000, 0x0000, 0x0000, 0x0000, 0x0000, 0x0000, 0x0000, 0x0000, 0x0000, 0x0000, 0x0000, 0x0000, 0x0000, 0x0000, 0x0000, 0x0000, 0x0000, 0x0000, 0x0000, 0x1304, 0x9604, 0xe490, 0x20b0, 0x0000, 0x0098, 0x20b0, 0x41b0, 0x00d6, 0x00ce, 0xa5a5, 0xb50c, 0x9504, 0x00d6, 0x00ce, 0x00ce, 0xe0bd, 0x20a8, 0x20b0, 0x0000, 0xe0bd, 0x00ce, 0x00ce, 0x00ce, 0x00ce, 0x00ce, 0xe0bd, 0x0000, 0x00d6, 0x00ce, 0x00ce, 0xe0bd, 0x0000, 0x4e02, 0x4e02, 0x0000, 0x0000, 0xe0cd, 0x00ce, 0xe0cd, 0x0000, 0x0000, 0x0000, 0x4e02, 0xb002, 0x5003, 0x2000, 0x0000, 0x0000, 0x0000, 0x0000, 0x0000, 0x0000, 0x0000, 0x0000, 0x0000, 0x0000, 0x0000, 0x0000, 0x0000, 0x0000,
  0x0000, 0x0000, 0x0000, 0x0000, 0x0000, 0x0000, 0x0000, 0x0000, 0x0000, 0x0000, 0x0000, 0x0000, 0x0000, 0x0000, 0x0000, 0x0000, 0x0000, 0x0000, 0x0000, 0x0000, 0x0000, 0x20b0, 0x41b0, 0x0000, 0x1698, 0x3690, 0x3690, 0x0000, 0x0000, 0x1504, 0x9504, 0x433d, 0x6145, 0x0000, 0x0000, 0x0000, 0x20b0, 0x41b0, 0x0000, 0x0000, 0x0000, 0x0000, 0x0000, 0x6145, 0x6145, 0x2145, 0x0000, 0x3590, 0x3590, 0x00b0, 0x20b0, 0x20b0, 0x6e02, 0x4e02, 0x1698, 0x3690, 0x3690, 0x0000, 0x20b0, 0x20b0, 0x00b0, 0x0000, 0x6e02, 0x4e02, 0x0000, 0x0000, 0x0000, 0x0000, 0x0000, 0x0000, 0x0000, 0x0000, 0x0000, 0x0000, 0x0000, 0x0000, 0x0000, 0x0000, 0x0000, 0x0000,
  0x0000, 0x0000, 0x0000, 0x0000, 0x0000, 0x0000, 0x0000, 0x0000, 0x0000, 0x0000, 0x0000, 0x0000, 0x0000, 0x0000, 0x0000, 0x0000, 0x0000, 0x0000, 0x0000, 0x6145, 0x6145, 0x414d, 0x0000, 0x4f02, 0x4e0a, 0xf360, 0x1698, 0x0000, 0x41a8, 0x20b0, 0x61a8, 0x4145, 0x414d, 0x414d, 0x6145, 0x6145, 0x4e02, 0x4e02, 0x0000, 0x550c, 0x9604, 0x950c, 0x0000, 0x824d, 0x614d, 0xe045, 0x0000, 0x7698, 0x5698, 0x00b8, 0x20b0, 0x00b0, 0x0000, 0x4f02, 0x4e0a, 0xf360, 0x1698, 0x9604, 0x3414, 0x20b0, 0x00b8, 0x6145, 0x6145, 0x0000, 0x0000, 0x0000, 0x0000, 0x0000, 0x0000, 0x0000, 0x0000, 0x0000, 0x0000, 0x0000, 0x0000, 0x0000, 0x0000, 0x0000, 0x0000, 0x0000,
  0x0000, 0x0000, 0x0000, 0x0000, 0x0000, 0x0000, 0x0000, 0x0000, 0x0000, 0x0000, 0x0000, 0x0000, 0x0000, 0x0000, 0x0000, 0x0000, 0x0000, 0x0000, 0x0000, 0x4055, 0x8145, 0xe044, 0x0000, 0x1002, 0x6f02, 0xaa02, 0x9604, 0x9504, 0x0098, 0x41b0, 0x00a8, 0x0000, 0x0000, 0xe044, 0x8145, 0x4055, 0x2e02, 0x7580, 0x3690, 0x5505, 0x960c, 0x1304, 0x0000, 0x20b0, 0x20b0, 0x41b0, 0x0000, 0x9504, 0x9604, 0x0000, 0x0000, 0x0000, 0x0000, 0x1002, 0x6f02, 0xaa02, 0x0000, 0x5604, 0x7504, 0x0000, 0x0000, 0x4145, 0x824d, 0x0000, 0x0000, 0x0000, 0x0000, 0x0000, 0x0000, 0x0000, 0x0000, 0x0000, 0x0000, 0x0000, 0x0000, 0x0000, 0x0000, 0x0000, 0x0000, 0x0000,
  0x0000, 0x0000, 0x0000, 0x0000, 0x0000, 0x0000, 0x0000, 0x0000, 0x0000, 0x0000, 0x0000, 0x0000, 0x0000, 0x0000, 0x0000, 0x0000, 0x0000, 0x0000, 0x0000, 0x0000, 0x0000, 0x0000, 0x0000, 0x0000, 0x0000, 0x0000, 0x2000, 0x0000, 0x0000, 0x0000, 0x0000, 0x0000, 0x0000, 0x0000, 0x0000, 0x0000, 0x0000, 0x0000, 0x0000, 0x0000, 0x0000, 0x0000, 0x0000, 0x0000, 0x0000, 0x0000, 0x0000, 0x0000, 0x2000, 0x0000, 0x0000, 0x0000, 0x0000, 0x0000, 0x0000, 0x0000, 0x0000, 0x0000, 0x0000, 0x0000, 0x0000, 0x0000, 0x0000, 0x0000, 0x0000, 0x0000, 0x0000, 0x0000, 0x0000, 0x0000, 0x0000, 0x0000, 0x0000, 0x0000, 0x0000, 0x0000, 0x0000, 0x0000, 0x0000, 0x0000,
  0x0000, 0x0000, 0x0000, 0x0000, 0x0000, 0x0000, 0x0000, 0x0000, 0x0000, 0x0000, 0x0000, 0x0000, 0x0000, 0x0000, 0x0000, 0x0000, 0x0000, 0x0000, 0x0000, 0x0000, 0x0000, 0x0000, 0x0000, 0x0000, 0x0000, 0x0000, 0x0000, 0x0000, 0x0000, 0x0000, 0x0000, 0x0000, 0x0000, 0x0000, 0x0000, 0x0000, 0x0000, 0x0000, 0x0000, 0x0000, 0x0000, 0x0000, 0x0000, 0x0000, 0x0000, 0x0000, 0x0000, 0x0000, 0x0000, 0x0000, 0x0000, 0x0000, 0x0000, 0x0000, 0x0000, 0x0000, 0x0000, 0x0000, 0x0000, 0x0000, 0x0000, 0x0000, 0x0000, 0x0000, 0x0000, 0x0000, 0x0000, 0x0000, 0x0000, 0x0000, 0x0000, 0x0000, 0x0000, 0x0000, 0x0000, 0x0000, 0x0000, 0x0000, 0x0000, 0x0000,
  0x0000, 0x0000, 0x0000, 0x0000, 0x0000, 0x0000, 0x0000, 0x0000, 0x0000, 0x0000, 0x0000, 0x0000, 0x0000, 0x0000, 0x0000, 0x0000, 0x0000, 0x0000, 0x0000, 0x0000, 0x0000, 0x0000, 0x0000, 0x0000, 0x0000, 0x0000, 0x0000, 0x0000, 0x0000, 0x0000, 0x0000, 0x0000, 0x0000, 0x0000, 0x0000, 0x0000, 0x0000, 0x0000, 0x0000, 0x0000, 0x0000, 0x0000, 0x0000, 0x0000, 0x0000, 0x0000, 0x0000, 0x0000, 0x0000, 0x0000, 0x0000, 0x0000, 0x0000, 0x0000, 0x0000, 0x0000, 0x0000, 0x0000, 0x0000, 0x0000, 0x0000, 0x0000, 0x0000, 0x0000, 0x0000, 0x0000, 0x0000, 0x0000, 0x0000, 0x0000, 0x0000, 0x0000, 0x0000, 0x0000, 0x0000, 0x0000, 0x0000, 0x0000, 0x0000, 0x0000,
  0x0000, 0x0000, 0x0000, 0x0000, 0x0000, 0x0000, 0x0000, 0x0000, 0x0000, 0x0000, 0x0000, 0x0000, 0x0000, 0x0000, 0x0000, 0x0000, 0x0000, 0x0000, 0x0000, 0x0000, 0x0000, 0x0000, 0x0000, 0x0000, 0x0000, 0x0000, 0x0000, 0x0000, 0x0000, 0x0000, 0x0000, 0x0000, 0x0000, 0x0000, 0x0000, 0x0000, 0x0000, 0x0000, 0x0000, 0x0000, 0x0000, 0x0000, 0x0000, 0x0000, 0x0000, 0x0000, 0x0000, 0x0000, 0x0000, 0x0000, 0x0000, 0x0000, 0x0000, 0x0000, 0x0000, 0x0000, 0x0000, 0x0000, 0x0000, 0x0000, 0x0000, 0x0000, 0x0000, 0x0000, 0x0000, 0x0000, 0x0000, 0x0000, 0x0000, 0x0000, 0x0000, 0x0000, 0x0000, 0x0000, 0x0000, 0x0000, 0x0000, 0x0000, 0x0000, 0x0000,
  0x0000, 0x0000, 0x0000, 0x0000, 0x0000, 0x0000, 0x0000, 0x0000, 0x0000, 0x0000, 0x0000, 0x0000, 0x0000, 0x0000, 0x0000, 0x0000, 0x0000, 0x0000, 0x0000, 0x0000, 0x0000, 0x0000, 0x0000, 0x0000, 0x0000, 0x0000, 0x0000, 0x0000, 0x0000, 0x0000, 0x0000, 0x0000, 0x0000, 0x0000, 0x0000, 0x0000, 0x0000, 0x0000, 0x0000, 0x0000, 0x0000, 0x0000, 0x0000, 0x0000, 0x0000, 0x0000, 0x0000, 0x0000, 0x0000, 0x0000, 0x0000, 0x0000, 0x0000, 0x0000, 0x0000, 0x0000, 0x0000, 0x0000, 0x0000, 0x0000, 0x0000, 0x0000, 0x0000, 0x0000, 0x0000, 0x0000, 0x0000, 0x0000, 0x0000, 0x0000, 0x0000, 0x0000, 0x0000, 0x0000, 0x0000, 0x0000, 0x0000, 0x0000, 0x0000, 0x0000,
  0x0000, 0x0000, 0x0000, 0x0000, 0x0000, 0x0000, 0x0000, 0x0000, 0x0000, 0x0000, 0x0000, 0x0000, 0x0000, 0x0000, 0x0000, 0x0000, 0x0000, 0x0000, 0x0000, 0x0000, 0x0000, 0x0000, 0x0000, 0x0000, 0x0000, 0x0000, 0x0000, 0x0000, 0x0000, 0x0000, 0x0000, 0x0000, 0x0000, 0x0000, 0x0000, 0x0000, 0x0000, 0x0000, 0x0000, 0x0000, 0x0000, 0x0000, 0x0000, 0x0000, 0x0000, 0x0000, 0x0000, 0x0000, 0x0000, 0x0000, 0x0000, 0x0000, 0x0000, 0x0000, 0x0000, 0x0000, 0x0000, 0x0000, 0x0000, 0x0000, 0x0000, 0x0000, 0x0000, 0x0000, 0x0000, 0x0000, 0x0000, 0x0000, 0x0000, 0x0000, 0x0000, 0x0000, 0x0000, 0x0000, 0x0000, 0x0000, 0x0000, 0x0000, 0x0000, 0x0000,
  0x0000, 0x0000, 0x0000, 0x0000, 0x0000, 0x0000, 0x0000, 0x0000, 0x0000, 0x0000, 0x0000, 0x0000, 0x0000, 0x0000, 0x0000, 0x0000, 0x0000, 0x0000, 0x0000, 0x0000, 0x0000, 0x0000, 0x0000, 0x0000, 0x0000, 0x0000, 0x0000, 0x0000, 0x0000, 0x0000, 0x0000, 0x0000, 0x0000, 0x0000, 0x0000, 0x0000, 0x0000, 0x0000, 0x0000, 0x0000, 0x0000, 0x0000, 0x0000, 0x0000, 0x0000, 0x0000, 0x0000, 0x0000, 0x0000, 0x0000, 0x0000, 0x0000, 0x0000, 0x0000, 0x0000, 0x0000, 0x0000, 0x0000, 0x0000, 0x0000, 0x0000, 0x0000, 0x0000, 0x0000, 0x0000, 0x0000, 0x0000, 0x0000, 0x0000, 0x0000, 0x0000, 0x0000, 0x0000, 0x0000, 0x0000, 0x0000, 0x0000, 0x0000, 0x0000, 0x0000,
  0x0000, 0x0000, 0x0000, 0x0000, 0x0000, 0x0000, 0x0000, 0x0000, 0x0000, 0x0000, 0x0000, 0x0000, 0x0000, 0x0000, 0x0000, 0x0000, 0x0000, 0x0000, 0x0000, 0x0000, 0x0000, 0x0000, 0x0000, 0x0000, 0x0000, 0x0000, 0x0000, 0x0000, 0x0000, 0x0000, 0x0000, 0x0000, 0x0000, 0x0000, 0x0000, 0x0000, 0x0000, 0x0000, 0x0000, 0x0000, 0x0000, 0x0000, 0x0000, 0x0000, 0x0000, 0x0000, 0x0000, 0x0000, 0x0000, 0x0000, 0x0000, 0x0000, 0x0000, 0x0000, 0x0000, 0x0000, 0x0000, 0x0000, 0x0000, 0x0000, 0x0000, 0x0000, 0x0000, 0x0000, 0x0000, 0x0000, 0x0000, 0x0000, 0x0000, 0x0000, 0x0000, 0x0000, 0x0000, 0x0000, 0x0000, 0x0000, 0x0000, 0x0000, 0x0000, 0x0000,
  0x0000, 0x0000, 0x0000, 0x0000, 0x0000, 0x0000, 0x0000, 0x0000, 0x0000, 0x0000, 0x0000, 0x0000, 0x0000, 0x0000, 0x0000, 0x0000, 0x0000, 0x0000, 0x0000, 0x0000, 0x0000, 0x0000, 0x0000, 0x0000, 0x0000, 0x0000, 0x0000, 0x0000, 0x0000, 0x0000, 0x0000, 0x0000, 0x0000, 0x0000, 0x0000, 0x0000, 0x0000, 0x0000, 0x0000, 0x0000, 0x0000, 0x0000, 0x0000, 0x0000, 0x0000, 0x0000, 0x0000, 0x0000, 0x0000, 0x0000, 0x0000, 0x0000, 0x0000, 0x0000, 0x0000, 0x0000, 0x0000, 0x0000, 0x0000, 0x0000, 0x0000, 0x0000, 0x0000, 0x0000, 0x0000, 0x0000, 0x0000, 0x0000, 0x0000, 0x0000, 0x0000, 0x0000, 0x0000, 0x0000, 0x0000, 0x0000, 0x0000, 0x0000, 0x0000, 0x0000,
  0x0000, 0x0000, 0x0000, 0x0000, 0x0000, 0x0000, 0x0000, 0x0000, 0x0000, 0x0000, 0x0000, 0x0000, 0x0000, 0x0000, 0x0000, 0x0000, 0x0000, 0x0000, 0x0000, 0x0000, 0x0000, 0x0000, 0x0000, 0x0000, 0x0000, 0x0000, 0x0000, 0x0000, 0x0000, 0x0000, 0x0000, 0x0000, 0x0000, 0x0000, 0x0000, 0x0000, 0x0000, 0x0000, 0x0000, 0x0000, 0x0000, 0x0000, 0x0000, 0x0000, 0x0000, 0x0000, 0x0000, 0x0000, 0x0000, 0x0000, 0x0000, 0x0000, 0x0000, 0x0000, 0x0000, 0x0000, 0x0000, 0x0000, 0x0000, 0x0000, 0x0000, 0x0000, 0x0000, 0x0000, 0x0000, 0x0000, 0x0000, 0x0000, 0x0000, 0x0000, 0x0000, 0x0000, 0x0000, 0x0000, 0x0000, 0x0000, 0x0000, 0x0000, 0x0000, 0x0000,
  0x0000, 0x0000, 0x0000, 0x0000, 0x0000, 0x0000, 0x0000, 0x0000, 0x0000, 0x0000, 0x0000, 0x0000, 0x0000, 0x0000, 0x0000, 0x0000, 0x0000, 0x0000, 0x0000, 0x0000, 0x0000, 0x0000, 0x0000, 0x0000, 0x0000, 0x0000, 0x0000, 0x0000, 0x0000, 0x0000, 0x0000, 0x0000, 0x0000, 0x0000, 0x0000, 0x0000, 0x0000, 0x0000, 0x0000, 0x0000, 0x0000, 0x0000, 0x0000, 0x0000, 0x0000, 0x0000, 0x0000, 0x0000, 0x0000, 0x0000, 0x0000, 0x0000, 0x0000, 0x0000, 0x0000, 0x0000, 0x0000, 0x0000, 0x0000, 0x0000, 0x0000, 0x0000, 0x0000, 0x0000, 0x0000, 0x0000, 0x0000, 0x0000, 0x0000, 0x0000, 0x0000, 0x0000, 0x0000, 0x0000, 0x0000, 0x0000, 0x0000, 0x0000, 0x0000, 0x0000,
  0x0000, 0x0000, 0x0000, 0x0000, 0x0000, 0x0000, 0x0000, 0x0000, 0x0000, 0x0000, 0x0000, 0x0000, 0x0000, 0x0000, 0x0000, 0x0000, 0x0000, 0x0000, 0x0000, 0x0000, 0x0000, 0x0000, 0x0000, 0x0000, 0x0000, 0x0000, 0x0000, 0x0000, 0x0000, 0x0000, 0x0000, 0x0000, 0x0000, 0x0000, 0x0000, 0x0000, 0x0000, 0x0000, 0x0000, 0x0000, 0x0000, 0x0000, 0x0000, 0x0000, 0x0000, 0x0000, 0x0000, 0x0000, 0x0000, 0x0000, 0x0000, 0x0000, 0x0000, 0x0000, 0x0000, 0x0000, 0x0000, 0x0000, 0x0000, 0x0000, 0x0000, 0x0000, 0x0000, 0x0000, 0x0000, 0x0000, 0x0000, 0x0000, 0x0000, 0x0000, 0x0000, 0x0000, 0x0000, 0x0000, 0x0000, 0x0000, 0x0000, 0x0000, 0x0000, 0x0000,
  0x0000, 0x0000, 0x0000, 0x0000, 0x0000, 0x0000, 0x0000, 0x0000, 0x0000, 0x0000, 0x0000, 0x0000, 0x0000, 0x0000, 0x0000, 0x0000, 0x0000, 0x0000, 0x0000, 0x0000, 0x0000, 0x0000, 0x0000, 0x0000, 0x0000, 0x0000, 0x0000, 0x0000, 0x0000, 0x0000, 0x0000, 0x0000, 0x0000, 0x0000, 0x0000, 0x0000, 0x0000, 0x0000, 0x0000, 0x0000, 0x0000, 0x0000, 0x0000, 0x0000, 0x0000, 0x0000, 0x0000, 0x0000, 0x0000, 0x0000, 0x0000, 0x0000, 0x0000, 0x0000, 0x0000, 0x0000, 0x0000, 0x0000, 0x0000, 0x0000, 0x0000, 0x0000, 0x0000, 0x0000, 0x0000, 0x0000, 0x0000, 0x0000, 0x0000, 0x0000, 0x0000, 0x0000, 0x0000, 0x0000, 0x0000, 0x0000, 0x0000, 0x0000, 0x0000, 0x0000,
  0x0000, 0x0000, 0x0000, 0x0000, 0x0000, 0x0000, 0x0000, 0x0000, 0x0000, 0x0000, 0x0000, 0x0000, 0x0000, 0x0000, 0x0000, 0x0000, 0x0000, 0x0000, 0x0000, 0x0000, 0x0000, 0x0000, 0x0000, 0x0000, 0x0000, 0x0000, 0x0000, 0x0000, 0x0000, 0x0000, 0x0000, 0x0000, 0x0000, 0x0000, 0x0000, 0x0000, 0x0000, 0x0000, 0x0000, 0x0000, 0x0000, 0x0000, 0x0000, 0x0000, 0x0000, 0x0000, 0x0000, 0x0000, 0x0000, 0x0000, 0x0000, 0x0000, 0x0000, 0x0000, 0x0000, 0x0000, 0x0000, 0x0000, 0x0000, 0x0000, 0x0000, 0x0000, 0x0000, 0x0000, 0x0000, 0x0000, 0x0000, 0x0000, 0x0000, 0x0000, 0x0000, 0x0000, 0x0000, 0x0000, 0x0000, 0x0000, 0x0000, 0x0000, 0x0000, 0x0000,
  0x0000, 0x0000, 0x0000, 0x0000, 0x0000, 0x0000, 0x0000, 0x0000, 0x0000, 0x0000, 0x0000, 0x0000, 0x0000, 0x0000, 0x0000, 0x0000, 0x0000, 0x0000, 0x0000, 0x0000, 0x0000, 0x0000, 0x0000, 0x0000, 0x0000, 0x0000, 0x0000, 0x0000, 0x0000, 0x0000, 0x0000, 0x0000, 0x0000, 0x0000, 0x0000, 0x0000, 0x0000, 0x0000, 0x0000, 0x0000, 0x0000, 0x0000, 0x0000, 0x0000, 0x0000, 0x0000, 0x0000, 0x0000, 0x0000, 0x0000, 0x0000, 0x0000, 0x0000, 0x0000, 0x0000, 0x0000, 0x0000, 0x0000, 0x0000, 0x0000, 0x0000, 0x0000, 0x0000, 0x0000, 0x0000, 0x0000, 0x0000, 0x0000, 0x0000, 0x0000, 0x0000, 0x0000, 0x0000, 0x0000, 0x0000, 0x0000, 0x0000, 0x0000, 0x0000, 0x0000,
  0x0000, 0x0000, 0x0000, 0x0000, 0x0000, 0x0000, 0x0000, 0x0000, 0x0000, 0x0000, 0x0000, 0x0000, 0x0000, 0x0000, 0x0000, 0x0000, 0x0000, 0x0000, 0x0000, 0x0000, 0x0000, 0x0000, 0x0000, 0x0000, 0x0000, 0x0000, 0x0000, 0x0000, 0x0000, 0x0000, 0x0000, 0x0000, 0x0000, 0x0000, 0x0000, 0x0000, 0x0000, 0x0000, 0x0000, 0x0000, 0x0000, 0x0000, 0x0000, 0x0000, 0x0000, 0x0000, 0x0000, 0x0000, 0x0000, 0x0000, 0x0000, 0x0000, 0x0000, 0x0000, 0x0000, 0x0000, 0x0000, 0x0000, 0x0000, 0x0000, 0x0000, 0x0000, 0x0000, 0x0000, 0x0000, 0x0000, 0x0000, 0x0000, 0x0000, 0x0000, 0x0000, 0x0000, 0x0000, 0x0000, 0x0000, 0x0000, 0x0000, 0x0000, 0x0000, 0x0000
};

static const uint16_t ImagemVitoria1[][60*80/2]  = {
  0x0000, 0x0000, 0x0000, 0x0000, 0x0000, 0x0000, 0x0000, 0x0000, 0x0000, 0x0000, 0x0000, 0x0000, 0x0000, 0x0000, 0x0000, 0x0000, 0x0000, 0x0000, 0x0000, 0x0000, 0x0000, 0x0000, 0x0000, 0x0000, 0x0000, 0x0000, 0x0000, 0x0000, 0x0000, 0x0000, 0x0000, 0x0000, 0x0000, 0x0000, 0x0000, 0x0000, 0x0000, 0x0000, 0x0000, 0x0000, 0x0000, 0x0000, 0x0000, 0x0000, 0x0000, 0x0000, 0x0000, 0x0000, 0x0000, 0x0000, 0x0000, 0x0000, 0x0000, 0x0000, 0x0000, 0x0000, 0x0000, 0x0000, 0x0000, 0x0000, 0x0000, 0x0000, 0x0000, 0x0000, 0x0000, 0x0000, 0x0000, 0x0000, 0x0000, 0x0000, 0x0000, 0x0000, 0x0000, 0x0000, 0x0000, 0x0000, 0x0000, 0x0000, 0x0000, 0x0000,
  0x0000, 0x0000, 0x0000, 0x0000, 0x0000, 0x0000, 0x0000, 0x0000, 0x0000, 0x0000, 0x0000, 0x0000, 0x0000, 0x0000, 0x0000, 0x0000, 0x0000, 0x0000, 0x0000, 0x0000, 0x0000, 0x0000, 0x0000, 0x0000, 0x0000, 0x0000, 0x0000, 0x0000, 0x0000, 0x0000, 0x0000, 0x0000, 0x0000, 0x0000, 0x0000, 0x0000, 0x0000, 0x0000, 0x0000, 0x0000, 0x0000, 0x0000, 0x0000, 0x0000, 0x0000, 0x0000, 0x0000, 0x0000, 0x0000, 0x0000, 0x0000, 0x0000, 0x0000, 0x0000, 0x0000, 0x0000, 0x0000, 0x0000, 0x0000, 0x0000, 0x0000, 0x0000, 0x0000, 0x0000, 0x0000, 0x0000, 0x0000, 0x0000, 0x0000, 0x0000, 0x0000, 0x0000, 0x0000, 0x0000, 0x0000, 0x0000, 0x0000, 0x0000, 0x0000, 0x0000,
  0x0000, 0x0000, 0x0000, 0x0000, 0x0000, 0x0000, 0x0000, 0x0000, 0x0000, 0x0000, 0x0000, 0x0000, 0x0000, 0x0000, 0x0000, 0x0000, 0x0000, 0x0000, 0x0000, 0x0000, 0x0000, 0x0000, 0x0000, 0x0000, 0x0000, 0x0000, 0x0000, 0x0000, 0x0000, 0x0000, 0x0000, 0x0000, 0x0000, 0x0000, 0x0000, 0x0000, 0x0000, 0x0000, 0x0000, 0x0000, 0x0000, 0x0000, 0x0000, 0x0000, 0x0000, 0x0000, 0x0000, 0x0000, 0x0000, 0x0000, 0x0000, 0x0000, 0x0000, 0x0000, 0x0000, 0x0000, 0x0000, 0x0000, 0x0000, 0x0000, 0x0000, 0x0000, 0x0000, 0x0000, 0x0000, 0x0000, 0x0000, 0x0000, 0x0000, 0x0000, 0x0000, 0x0000, 0x0000, 0x0000, 0x0000, 0x0000, 0x0000, 0x0000, 0x0000, 0x0000,
  0x0000, 0x0000, 0x0000, 0x0000, 0x0000, 0x0000, 0x0000, 0x0000, 0x0000, 0x0000, 0x0000, 0x0000, 0x0000, 0x0000, 0x0000, 0x0000, 0x0000, 0x0000, 0x0000, 0x0000, 0x0000, 0x0000, 0x0000, 0x0000, 0x0000, 0x0000, 0x0000, 0x0000, 0x0000, 0x0000, 0x0000, 0x0000, 0x0000, 0x0000, 0x0000, 0x0000, 0x0000, 0x0000, 0x0000, 0x0000, 0x0000, 0x0000, 0x0000, 0x0000, 0x0000, 0x0000, 0x0000, 0x0000, 0x0000, 0x0000, 0x0000, 0x0000, 0x0000, 0x0000, 0x0000, 0x0000, 0x0000, 0x0000, 0x0000, 0x0000, 0x0000, 0x0000, 0x0000, 0x0000, 0x0000, 0x0000, 0x0000, 0x0000, 0x0000, 0x0000, 0x0000, 0x0000, 0x0000, 0x0000, 0x0000, 0x0000, 0x0000, 0x0000, 0x0000, 0x0000,
  0x0000, 0x0000, 0x0000, 0x0000, 0x0000, 0x0000, 0x0000, 0x0000, 0x0000, 0x0000, 0x0000, 0x0000, 0x0000, 0x0000, 0x0000, 0x0000, 0x0000, 0x0000, 0x0000, 0x0000, 0x0000, 0x0000, 0x0000, 0x0000, 0x0000, 0x0000, 0x0000, 0x0000, 0x0000, 0x0000, 0x0000, 0x0000, 0x0000, 0x0000, 0x0000, 0x0000, 0x0000, 0x0000, 0x0000, 0x0000, 0x0000, 0x0000, 0x0000, 0x0000, 0x0000, 0x0000, 0x0000, 0x0000, 0x0000, 0x0000, 0x0000, 0x0000, 0x0000, 0x0000, 0x0000, 0x0000, 0x0000, 0x0000, 0x0000, 0x0000, 0x0000, 0x0000, 0x0000, 0x0000, 0x0000, 0x0000, 0x0000, 0x0000, 0x0000, 0x0000, 0x0000, 0x0000, 0x0000, 0x0000, 0x0000, 0x0000, 0x0000, 0x0000, 0x0000, 0x0000,
  0x0000, 0x0000, 0x0000, 0x0000, 0x0000, 0x0000, 0x0000, 0x0000, 0x0000, 0x0000, 0x0000, 0x0000, 0x0000, 0x0000, 0x0000, 0x0000, 0x0000, 0x0000, 0x0000, 0x0000, 0x0000, 0x0000, 0x0000, 0x0000, 0x0000, 0x0000, 0x0000, 0x0000, 0x0000, 0x0000, 0x0000, 0x0000, 0x0000, 0x0000, 0x0000, 0x0000, 0x0000, 0x0000, 0x0000, 0x0000, 0x0000, 0x0000, 0x0000, 0x0000, 0x0000, 0x0000, 0x0000, 0x0000, 0x0000, 0x0000, 0x0000, 0x0000, 0x0000, 0x0000, 0x0000, 0x0000, 0x0000, 0x0000, 0x0000, 0x0000, 0x0000, 0x0000, 0x0000, 0x0000, 0x0000, 0x0000, 0x0000, 0x0000, 0x0000, 0x0000, 0x0000, 0x0000, 0x0000, 0x0000, 0x0000, 0x0000, 0x0000, 0x0000, 0x0000, 0x0000,
  0x0000, 0x0000, 0x0000, 0x0000, 0x0000, 0x0000, 0x0000, 0x0000, 0x0000, 0x0000, 0x0000, 0x0000, 0x0000, 0x0000, 0x0000, 0x0000, 0x0000, 0x0000, 0x0000, 0x0000, 0x0000, 0x0000, 0x0000, 0x0000, 0x0000, 0x0000, 0x0000, 0x0000, 0x0000, 0x0000, 0x0000, 0x0000, 0x0000, 0x0000, 0x0000, 0x0000, 0x0000, 0x0000, 0x0000, 0x0000, 0x0000, 0x0000, 0x0000, 0x0000, 0x0000, 0x0000, 0x0000, 0x0000, 0x0000, 0x0000, 0x0000, 0x0000, 0x0000, 0x0000, 0x0000, 0x0000, 0x0000, 0x0000, 0x0000, 0x0000, 0x0000, 0x0000, 0x0000, 0x0000, 0x0000, 0x0000, 0x0000, 0x0000, 0x0000, 0x0000, 0x0000, 0x0000, 0x0000, 0x0000, 0x0000, 0x0000, 0x0000, 0x0000, 0x0000, 0x0000,
  0x0000, 0x0000, 0x0000, 0x0000, 0x0000, 0x0000, 0x0000, 0x0000, 0x0000, 0x0000, 0x0000, 0x0000, 0x0000, 0x0000, 0x0000, 0x0000, 0x0000, 0x0000, 0x0000, 0x0000, 0x0000, 0x0000, 0x0000, 0x0000, 0x0000, 0x0000, 0x0000, 0x0000, 0x0000, 0x0000, 0x0000, 0x0000, 0x0000, 0x0000, 0x0000, 0x0000, 0x0000, 0x0000, 0x0000, 0x0000, 0x0000, 0x0000, 0x0000, 0x0000, 0x0000, 0x0000, 0x0000, 0x0000, 0x0000, 0x0000, 0x0000, 0x0000, 0x0000, 0x0000, 0x0000, 0x0000, 0x0000, 0x0000, 0x0000, 0x0000, 0x0000, 0x0000, 0x0000, 0x0000, 0x0000, 0x0000, 0x0000, 0x0000, 0x0000, 0x0000, 0x0000, 0x0000, 0x0000, 0x0000, 0x0000, 0x0000, 0x0000, 0x0000, 0x0000, 0x0000,
  0x0000, 0x0000, 0x0000, 0x0000, 0x0000, 0x0000, 0x0000, 0x0000, 0x0000, 0x0000, 0x0000, 0x0000, 0x0000, 0x0000, 0x0000, 0x0000, 0x0000, 0x0000, 0x0000, 0x0000, 0x0000, 0x0000, 0x0000, 0x0000, 0x0000, 0x0000, 0x0000, 0x0000, 0x0000, 0x0000, 0x0000, 0x0000, 0x0000, 0x0000, 0x0000, 0x0000, 0x0000, 0x0000, 0x0000, 0x0000, 0x0000, 0x0000, 0x0000, 0x0000, 0x0000, 0x0000, 0x0000, 0x0000, 0x0000, 0x0000, 0x0000, 0x0000, 0x0000, 0x0000, 0x0000, 0x0000, 0x0000, 0x0000, 0x0000, 0x0000, 0x0000, 0x0000, 0x0000, 0x0000, 0x0000, 0x0000, 0x0000, 0x0000, 0x0000, 0x0000, 0x0000, 0x0000, 0x0000, 0x0000, 0x0000, 0x0000, 0x0000, 0x0000, 0x0000, 0x0000,
  0x0000, 0x0000, 0x0000, 0x0000, 0x0000, 0x0000, 0x0000, 0x0000, 0x0000, 0x0000, 0x0000, 0x0000, 0x0000, 0x0000, 0x0000, 0x0000, 0x0000, 0x0000, 0x0000, 0x0000, 0x0000, 0x0000, 0x0000, 0x0000, 0x0000, 0x0000, 0x0000, 0x0000, 0x0000, 0x0000, 0x0000, 0x0000, 0x0000, 0x0000, 0x0000, 0x0000, 0x0000, 0x0000, 0x0000, 0x0000, 0x0000, 0x0000, 0x0000, 0x0000, 0x0000, 0x0000, 0x0000, 0x0000, 0x0000, 0x0000, 0x0000, 0x0000, 0x0000, 0x0000, 0x0000, 0x0000, 0x0000, 0x0000, 0x0000, 0x0000, 0x0000, 0x0000, 0x0000, 0x0000, 0x0000, 0x0000, 0x0000, 0x0000, 0x0000, 0x0000, 0x0000, 0x0000, 0x0000, 0x0000, 0x0000, 0x0000, 0x0000, 0x0000, 0x0000, 0x0000,
  0x0000, 0x0000, 0x0000, 0x0000, 0x0000, 0x0000, 0x0000, 0x0000, 0x0000, 0x0000, 0x0000, 0x0000, 0x0000, 0x0000, 0x0000, 0x0000, 0x0000, 0x0000, 0x0000, 0x0000, 0x0000, 0x0000, 0x0000, 0x0000, 0x0000, 0x0000, 0x0000, 0x0000, 0x0000, 0x0000, 0x0000, 0x0000, 0x0000, 0x0000, 0x0000, 0x0000, 0x0000, 0x0000, 0x0000, 0x0000, 0x0000, 0x0000, 0x0000, 0x0000, 0x0000, 0x0000, 0x0000, 0x0000, 0x0000, 0x0000, 0x0000, 0x0000, 0x0000, 0x0000, 0x0000, 0x0000, 0x0000, 0x0000, 0x0000, 0x0000, 0x0000, 0x0000, 0x0000, 0x0000, 0x0000, 0x0000, 0x0000, 0x0000, 0x0000, 0x0000, 0x0000, 0x0000, 0x0000, 0x0000, 0x0000, 0x0000, 0x0000, 0x0000, 0x0000, 0x0000,
  0x0000, 0x0000, 0x0000, 0x0000, 0x0000, 0x0000, 0x0000, 0x0000, 0x0000, 0x0000, 0x0000, 0x0000, 0x0000, 0x0000, 0x0000, 0x0000, 0x0000, 0x0000, 0x0000, 0x0000, 0x0000, 0x0000, 0x0000, 0x0000, 0x0000, 0x0000, 0x0000, 0x0000, 0x0000, 0x0000, 0x0000, 0x0000, 0x0000, 0x0000, 0x0000, 0x0000, 0x0000, 0x0000, 0x0000, 0x0000, 0x0000, 0x0000, 0x0000, 0x0000, 0x0000, 0x0000, 0x0000, 0x0000, 0x0000, 0x0000, 0x0000, 0x0000, 0x0000, 0x0000, 0x0000, 0x0000, 0x0000, 0x0000, 0x0000, 0x0000, 0x0000, 0x0000, 0x0000, 0x0000, 0x0000, 0x0000, 0x0000, 0x0000, 0x0000, 0x0000, 0x0000, 0x0000, 0x0000, 0x0000, 0x0000, 0x0000, 0x0000, 0x0000, 0x0000, 0x0000,
  0x0000, 0x0000, 0x0000, 0x0000, 0x0000, 0x0000, 0x0000, 0x0000, 0x0000, 0x0000, 0x0000, 0x0000, 0x0000, 0x0000, 0x0000, 0x0000, 0x0000, 0x0000, 0x0000, 0x0000, 0x0000, 0x0000, 0x0000, 0x0000, 0x0000, 0x0000, 0x0000, 0x0000, 0x0000, 0x0000, 0x0000, 0x0000, 0x0000, 0x0000, 0x0000, 0x0000, 0x0000, 0x0000, 0x0000, 0x0000, 0x0000, 0x0000, 0x0000, 0x0000, 0x0000, 0x0000, 0x0000, 0x0000, 0x0000, 0x0000, 0x0000, 0x0000, 0x0000, 0x0000, 0x0000, 0x0000, 0x0000, 0x0000, 0x0000, 0x0000, 0x0000, 0x0000, 0x0000, 0x0000, 0x0000, 0x0000, 0x0000, 0x0000, 0x0000, 0x0000, 0x0000, 0x0000, 0x0000, 0x0000, 0x0000, 0x0000, 0x0000, 0x0000, 0x0000, 0x0000,
  0x0000, 0x0000, 0x0000, 0x0000, 0x0000, 0x0000, 0x0000, 0x0000, 0x0000, 0x0000, 0x0000, 0x0000, 0x0000, 0x0000, 0x0000, 0x0000, 0x0000, 0x0000, 0x0000, 0x0000, 0x0000, 0x0000, 0x0000, 0x0000, 0x0000, 0x0000, 0x0000, 0x0000, 0x0000, 0x0000, 0x0000, 0x0000, 0x0000, 0x0000, 0x0000, 0x0000, 0x0000, 0x0000, 0x0000, 0x0000, 0x0000, 0x0000, 0x0000, 0x0000, 0x0000, 0x0000, 0x0000, 0x0000, 0x0000, 0x0000, 0x0000, 0x0000, 0x0000, 0x0000, 0x0000, 0x0000, 0x0000, 0x0000, 0x0000, 0x0000, 0x0000, 0x0000, 0x0000, 0x0000, 0x0000, 0x0000, 0x0000, 0x0000, 0x0000, 0x0000, 0x0000, 0x0000, 0x0000, 0x0000, 0x0000, 0x0000, 0x0000, 0x0000, 0x0000, 0x0000,
  0x0000, 0x0000, 0x0000, 0x0000, 0x0000, 0x0000, 0x0000, 0x0000, 0x0000, 0x0000, 0x0000, 0x0000, 0x0000, 0x0000, 0x0000, 0x0000, 0x0000, 0x0000, 0x0000, 0x0000, 0x0000, 0x0000, 0x0000, 0x0000, 0x0000, 0x0000, 0x0000, 0x0000, 0x0000, 0x0000, 0x0000, 0x0000, 0x0000, 0x0000, 0x0000, 0x0000, 0x0000, 0x0000, 0x0000, 0x0000, 0x0000, 0x0000, 0x0000, 0x0000, 0x0000, 0x0000, 0x0000, 0x0000, 0x0000, 0x0000, 0x0000, 0x0000, 0x0000, 0x0000, 0x0000, 0x0000, 0x0000, 0x0000, 0x0000, 0x0000, 0x0000, 0x0000, 0x0000, 0x0000, 0x0000, 0x0000, 0x0000, 0x0000, 0x0000, 0x0000, 0x0000, 0x0000, 0x0000, 0x0000, 0x0000, 0x0000, 0x0000, 0x0000, 0x0000, 0x0000,
  0x0000, 0x0000, 0x0000, 0x0000, 0x0000, 0x0000, 0x0000, 0x0000, 0x0000, 0x0000, 0x0000, 0x0000, 0x0000, 0x0000, 0x0000, 0x0000, 0x0000, 0x0000, 0x0000, 0x0000, 0x0000, 0x0000, 0x0000, 0x0000, 0x0000, 0x0000, 0x0000, 0x0000, 0x0000, 0x0000, 0x0000, 0x0000, 0x0000, 0x0000, 0x0000, 0x0000, 0x0000, 0x0000, 0x0000, 0x0000, 0x0000, 0x0000, 0x0000, 0x0000, 0x0000, 0x0000, 0x0000, 0x0000, 0x0000, 0x0000, 0x0000, 0x0000, 0x0000, 0x0000, 0x0000, 0x0000, 0x0000, 0x0000, 0x0000, 0x0000, 0x0000, 0x0000, 0x0000, 0x0000, 0x0000, 0x0000, 0x0000, 0x0000, 0x0000, 0x0000, 0x0000, 0x0000, 0x0000, 0x0000, 0x0000, 0x0000, 0x0000, 0x0000, 0x0000, 0x0000,
  0x0000, 0x0000, 0x0000, 0x0000, 0x0000, 0x0000, 0x0000, 0x0000, 0x0000, 0x0000, 0x0000, 0x0000, 0x0000, 0x0000, 0x0000, 0x0000, 0x0000, 0x0000, 0x0000, 0x0000, 0x0000, 0x0000, 0x0000, 0x0000, 0x0000, 0x0000, 0x0000, 0x0000, 0x0000, 0x0000, 0x0000, 0x0000, 0x0000, 0x0000, 0x0000, 0x0000, 0x0000, 0x0000, 0x0000, 0x0000, 0x0000, 0x0000, 0x0000, 0x0000, 0x0000, 0x0000, 0x0000, 0x0000, 0x0000, 0x0000, 0x0000, 0x0000, 0x0000, 0x0000, 0x0000, 0x0000, 0x0000, 0x0000, 0x0000, 0x0000, 0x0000, 0x0000, 0x0000, 0x0000, 0x0000, 0x0000, 0x0000, 0x0000, 0x0000, 0x0000, 0x0000, 0x0000, 0x0000, 0x0000, 0x0000, 0x0000, 0x0000, 0x0000, 0x0000, 0x0000,
  0x0000, 0x0000, 0x0000, 0x0000, 0x0000, 0x0000, 0x0000, 0x0000, 0x0000, 0x0000, 0x0000, 0x0000, 0x0000, 0x0000, 0x0000, 0x0000, 0x0000, 0x0000, 0x0000, 0x0000, 0x0000, 0x0000, 0x0000, 0x0000, 0x0000, 0x0000, 0x0000, 0x0000, 0x0000, 0x0000, 0x0000, 0x0000, 0x0000, 0x0000, 0x0000, 0x0000, 0x0000, 0x0000, 0x0000, 0x0000, 0x0000, 0x0000, 0x0000, 0x0000, 0x0000, 0x0000, 0x0000, 0x0000, 0x0000, 0x0000, 0x0000, 0x0000, 0x0000, 0x0000, 0x0000, 0x0000, 0x0000, 0x0000, 0x0000, 0x0000, 0x0000, 0x0000, 0x0000, 0x0000, 0x0000, 0x0000, 0x0000, 0x0000, 0x0000, 0x0000, 0x0000, 0x0000, 0x0000, 0x0000, 0x0000, 0x0000, 0x0000, 0x0000, 0x0000, 0x0000,
  0x0000, 0x0000, 0x0000, 0x0000, 0x0000, 0x0000, 0x0000, 0x0000, 0x0000, 0x0000, 0x0000, 0x0000, 0x0000, 0x0000, 0x0000, 0x0000, 0x0000, 0x0000, 0x0000, 0x0000, 0x0000, 0x0000, 0x0000, 0x0000, 0x0000, 0x0000, 0x0000, 0x0000, 0x0000, 0x0000, 0x0000, 0x0000, 0x0000, 0x0000, 0x0000, 0x0000, 0x0000, 0x0000, 0x0000, 0x0000, 0x0000, 0x0000, 0x0000, 0x0000, 0x0000, 0x0000, 0x0000, 0x0000, 0x0000, 0x0000, 0x0000, 0x0000, 0x0000, 0x0000, 0x0000, 0x0000, 0x0000, 0x0000, 0x0000, 0x0000, 0x0000, 0x0000, 0x0000, 0x0000, 0x0000, 0x0000, 0x0000, 0x0000, 0x0000, 0x0000, 0x0000, 0x0000, 0x0000, 0x0000, 0x0000, 0x0000, 0x0000, 0x0000, 0x0000, 0x0000,
  0x0000, 0x0000, 0x0000, 0x0000, 0x0000, 0x0000, 0x0000, 0x0000, 0x0000, 0x0000, 0x0000, 0x0000, 0x0000, 0x0000, 0x0000, 0x0000, 0x0000, 0x0000, 0x0208, 0x0628, 0x0000, 0x0000, 0x0000, 0x0000, 0x0000, 0x0030, 0x0010, 0x0000, 0x0000, 0x0000, 0x0000, 0x0000, 0x0000, 0x0000, 0x0000, 0x0000, 0x0000, 0x0000, 0x8200, 0x4601, 0x2000, 0x0000, 0x0000, 0x0000, 0x0000, 0x0030, 0x0010, 0x0000, 0x0000, 0x0000, 0x0000, 0x0000, 0x0000, 0x0000, 0x0000, 0x0030, 0x0010, 0x0000, 0x4100, 0xa400, 0x0000, 0x0000, 0x0000, 0x0000, 0x0000, 0x0000, 0x0000, 0x0000, 0x0000, 0x0000, 0x0000, 0x0000, 0x0000, 0x0000, 0x0000, 0x0000, 0x0000, 0x0000, 0x0000, 0x0000,
  0x0000, 0x0000, 0x0000, 0x0000, 0x0000, 0x0000, 0x0000, 0x0000, 0x0000, 0x0000, 0x0000, 0x0000, 0x0000, 0x0000, 0x0000, 0x0000, 0x0000, 0x0000, 0x0420, 0x3690, 0x1598, 0x0000, 0x2e02, 0x4e02, 0x00a8, 0x20b0, 0x20a8, 0x0000, 0x614d, 0x6145, 0xc04c, 0x0000, 0x20a8, 0x41b0, 0x0000, 0x0000, 0x4e02, 0x2e02, 0x9504, 0x9604, 0x7504, 0x0000, 0x6145, 0x6145, 0x00a8, 0x20b0, 0x20a8, 0x0000, 0x950c, 0x9604, 0x1604, 0x0000, 0x0000, 0x4e02, 0xec21, 0x41a0, 0x20a8, 0x0000, 0x1103, 0x3103, 0x1103, 0x0000, 0x9504, 0x960c, 0x0000, 0x0000, 0x0000, 0x0000, 0x0000, 0x0000, 0x0000, 0x0000, 0x0000, 0x0000, 0x0000, 0x0000, 0x0000, 0x0000, 0x0000, 0x0000,
  0x0000, 0x0000, 0x0000, 0x0000, 0x0000, 0x0000, 0x0000, 0x0000, 0x0000, 0x0000, 0x0000, 0x0000, 0x0000, 0x0000, 0x0000, 0x0000, 0x0000, 0x0000, 0x0000, 0x0000, 0x0000, 0x0000, 0x4e02, 0x4e02, 0x5704, 0x9604, 0x960c, 0x0000, 0x6145, 0x6145, 0x4245, 0x0000, 0x20b0, 0x20b0, 0x0000, 0x0000, 0x4e02, 0x4e02, 0x960c, 0x9604, 0x5704, 0x0000, 0x6145, 0x6145, 0x0000, 0x0000, 0x0000, 0x4f02, 0x1103, 0x9604, 0x5504, 0x0000, 0x0000, 0x2e02, 0x4e02, 0x2e02, 0x0000, 0x0000, 0xb604, 0x9604, 0x5504, 0x0000, 0x9604, 0xd014, 0x4134, 0x4000, 0x0000, 0x0000, 0x0000, 0x0000, 0x0000, 0x0000, 0x0000, 0x0000, 0x0000, 0x0000, 0x0000, 0x0000, 0x0000, 0x0000,
  0x0000, 0x0000, 0x0000, 0x0000, 0x0000, 0x0000, 0x0000, 0x0000, 0x0000, 0x0000, 0x0000, 0x0000, 0x0000, 0x0000, 0x0000, 0x0000, 0x0000, 0x0000, 0x0000, 0x824d, 0x4145, 0x614d, 0x20a8, 0x20b0, 0x5604, 0x9504, 0xb504, 0x0000, 0x0000, 0x0000, 0x0000, 0x0000, 0x20a8, 0x20b0, 0x0000, 0x0000, 0x0000, 0x4145, 0x0735, 0x9504, 0x5604, 0x4e02, 0x4e02, 0x0000, 0x0000, 0x0000, 0x0000, 0x4e02, 0x4e02, 0x1698, 0x3590, 0x3598, 0x0000, 0xb504, 0x9504, 0x5604, 0x0000, 0x0000, 0x4f02, 0x4e02, 0x6e02, 0x20b0, 0x20a8, 0x614d, 0x613c, 0x4000, 0x0000, 0x0000, 0x0000, 0x0000, 0x0000, 0x0000, 0x0000, 0x0000, 0x0000, 0x0000, 0x0000, 0x0000, 0x0000, 0x0000,
  0x0000, 0x0000, 0x0000, 0x0000, 0x0000, 0x0000, 0x0000, 0x0000, 0x0000, 0x0000, 0x0000, 0x0000, 0x0000, 0x0000, 0x0000, 0x0000, 0x0000, 0x0000, 0x0000, 0xc245, 0x6145, 0x4145, 0x20b0, 0x20b0, 0x2e02, 0x4e02, 0x2e02, 0x9604, 0x9604, 0x0000, 0x0000, 0x0000, 0x20b0, 0x20b0, 0x0000, 0x0000, 0x0000, 0x6145, 0x6145, 0x0000, 0x0000, 0x4e02, 0x4f02, 0x0000, 0x0000, 0x0000, 0x20b0, 0x20b0, 0x0000, 0x17a0, 0x3690, 0x26a8, 0x20b0, 0x960c, 0x9604, 0x5704, 0x0000, 0x0000, 0x6e0a, 0x4e02, 0x2e02, 0x20b0, 0x20b0, 0x0000, 0x0000, 0x0000, 0x0000, 0x0000, 0x0000, 0x0000, 0x0000, 0x0000, 0x0000, 0x0000, 0x0000, 0x0000, 0x0000, 0x0000, 0x0000, 0x0000,
  0x0000, 0x0000, 0x0000, 0x0000, 0x0000, 0x0000, 0x0000, 0x0000, 0x0000, 0x0000, 0x0000, 0x0000, 0x0000, 0x0000, 0x0000, 0x0000, 0x0000, 0x0000, 0x0000, 0x0000, 0x0000, 0x0000, 0x0000, 0x0000, 0x6c02, 0x4e02, 0x4e02, 0x9504, 0x6d44, 0x619c, 0x619c, 0x619c, 0x0000, 0x619c, 0x619c, 0x619c, 0x619c, 0x0000, 0x619c, 0x619c, 0x619c, 0x619c, 0x619c, 0x619c, 0x619c, 0x629c, 0x41b0, 0x20a8, 0x619c, 0x619c, 0x619c, 0xe0a9, 0x20a8, 0x0000, 0x629c, 0x619c, 0x619c, 0x619c, 0x9504, 0x9604, 0x7504, 0x4e02, 0x4e02, 0x0000, 0x0000, 0x0000, 0x0000, 0x0000, 0x0000, 0x0000, 0x0000, 0x0000, 0x0000, 0x0000, 0x0000, 0x0000, 0x0000, 0x0000, 0x0000, 0x0000,
  0x0000, 0x0000, 0x0000, 0x0000, 0x0000, 0x0000, 0x0000, 0x0000, 0x0000, 0x0000, 0x0000, 0x0000, 0x0000, 0x0000, 0x0000, 0x0000, 0x0000, 0x0000, 0x0000, 0x1598, 0x3690, 0x3590, 0x0000, 0x0000, 0x0000, 0x0000, 0x0000, 0x00ce, 0xc0cd, 0x60bd, 0x81a4, 0x419c, 0x00ce, 0xc0cd, 0x60bd, 0x81a4, 0x419c, 0x00ce, 0xc0cd, 0x80bd, 0x80bd, 0x80bd, 0x80bd, 0x20b5, 0x619c, 0x619c, 0x619c, 0x00ce, 0xc0cd, 0x60bd, 0x81a4, 0x419c, 0x0000, 0xe0cd, 0xe0cd, 0x80c5, 0xc1a4, 0x419c, 0x960c, 0x9604, 0x1304, 0x2e02, 0x4f02, 0x0000, 0x0000, 0x0000, 0x0000, 0x0000, 0x0000, 0x0000, 0x0000, 0x0000, 0x0000, 0x0000, 0x0000, 0x0000, 0x0000, 0x0000, 0x0000, 0x0000,
  0x0000, 0x0000, 0x0000, 0x0000, 0x0000, 0x0000, 0x0000, 0x0000, 0x0000, 0x0000, 0x0000, 0x0000, 0x0000, 0x0000, 0x0000, 0x0000, 0x0000, 0x0000, 0x0000, 0x15a8, 0x3590, 0x1598, 0x0000, 0x0000, 0x0000, 0x0000, 0x0000, 0xe0cd, 0x00ce, 0xc0cd, 0x81a4, 0x419c, 0xe0cd, 0x00ce, 0xc0cd, 0x81a4, 0x60bd, 0x00ce, 0xa0c5, 0xc1ac, 0x80bd, 0xe0cd, 0x00ce, 0xe0cd, 0x80bd, 0x81a4, 0x8e3c, 0x6975, 0x00ce, 0xc0cd, 0x81a4, 0x419c, 0x0000, 0x00ce, 0x00ce, 0x00ce, 0xe1ac, 0x419c, 0x6145, 0x6145, 0x2145, 0x0000, 0x0000, 0x20b0, 0x2098, 0x0008, 0x0000, 0x0000, 0x0000, 0x0000, 0x0000, 0x0000, 0x0000, 0x0000, 0x0000, 0x0000, 0x0000, 0x0000, 0x0000, 0x0000,
  0x0000, 0x0000, 0x0000, 0x0000, 0x0000, 0x0000, 0x0000, 0x0000, 0x0000, 0x0000, 0x0000, 0x0000, 0x0000, 0x0000, 0x0000, 0x0000, 0x0000, 0x0000, 0x0000, 0x0000, 0x0000, 0x0000, 0x6145, 0x6145, 0x7590, 0x3690, 0x5590, 0xe0cd, 0x00ce, 0xc0cd, 0x81a4, 0x619c, 0x40b5, 0x00ce, 0x00ce, 0x01b5, 0xe0cd, 0x00ce, 0x80bd, 0x619c, 0x419c, 0x0000, 0xe0cd, 0x00ce, 0xc0cd, 0x81a4, 0x6674, 0xc3b5, 0x00ce, 0xc0cd, 0x81a4, 0x419c, 0x0000, 0x00ce, 0x00ce, 0x00ce, 0xe1ac, 0x419c, 0x824d, 0x614d, 0xe045, 0x3690, 0x3690, 0x00b0, 0x2068, 0x0000, 0x0000, 0x0000, 0x0000, 0x0000, 0x0000, 0x0000, 0x0000, 0x0000, 0x0000, 0x0000, 0x0000, 0x0000, 0x0000, 0x0000,
  0x0000, 0x0000, 0x0000, 0x0000, 0x0000, 0x0000, 0x0000, 0x0000, 0x0000, 0x0000, 0x0000, 0x0000, 0x0000, 0x0000, 0x0000, 0x0000, 0x0000, 0x0000, 0x0000, 0x6f02, 0x4e02, 0x4e02, 0x824d, 0x4145, 0x15a8, 0x5698, 0x1398, 0x20c6, 0xe0cd, 0xe0cd, 0xc0cd, 0xc0cd, 0xe0cd, 0x00ce, 0x40d6, 0x40ad, 0x00ce, 0x00ce, 0x80bd, 0x619c, 0x419c, 0x0000, 0xe0cd, 0x00ce, 0xc0cd, 0x81a4, 0x419c, 0xe0cd, 0x00ce, 0xc0cd, 0x81a4, 0x419c, 0x0000, 0x00ce, 0x00ce, 0x00ce, 0xe1ac, 0x419c, 0x0000, 0x0000, 0x0000, 0x1598, 0x1698, 0x3698, 0x3380, 0x0208, 0x0000, 0x0000, 0x0000, 0x0000, 0x0000, 0x0000, 0x0000, 0x0000, 0x0000, 0x0000, 0x0000, 0x0000, 0x0000, 0x0000,
  0x0000, 0x0000, 0x0000, 0x0000, 0x0000, 0x0000, 0x0000, 0x0000, 0x0000, 0x0000, 0x0000, 0x0000, 0x0000, 0x0000, 0x0000, 0x0000, 0x0000, 0x0000, 0x0000, 0x0000, 0x1002, 0xaa02, 0x0000, 0x9604, 0x9604, 0x750c, 0x6145, 0x6145, 0x40ad, 0x01ce, 0x00ce, 0x00ce, 0x20b5, 0x619c, 0x41a8, 0x20b0, 0x40c4, 0x00ce, 0x80bd, 0x619c, 0x419c, 0x0000, 0xe0cd, 0x00ce, 0xc0cd, 0x81a4, 0x419c, 0xe0cd, 0x00ce, 0xc0cd, 0x81a4, 0x419c, 0x0000, 0x00ce, 0x00ce, 0x00ce, 0xe1ac, 0x419c, 0x6145, 0x6145, 0x6145, 0x4e02, 0x4e02, 0x15a8, 0x0520, 0x0000, 0x0000, 0x0000, 0x0000, 0x0000, 0x0000, 0x0000, 0x0000, 0x0000, 0x0000, 0x0000, 0x0000, 0x0000, 0x0000, 0x0000,
  0x0000, 0x0000, 0x0000, 0x0000, 0x0000, 0x0000, 0x0000, 0x0000, 0x0000, 0x0000, 0x0000, 0x0000, 0x0000, 0x0000, 0x0000, 0x0000, 0x0000, 0x0000, 0x4601, 0x9604, 0x750c, 0x0000, 0xe045, 0x4055, 0x0000, 0x0000, 0xb002, 0x1002, 0x0000, 0xc1cd, 0x00ce, 0x00ce, 0x20b5, 0x619c, 0x0000, 0x0000, 0x00ce, 0x00ce, 0x80c5, 0x619c, 0x619c, 0x619c, 0x20b5, 0x00ce, 0x00ce, 0x039d, 0xaa02, 0x00ce, 0x00ce, 0xc0cd, 0xa1a4, 0x619c, 0x619c, 0xe1ac, 0x00ce, 0x00ce, 0x00ce, 0x00b8, 0x00a8, 0xff07, 0xf704, 0x5505, 0x0000, 0x0000, 0x0000, 0x0000, 0x0000, 0x0000, 0x0000, 0x0000, 0x0000, 0x0000, 0x0000, 0x0000, 0x0000, 0x0000, 0x0000, 0x0000, 0x0000, 0x0000,
  0x0000, 0x0000, 0x0000, 0x0000, 0x0000, 0x0000, 0x0000, 0x0000, 0x0000, 0x0000, 0x0000, 0x0000, 0x0000, 0x0000, 0x0000, 0x0000, 0x0000, 0x0000, 0x0000, 0x0000, 0x0000, 0x0000, 0x4145, 0x6145, 0x0000, 0x0000, 0x4e02, 0x4e02, 0x0000, 0x40d6, 0x00ce, 0x00ce, 0xe0cd, 0xe044, 0x8145, 0x4055, 0x0000, 0xe0cd, 0xc1cd, 0x62cd, 0xe0cd, 0x00ce, 0x00ce, 0x00ce, 0x6f02, 0x4e02, 0xcb29, 0x00b0, 0x00ce, 0x00ce, 0x00ce, 0x00ce, 0x00ce, 0x00ce, 0x00ce, 0x40d6, 0x0000, 0x20a8, 0x20b0, 0x960c, 0x9604, 0x9604, 0x824d, 0x4145, 0x0000, 0x0000, 0x0000, 0x0000, 0x0000, 0x0000, 0x0000, 0x0000, 0x0000, 0x0000, 0x0000, 0x0000, 0x0000, 0x0000, 0x0000, 0x0000,
  0x0000, 0x0000, 0x0000, 0x0000, 0x0000, 0x0000, 0x0000, 0x0000, 0x0000, 0x0000, 0x0000, 0x0000, 0x0000, 0x0000, 0x0000, 0x0000, 0x0000, 0x0000, 0x0000, 0x00b8, 0x20b0, 0x00b0, 0x7698, 0x5698, 0x0000, 0x0000, 0x819c, 0x619c, 0x819c, 0x00b8, 0x20b0, 0x00b0, 0x0000, 0x414d, 0x6145, 0x6145, 0x819c, 0x619c, 0x8f99, 0x3690, 0x7590, 0x819c, 0x619c, 0x619c, 0x619c, 0x619c, 0x80a8, 0x20b0, 0x409c, 0x619c, 0x619c, 0x409c, 0x0000, 0x824d, 0x614d, 0xe045, 0x0000, 0x819c, 0x619c, 0xe39b, 0x9490, 0x1698, 0x6145, 0x6145, 0x0000, 0x0000, 0x0000, 0x0000, 0x0000, 0x0000, 0x0000, 0x0000, 0x0000, 0x0000, 0x0000, 0x0000, 0x0000, 0x0000, 0x0000, 0x0000,
  0x0000, 0x0000, 0x0000, 0x0000, 0x0000, 0x0000, 0x0000, 0x0000, 0x0000, 0x0000, 0x0000, 0x0000, 0x0000, 0x0000, 0x0000, 0x0000, 0x0000, 0x0000, 0x0000, 0x00b0, 0x20b0, 0x20b0, 0x3590, 0x3590, 0xa0d6, 0xe0cd, 0xe1ac, 0x81a4, 0x619c, 0x00b0, 0x20b0, 0xe1a1, 0x619c, 0x609c, 0xa0d6, 0xe0cd, 0xe1ac, 0x81a4, 0x619c, 0xa0d6, 0xe0cd, 0xe1ac, 0xc1ac, 0xc1ac, 0xc1ac, 0x619c, 0x419c, 0xc1cd, 0x20b5, 0xc1a4, 0x619c, 0x619c, 0x819c, 0x6145, 0x6145, 0x2145, 0xe0cd, 0x01ad, 0xa1a4, 0x039c, 0x9379, 0x5671, 0x0000, 0x0000, 0x0000, 0x0000, 0x0000, 0x0000, 0x0000, 0x0000, 0x0000, 0x0000, 0x0000, 0x0000, 0x0000, 0x0000, 0x0000, 0x0000, 0x0000, 0x0000,
  0x0000, 0x0000, 0x0000, 0x0000, 0x0000, 0x0000, 0x0000, 0x0000, 0x0000, 0x0000, 0x0000, 0x0000, 0x0000, 0x0000, 0x0000, 0x0000, 0x0000, 0x0000, 0x0000, 0x1002, 0x4e02, 0x6f02, 0x0000, 0x0000, 0xc1cd, 0x00ce, 0x00ce, 0x20b5, 0x619c, 0xe0bd, 0x00ce, 0x01b5, 0xa1a4, 0x619c, 0xc1cd, 0x00ce, 0x00ce, 0x20b5, 0x619c, 0x20d6, 0x00ce, 0x00ce, 0x00ce, 0xc0cd, 0x80c5, 0x81bd, 0x0000, 0xe0cd, 0x00ce, 0xe0cd, 0x01ad, 0x81a4, 0x619c, 0x619c, 0x0000, 0x0000, 0x00ce, 0x00ce, 0x80bd, 0x6294, 0x931c, 0x9504, 0x20a8, 0x20a8, 0x0000, 0x0000, 0x0000, 0x0000, 0x0000, 0x0000, 0x0000, 0x0000, 0x0000, 0x0000, 0x0000, 0x0000, 0x0000, 0x0000, 0x0000, 0x0000,
  0x0000, 0x0000, 0x0000, 0x0000, 0x0000, 0x0000, 0x0000, 0x0000, 0x0000, 0x0000, 0x0000, 0x0000, 0x0000, 0x0000, 0x0000, 0x0000, 0x0000, 0x0000, 0x0000, 0x9002, 0x4e02, 0x4e02, 0x0000, 0x0000, 0xc1cd, 0x00ce, 0x00ce, 0x20b5, 0x619c, 0xc1cd, 0x00ce, 0x00ce, 0x20b5, 0x619c, 0xc1cd, 0x00ce, 0x00ce, 0x20b5, 0x619c, 0x0000, 0x0000, 0x00ce, 0x00ce, 0x80bd, 0x619c, 0x419c, 0x4e02, 0x049d, 0x00ce, 0x00ce, 0x00ce, 0x40bd, 0xa1a4, 0x619c, 0x619c, 0x009c, 0x00ce, 0x00ce, 0x80bd, 0x619c, 0x419c, 0x0000, 0x20b0, 0x20b0, 0x0000, 0x0000, 0x0000, 0x0000, 0x0000, 0x0000, 0x0000, 0x0000, 0x0000, 0x0000, 0x0000, 0x0000, 0x0000, 0x0000, 0x0000, 0x0000,
  0x0000, 0x0000, 0x0000, 0x0000, 0x0000, 0x0000, 0x0000, 0x0000, 0x0000, 0x0000, 0x0000, 0x0000, 0x0000, 0x0000, 0x0000, 0x0000, 0x0000, 0x0000, 0x0318, 0x3690, 0x17a0, 0x0000, 0x20b0, 0x20b0, 0xc1cd, 0x00ce, 0x00ce, 0x20b5, 0x619c, 0xc1cd, 0x00ce, 0x00ce, 0x20b5, 0x619c, 0xc1cd, 0x00ce, 0x00ce, 0x20b5, 0xa49b, 0x3690, 0x17a0, 0x00ce, 0x00ce, 0x80bd, 0x619c, 0x419c, 0x4e02, 0xa584, 0x00ce, 0xe0cd, 0x60bd, 0xc0cd, 0x80c5, 0xe1ac, 0x619c, 0x619c, 0xc0c5, 0x00ce, 0x80bd, 0x619c, 0x419c, 0x9604, 0xb604, 0x4145, 0x4134, 0x4000, 0x0000, 0x0000, 0x0000, 0x0000, 0x0000, 0x0000, 0x0000, 0x0000, 0x0000, 0x0000, 0x0000, 0x0000, 0x0000, 0x0000,
  0x0000, 0x0000, 0x0000, 0x0000, 0x0000, 0x0000, 0x0000, 0x0000, 0x0000, 0x0000, 0x0000, 0x0000, 0x0000, 0x0000, 0x0000, 0x0000, 0x0000, 0x0000, 0x0318, 0x3590, 0x1698, 0x0000, 0x20a8, 0x20b0, 0xc1cd, 0x00ce, 0x00ce, 0x20b5, 0x619c, 0xa1a4, 0xe0cd, 0x00ce, 0x20b5, 0x619c, 0xa1a4, 0xe0cd, 0x00ce, 0x60bd, 0x279b, 0x3590, 0x1698, 0x00ce, 0x00ce, 0x80bd, 0x619c, 0x419c, 0x3690, 0x07bc, 0x00ce, 0xc0cd, 0x81a4, 0x40b5, 0x00ce, 0xc0c5, 0x20b5, 0x819c, 0x80bd, 0x00ce, 0x80bd, 0x619c, 0x419c, 0x9604, 0x7504, 0x614d, 0x613c, 0x4000, 0x0000, 0x0000, 0x0000, 0x0000, 0x0000, 0x0000, 0x0000, 0x0000, 0x0000, 0x0000, 0x0000, 0x0000, 0x0000, 0x0000,
  0x0000, 0x0000, 0x0000, 0x0000, 0x0000, 0x0000, 0x0000, 0x0000, 0x0000, 0x0000, 0x0000, 0x0000, 0x0000, 0x0000, 0x0000, 0x0000, 0x0000, 0x0000, 0x0000, 0x0000, 0x0000, 0x6145, 0x6145, 0x0000, 0xc0d5, 0x00ce, 0xe0cd, 0xa0c5, 0x40bd, 0x60bd, 0xe0cd, 0x00ce, 0xa0c5, 0x40bd, 0x60bd, 0xe0cd, 0x00ce, 0xe85b, 0x4e02, 0x0000, 0x0000, 0x00ce, 0x00ce, 0x80bd, 0x619c, 0x619c, 0xae99, 0x27bc, 0x00ce, 0xc0cd, 0x81a4, 0x419c, 0x00d6, 0x00ce, 0xe0cd, 0x60bd, 0xc0cd, 0x00ce, 0x80bd, 0x619c, 0x419c, 0x3690, 0x3690, 0x0000, 0x0000, 0x0000, 0x0000, 0x0000, 0x0000, 0x0000, 0x0000, 0x0000, 0x0000, 0x0000, 0x0000, 0x0000, 0x0000, 0x0000, 0x0000, 0x0000,
  0x0000, 0x0000, 0x0000, 0x0000, 0x0000, 0x0000, 0x0000, 0x0000, 0x0000, 0x0000, 0x0000, 0x0000, 0x0000, 0x0000, 0x0000, 0x0000, 0x0000, 0x0000, 0x0000, 0x7504, 0x9604, 0x0a2d, 0x6145, 0x0000, 0x00a8, 0x20b0, 0x80c3, 0x00ce, 0x00ce, 0x00ce, 0x00ce, 0xe0cd, 0x00ce, 0x00ce, 0x00ce, 0x00ce, 0xe1d5, 0x2e02, 0x4e02, 0xe0cd, 0x00ce, 0x00ce, 0x00ce, 0xc0cd, 0x60bd, 0xa1a4, 0x819c, 0xe0cd, 0x00ce, 0xe0cd, 0xc0ac, 0x819c, 0x0000, 0xe1d5, 0xe0cd, 0xe0cd, 0x00ce, 0x00ce, 0xc0c5, 0x619c, 0x009c, 0x5698, 0x3598, 0x9504, 0xf203, 0x4100, 0x0000, 0x0000, 0x0000, 0x0000, 0x0000, 0x0000, 0x0000, 0x0000, 0x0000, 0x0000, 0x0000, 0x0000, 0x0000, 0x0000,
  0x0000, 0x0000, 0x0000, 0x0000, 0x0000, 0x0000, 0x0000, 0x0000, 0x0000, 0x0000, 0x0000, 0x0000, 0x0000, 0x0000, 0x0000, 0x0000, 0x0000, 0x0000, 0x0000, 0x1304, 0x9604, 0xe490, 0x20b0, 0x0000, 0x0098, 0x20b0, 0x41b0, 0x00d6, 0x00ce, 0xa5a5, 0xb50c, 0x9504, 0x00d6, 0x00ce, 0x00ce, 0xe0bd, 0x20a8, 0x20b0, 0x0000, 0xe0bd, 0x00ce, 0x00ce, 0x00ce, 0x00ce, 0x00ce, 0xe0bd, 0x0000, 0x00d6, 0x00ce, 0x00ce, 0xe0bd, 0x0000, 0x4e02, 0x4e02, 0x0000, 0x0000, 0xe0cd, 0x00ce, 0xe0cd, 0x0000, 0x0000, 0x0000, 0x4e02, 0xb002, 0x5003, 0x2000, 0x0000, 0x0000, 0x0000, 0x0000, 0x0000, 0x0000, 0x0000, 0x0000, 0x0000, 0x0000, 0x0000, 0x0000, 0x0000, 0x0000,
  0x0000, 0x0000, 0x0000, 0x0000, 0x0000, 0x0000, 0x0000, 0x0000, 0x0000, 0x0000, 0x0000, 0x0000, 0x0000, 0x0000, 0x0000, 0x0000, 0x0000, 0x0000, 0x0000, 0x0000, 0x0000, 0x20b0, 0x41b0, 0x0000, 0x1698, 0x3690, 0x3690, 0x0000, 0x0000, 0x1504, 0x9504, 0x433d, 0x6145, 0x0000, 0x0000, 0x0000, 0x20b0, 0x41b0, 0x0000, 0x0000, 0x0000, 0x0000, 0x0000, 0x6145, 0x6145, 0x2145, 0x0000, 0x3590, 0x3590, 0x00b0, 0x20b0, 0x20b0, 0x6e02, 0x4e02, 0x1698, 0x3690, 0x3690, 0x0000, 0x20b0, 0x20b0, 0x00b0, 0x0000, 0x6e02, 0x4e02, 0x0000, 0x0000, 0x0000, 0x0000, 0x0000, 0x0000, 0x0000, 0x0000, 0x0000, 0x0000, 0x0000, 0x0000, 0x0000, 0x0000, 0x0000, 0x0000,
  0x0000, 0x0000, 0x0000, 0x0000, 0x0000, 0x0000, 0x0000, 0x0000, 0x0000, 0x0000, 0x0000, 0x0000, 0x0000, 0x0000, 0x0000, 0x0000, 0x0000, 0x0000, 0x0000, 0x6145, 0x6145, 0x414d, 0x0000, 0x4f02, 0x4e0a, 0xf360, 0x1698, 0x0000, 0x41a8, 0x20b0, 0x61a8, 0x4145, 0x414d, 0x414d, 0x6145, 0x6145, 0x4e02, 0x4e02, 0x0000, 0x550c, 0x9604, 0x950c, 0x0000, 0x824d, 0x614d, 0xe045, 0x0000, 0x7698, 0x5698, 0x00b8, 0x20b0, 0x00b0, 0x0000, 0x4f02, 0x4e0a, 0xf360, 0x1698, 0x9604, 0x3414, 0x20b0, 0x00b8, 0x6145, 0x6145, 0x0000, 0x0000, 0x0000, 0x0000, 0x0000, 0x0000, 0x0000, 0x0000, 0x0000, 0x0000, 0x0000, 0x0000, 0x0000, 0x0000, 0x0000, 0x0000, 0x0000,
  0x0000, 0x0000, 0x0000, 0x0000, 0x0000, 0x0000, 0x0000, 0x0000, 0x0000, 0x0000, 0x0000, 0x0000, 0x0000, 0x0000, 0x0000, 0x0000, 0x0000, 0x0000, 0x0000, 0x4055, 0x8145, 0xe044, 0x0000, 0x1002, 0x6f02, 0xaa02, 0x9604, 0x9504, 0x0098, 0x41b0, 0x00a8, 0x0000, 0x0000, 0xe044, 0x8145, 0x4055, 0x2e02, 0x7580, 0x3690, 0x5505, 0x960c, 0x1304, 0x0000, 0x20b0, 0x20b0, 0x41b0, 0x0000, 0x9504, 0x9604, 0x0000, 0x0000, 0x0000, 0x0000, 0x1002, 0x6f02, 0xaa02, 0x0000, 0x5604, 0x7504, 0x0000, 0x0000, 0x4145, 0x824d, 0x0000, 0x0000, 0x0000, 0x0000, 0x0000, 0x0000, 0x0000, 0x0000, 0x0000, 0x0000, 0x0000, 0x0000, 0x0000, 0x0000, 0x0000, 0x0000, 0x0000,
  0x0000, 0x0000, 0x0000, 0x0000, 0x0000, 0x0000, 0x0000, 0x0000, 0x0000, 0x0000, 0x0000, 0x0000, 0x0000, 0x0000, 0x0000, 0x0000, 0x0000, 0x0000, 0x0000, 0x0000, 0x0000, 0x0000, 0x0000, 0x0000, 0x0000, 0x0000, 0x2000, 0x0000, 0x0000, 0x0000, 0x0000, 0x0000, 0x0000, 0x0000, 0x0000, 0x0000, 0x0000, 0x0000, 0x0000, 0x0000, 0x0000, 0x0000, 0x0000, 0x0000, 0x0000, 0x0000, 0x0000, 0x0000, 0x2000, 0x0000, 0x0000, 0x0000, 0x0000, 0x0000, 0x0000, 0x0000, 0x0000, 0x0000, 0x0000, 0x0000, 0x0000, 0x0000, 0x0000, 0x0000, 0x0000, 0x0000, 0x0000, 0x0000, 0x0000, 0x0000, 0x0000, 0x0000, 0x0000, 0x0000, 0x0000, 0x0000, 0x0000, 0x0000, 0x0000, 0x0000,
  0x0000, 0x0000, 0x0000, 0x0000, 0x0000, 0x0000, 0x0000, 0x0000, 0x0000, 0x0000, 0x0000, 0x0000, 0x0000, 0x0000, 0x0000, 0x0000, 0x0000, 0x0000, 0x0000, 0x0000, 0x0000, 0x0000, 0x0000, 0x0000, 0x0000, 0x0000, 0x0000, 0x0000, 0x0000, 0x0000, 0x0000, 0x0000, 0x0000, 0x0000, 0x0000, 0x0000, 0x0000, 0x0000, 0x0000, 0x0000, 0x0000, 0x0000, 0x0000, 0x0000, 0x0000, 0x0000, 0x0000, 0x0000, 0x0000, 0x0000, 0x0000, 0x0000, 0x0000, 0x0000, 0x0000, 0x0000, 0x0000, 0x0000, 0x0000, 0x0000, 0x0000, 0x0000, 0x0000, 0x0000, 0x0000, 0x0000, 0x0000, 0x0000, 0x0000, 0x0000, 0x0000, 0x0000, 0x0000, 0x0000, 0x0000, 0x0000, 0x0000, 0x0000, 0x0000, 0x0000,
  0x0000, 0x0000, 0x0000, 0x0000, 0x0000, 0x0000, 0x0000, 0x0000, 0x0000, 0x0000, 0x0000, 0x0000, 0x0000, 0x0000, 0x0000, 0x0000, 0x0000, 0x0000, 0x0000, 0x0000, 0x0000, 0x0000, 0x0000, 0x0000, 0x0000, 0x0000, 0x0000, 0x0000, 0x0000, 0x0000, 0x0000, 0x0000, 0x0000, 0x0000, 0x0000, 0x0000, 0x0000, 0x0000, 0x0000, 0x0000, 0x0000, 0x0000, 0x0000, 0x0000, 0x0000, 0x0000, 0x0000, 0x0000, 0x0000, 0x0000, 0x0000, 0x0000, 0x0000, 0x0000, 0x0000, 0x0000, 0x0000, 0x0000, 0x0000, 0x0000, 0x0000, 0x0000, 0x0000, 0x0000, 0x0000, 0x0000, 0x0000, 0x0000, 0x0000, 0x0000, 0x0000, 0x0000, 0x0000, 0x0000, 0x0000, 0x0000, 0x0000, 0x0000, 0x0000, 0x0000,
  0x0000, 0x0000, 0x0000, 0x0000, 0x0000, 0x0000, 0x0000, 0x0000, 0x0000, 0x0000, 0x0000, 0x0000, 0x0000, 0x0000, 0x0000, 0x0000, 0x0000, 0x0000, 0x0000, 0x0000, 0x0000, 0x0000, 0x0000, 0x0000, 0x0000, 0x0000, 0x0000, 0x0000, 0x0000, 0x0000, 0x0000, 0x0000, 0x0000, 0x0000, 0x0000, 0x0000, 0x0000, 0x0000, 0x0000, 0x0000, 0x0000, 0x0000, 0x0000, 0x0000, 0x0000, 0x0000, 0x0000, 0x0000, 0x0000, 0x0000, 0x0000, 0x0000, 0x0000, 0x0000, 0x0000, 0x0000, 0x0000, 0x0000, 0x0000, 0x0000, 0x0000, 0x0000, 0x0000, 0x0000, 0x0000, 0x0000, 0x0000, 0x0000, 0x0000, 0x0000, 0x0000, 0x0000, 0x0000, 0x0000, 0x0000, 0x0000, 0x0000, 0x0000, 0x0000, 0x0000,
  0x0000, 0x0000, 0x0000, 0x0000, 0x0000, 0x0000, 0x0000, 0x0000, 0x0000, 0x0000, 0x0000, 0x0000, 0x0000, 0x0000, 0x0000, 0x0000, 0x0000, 0x0000, 0x0000, 0x0000, 0x0000, 0x0000, 0x0000, 0x0000, 0x0000, 0x0000, 0x0000, 0x0000, 0x0000, 0x0000, 0x0000, 0x0000, 0x0000, 0x0000, 0x0000, 0x0000, 0x0000, 0x0000, 0x0000, 0x0000, 0x0000, 0x0000, 0x0000, 0x0000, 0x0000, 0x0000, 0x0000, 0x0000, 0x0000, 0x0000, 0x0000, 0x0000, 0x0000, 0x0000, 0x0000, 0x0000, 0x0000, 0x0000, 0x0000, 0x0000, 0x0000, 0x0000, 0x0000, 0x0000, 0x0000, 0x0000, 0x0000, 0x0000, 0x0000, 0x0000, 0x0000, 0x0000, 0x0000, 0x0000, 0x0000, 0x0000, 0x0000, 0x0000, 0x0000, 0x0000,
  0x0000, 0x0000, 0x0000, 0x0000, 0x0000, 0x0000, 0x0000, 0x0000, 0x0000, 0x0000, 0x0000, 0x0000, 0x0000, 0x0000, 0x0000, 0x0000, 0x0000, 0x0000, 0x0000, 0x0000, 0x0000, 0x0000, 0x0000, 0x0000, 0x0000, 0x0000, 0x0000, 0x0000, 0x0000, 0x0000, 0x0000, 0x0000, 0x0000, 0x0000, 0x0000, 0x0000, 0x0000, 0x0000, 0x0000, 0x0000, 0x0000, 0x0000, 0x0000, 0x0000, 0x0000, 0x0000, 0x0000, 0x0000, 0x0000, 0x0000, 0x0000, 0x0000, 0x0000, 0x0000, 0x0000, 0x0000, 0x0000, 0x0000, 0x0000, 0x0000, 0x0000, 0x0000, 0x0000, 0x0000, 0x0000, 0x0000, 0x0000, 0x0000, 0x0000, 0x0000, 0x0000, 0x0000, 0x0000, 0x0000, 0x0000, 0x0000, 0x0000, 0x0000, 0x0000, 0x0000,
  0x0000, 0x0000, 0x0000, 0x0000, 0x0000, 0x0000, 0x0000, 0x0000, 0x0000, 0x0000, 0x0000, 0x0000, 0x0000, 0x0000, 0x0000, 0x0000, 0x0000, 0x0000, 0x0000, 0x0000, 0x0000, 0x0000, 0x0000, 0x0000, 0x0000, 0x0000, 0x0000, 0x0000, 0x0000, 0x0000, 0x0000, 0x0000, 0x0000, 0x0000, 0x0000, 0x0000, 0x0000, 0x0000, 0x0000, 0x0000, 0x0000, 0x0000, 0x0000, 0x0000, 0x0000, 0x0000, 0x0000, 0x0000, 0x0000, 0x0000, 0x0000, 0x0000, 0x0000, 0x0000, 0x0000, 0x0000, 0x0000, 0x0000, 0x0000, 0x0000, 0x0000, 0x0000, 0x0000, 0x0000, 0x0000, 0x0000, 0x0000, 0x0000, 0x0000, 0x0000, 0x0000, 0x0000, 0x0000, 0x0000, 0x0000, 0x0000, 0x0000, 0x0000, 0x0000, 0x0000,
  0x0000, 0x0000, 0x0000, 0x0000, 0x0000, 0x0000, 0x0000, 0x0000, 0x0000, 0x0000, 0x0000, 0x0000, 0x0000, 0x0000, 0x0000, 0x0000, 0x0000, 0x0000, 0x0000, 0x0000, 0x0000, 0x0000, 0x0000, 0x0000, 0x0000, 0x0000, 0x0000, 0x0000, 0x0000, 0x0000, 0x0000, 0x0000, 0x0000, 0x0000, 0x0000, 0x0000, 0x0000, 0x0000, 0x0000, 0x0000, 0x0000, 0x0000, 0x0000, 0x0000, 0x0000, 0x0000, 0x0000, 0x0000, 0x0000, 0x0000, 0x0000, 0x0000, 0x0000, 0x0000, 0x0000, 0x0000, 0x0000, 0x0000, 0x0000, 0x0000, 0x0000, 0x0000, 0x0000, 0x0000, 0x0000, 0x0000, 0x0000, 0x0000, 0x0000, 0x0000, 0x0000, 0x0000, 0x0000, 0x0000, 0x0000, 0x0000, 0x0000, 0x0000, 0x0000, 0x0000,
  0x0000, 0x0000, 0x0000, 0x0000, 0x0000, 0x0000, 0x0000, 0x0000, 0x0000, 0x0000, 0x0000, 0x0000, 0x0000, 0x0000, 0x0000, 0x0000, 0x0000, 0x0000, 0x0000, 0x0000, 0x0000, 0x0000, 0x0000, 0x0000, 0x0000, 0x0000, 0x0000, 0x0000, 0x0000, 0x0000, 0x0000, 0x0000, 0x0000, 0x0000, 0x0000, 0x0000, 0x0000, 0x0000, 0x0000, 0x0000, 0x0000, 0x0000, 0x0000, 0x0000, 0x0000, 0x0000, 0x0000, 0x0000, 0x0000, 0x0000, 0x0000, 0x0000, 0x0000, 0x0000, 0x0000, 0x0000, 0x0000, 0x0000, 0x0000, 0x0000, 0x0000, 0x0000, 0x0000, 0x0000, 0x0000, 0x0000, 0x0000, 0x0000, 0x0000, 0x0000, 0x0000, 0x0000, 0x0000, 0x0000, 0x0000, 0x0000, 0x0000, 0x0000, 0x0000, 0x0000,
  0x0000, 0x0000, 0x0000, 0x0000, 0x0000, 0x0000, 0x0000, 0x0000, 0x0000, 0x0000, 0x0000, 0x0000, 0x0000, 0x0000, 0x0000, 0x0000, 0x0000, 0x0000, 0x0000, 0x0000, 0x0000, 0x0000, 0x0000, 0x0000, 0x0000, 0x0000, 0x0000, 0x0000, 0x0000, 0x0000, 0x0000, 0x0000, 0x0000, 0x0000, 0x0000, 0x0000, 0x0000, 0x0000, 0x0000, 0x0000, 0x0000, 0x0000, 0x0000, 0x0000, 0x0000, 0x0000, 0x0000, 0x0000, 0x0000, 0x0000, 0x0000, 0x0000, 0x0000, 0x0000, 0x0000, 0x0000, 0x0000, 0x0000, 0x0000, 0x0000, 0x0000, 0x0000, 0x0000, 0x0000, 0x0000, 0x0000, 0x0000, 0x0000, 0x0000, 0x0000, 0x0000, 0x0000, 0x0000, 0x0000, 0x0000, 0x0000, 0x0000, 0x0000, 0x0000, 0x0000,
  0x0000, 0x0000, 0x0000, 0x0000, 0x0000, 0x0000, 0x0000, 0x0000, 0x0000, 0x0000, 0x0000, 0x0000, 0x0000, 0x0000, 0x0000, 0x0000, 0x0000, 0x0000, 0x0000, 0x0000, 0x0000, 0x0000, 0x0000, 0x0000, 0x0000, 0x0000, 0x0000, 0x0000, 0x0000, 0x0000, 0x0000, 0x0000, 0x0000, 0x0000, 0x0000, 0x0000, 0x0000, 0x0000, 0x0000, 0x0000, 0x0000, 0x0000, 0x0000, 0x0000, 0x0000, 0x0000, 0x0000, 0x0000, 0x0000, 0x0000, 0x0000, 0x0000, 0x0000, 0x0000, 0x0000, 0x0000, 0x0000, 0x0000, 0x0000, 0x0000, 0x0000, 0x0000, 0x0000, 0x0000, 0x0000, 0x0000, 0x0000, 0x0000, 0x0000, 0x0000, 0x0000, 0x0000, 0x0000, 0x0000, 0x0000, 0x0000, 0x0000, 0x0000, 0x0000, 0x0000,
  0x0000, 0x0000, 0x0000, 0x0000, 0x0000, 0x0000, 0x0000, 0x0000, 0x0000, 0x0000, 0x0000, 0x0000, 0x0000, 0x0000, 0x0000, 0x0000, 0x0000, 0x0000, 0x0000, 0x0000, 0x0000, 0x0000, 0x0000, 0x0000, 0x0000, 0x0000, 0x0000, 0x0000, 0x0000, 0x0000, 0x0000, 0x0000, 0x0000, 0x0000, 0x0000, 0x0000, 0x0000, 0x0000, 0x0000, 0x0000, 0x0000, 0x0000, 0x0000, 0x0000, 0x0000, 0x0000, 0x0000, 0x0000, 0x0000, 0x0000, 0x0000, 0x0000, 0x0000, 0x0000, 0x0000, 0x0000, 0x0000, 0x0000, 0x0000, 0x0000, 0x0000, 0x0000, 0x0000, 0x0000, 0x0000, 0x0000, 0x0000, 0x0000, 0x0000, 0x0000, 0x0000, 0x0000, 0x0000, 0x0000, 0x0000, 0x0000, 0x0000, 0x0000, 0x0000, 0x0000,
  0x0000, 0x0000, 0x0000, 0x0000, 0x0000, 0x0000, 0x0000, 0x0000, 0x0000, 0x0000, 0x0000, 0x0000, 0x0000, 0x0000, 0x0000, 0x0000, 0x0000, 0x0000, 0x0000, 0x0000, 0x0000, 0x0000, 0x0000, 0x0000, 0x0000, 0x0000, 0x0000, 0x0000, 0x0000, 0x0000, 0x0000, 0x0000, 0x0000, 0x0000, 0x0000, 0x0000, 0x0000, 0x0000, 0x0000, 0x0000, 0x0000, 0x0000, 0x0000, 0x0000, 0x0000, 0x0000, 0x0000, 0x0000, 0x0000, 0x0000, 0x0000, 0x0000, 0x0000, 0x0000, 0x0000, 0x0000, 0x0000, 0x0000, 0x0000, 0x0000, 0x0000, 0x0000, 0x0000, 0x0000, 0x0000, 0x0000, 0x0000, 0x0000, 0x0000, 0x0000, 0x0000, 0x0000, 0x0000, 0x0000, 0x0000, 0x0000, 0x0000, 0x0000, 0x0000, 0x0000,
  0x0000, 0x0000, 0x0000, 0x0000, 0x0000, 0x0000, 0x0000, 0x0000, 0x0000, 0x0000, 0x0000, 0x0000, 0x0000, 0x0000, 0x0000, 0x0000, 0x0000, 0x0000, 0x0000, 0x0000, 0x0000, 0x0000, 0x0000, 0x0000, 0x0000, 0x0000, 0x0000, 0x0000, 0x0000, 0x0000, 0x0000, 0x0000, 0x0000, 0x0000, 0x0000, 0x0000, 0x0000, 0x0000, 0x0000, 0x0000, 0x0000, 0x0000, 0x0000, 0x0000, 0x0000, 0x0000, 0x0000, 0x0000, 0x0000, 0x0000, 0x0000, 0x0000, 0x0000, 0x0000, 0x0000, 0x0000, 0x0000, 0x0000, 0x0000, 0x0000, 0x0000, 0x0000, 0x0000, 0x0000, 0x0000, 0x0000, 0x0000, 0x0000, 0x0000, 0x0000, 0x0000, 0x0000, 0x0000, 0x0000, 0x0000, 0x0000, 0x0000, 0x0000, 0x0000, 0x0000,
  0x0000, 0x0000, 0x0000, 0x0000, 0x0000, 0x0000, 0x0000, 0x0000, 0x0000, 0x0000, 0x0000, 0x0000, 0x0000, 0x0000, 0x0000, 0x0000, 0x0000, 0x0000, 0x0000, 0x0000, 0x0000, 0x0000, 0x0000, 0x0000, 0x0000, 0x0000, 0x0000, 0x0000, 0x0000, 0x0000, 0x0000, 0x0000, 0x0000, 0x0000, 0x0000, 0x0000, 0x0000, 0x0000, 0x0000, 0x0000, 0x0000, 0x0000, 0x0000, 0x0000, 0x0000, 0x0000, 0x0000, 0x0000, 0x0000, 0x0000, 0x0000, 0x0000, 0x0000, 0x0000, 0x0000, 0x0000, 0x0000, 0x0000, 0x0000, 0x0000, 0x0000, 0x0000, 0x0000, 0x0000, 0x0000, 0x0000, 0x0000, 0x0000, 0x0000, 0x0000, 0x0000, 0x0000, 0x0000, 0x0000, 0x0000, 0x0000, 0x0000, 0x0000, 0x0000, 0x0000,
  0x0000, 0x0000, 0x0000, 0x0000, 0x0000, 0x0000, 0x0000, 0x0000, 0x0000, 0x0000, 0x0000, 0x0000, 0x0000, 0x0000, 0x0000, 0x0000, 0x0000, 0x0000, 0x0000, 0x0000, 0x0000, 0x0000, 0x0000, 0x0000, 0x0000, 0x0000, 0x0000, 0x0000, 0x0000, 0x0000, 0x0000, 0x0000, 0x0000, 0x0000, 0x0000, 0x0000, 0x0000, 0x0000, 0x0000, 0x0000, 0x0000, 0x0000, 0x0000, 0x0000, 0x0000, 0x0000, 0x0000, 0x0000, 0x0000, 0x0000, 0x0000, 0x0000, 0x0000, 0x0000, 0x0000, 0x0000, 0x0000, 0x0000, 0x0000, 0x0000, 0x0000, 0x0000, 0x0000, 0x0000, 0x0000, 0x0000, 0x0000, 0x0000, 0x0000, 0x0000, 0x0000, 0x0000, 0x0000, 0x0000, 0x0000, 0x0000, 0x0000, 0x0000, 0x0000, 0x0000
};

static const uint16_t Carta[][15*15/2]= {
  0x0000, 0x0000, 0x0000, 0x0000, 0x0000, 0x0000, 0x0000, 0x0000, 0x0000, 0x0000, 0x0000, 0x0000, 0x0000, 0x0000, 0x0000,
  0x0000, 0x00f8, 0x00f8, 0x00f8, 0x00f8, 0x00f8, 0x00f8, 0x00f8, 0x00f8, 0x00f8, 0x00f8, 0x00f8, 0x00f8, 0x00f8, 0x0000,
  0x0000, 0x00f8, 0x00f8, 0x00f8, 0x00f8, 0x00f8, 0x00f8, 0x0000, 0x00f8, 0x00f8, 0x00f8, 0x00f8, 0x00f8, 0x00f8, 0x0000,
  0x0000, 0x00f8, 0x00f8, 0x00f8, 0x00f8, 0x00f8, 0x00f8, 0x0000, 0x0000, 0x00f8, 0x00f8, 0x00f8, 0x00f8, 0x00f8, 0x0000,
  0x0000, 0x00f8, 0x00f8, 0x00f8, 0x00f8, 0x00f8, 0x00f8, 0x0000, 0x0000, 0x00f8, 0x00f8, 0x00f8, 0x00f8, 0x00f8, 0x0000,
  0x0000, 0x00f8, 0x00f8, 0x00f8, 0x00f8, 0x00f8, 0x0000, 0x00f8, 0x00f8, 0x0000, 0x00f8, 0x00f8, 0x00f8, 0x00f8, 0x0000,
  0x0000, 0x00f8, 0x00f8, 0x00f8, 0x0000, 0x0000, 0x0000, 0x00f8, 0x00f8, 0x0000, 0x0000, 0x0000, 0x0000, 0x00f8, 0x0000,
  0x0000, 0x0000, 0x0000, 0x0000, 0x00f8, 0x00f8, 0x00f8, 0x00f8, 0x00f8, 0x00f8, 0x00f8, 0x00f8, 0x0000, 0x0000, 0x0000,
  0x0000, 0x00f8, 0x00f8, 0x00f8, 0x0000, 0x0000, 0x0000, 0x00f8, 0x00f8, 0x0000, 0x0000, 0x0000, 0x00f8, 0x00f8, 0x0000,
  0x0000, 0x00f8, 0x00f8, 0x00f8, 0x00f8, 0x00f8, 0x0000, 0x00f8, 0x00f8, 0x0000, 0x00f8, 0x00f8, 0x00f8, 0x00f8, 0x0000,
  0x0000, 0x00f8, 0x00f8, 0x00f8, 0x00f8, 0x00f8, 0x00f8, 0x0000, 0x0000, 0x00f8, 0x00f8, 0x00f8, 0x00f8, 0x00f8, 0x0000,
  0x0000, 0x00f8, 0x00f8, 0x00f8, 0x00f8, 0x00f8, 0x00f8, 0x0000, 0x0000, 0x00f8, 0x00f8, 0x00f8, 0x00f8, 0x00f8, 0x0000,
  0x0000, 0x00f8, 0x00f8, 0x00f8, 0x00f8, 0x00f8, 0x00f8, 0x0000, 0x00f8, 0x00f8, 0x00f8, 0x00f8, 0x00f8, 0x00f8, 0x0000,
  0x0000, 0x00f8, 0x00f8, 0x00f8, 0x00f8, 0x00f8, 0x00f8, 0x00f8, 0x00f8, 0x00f8, 0x00f8, 0x00f8, 0x00f8, 0x00f8, 0x0000,
  0x0000, 0x0000, 0x0000, 0x0000, 0x0000, 0x0000, 0x0000, 0x0000, 0x0000, 0x0000, 0x0000, 0x0000, 0x0000, 0x0000, 0x0000
};

int QuantidadeJogadores = 0;
int VerificarJogador = 1;
int PontosJogador1 = 0;
int PontosJogador2 = 0;

int ColunaMatriz = 0;
int LinhaMatriz = 0;
int PaddingX = 0;
int PaddingY = 0;

int cores [8]={RED,YELLOW,GREEN,BLUE,CYAN,MAGENTA,BROWN,WHITE};
int linha = 0;
int coluna = 0;
int posicoes[4][4] =
	{
	{8,8,8,8},
    {8,8,8,8},
	{8,8,8,8},
	{8,8,8,8}
	};
int pos_selec1[2]={8,8};
int pos_selec2[2]={8,8};
int JogoAndamento = 0;
int tentativas = 0;
int TentativasRecorde = 0;
char po[3];
/* USER CODE END PV */

void SystemClock_Config(void);
static void MX_GPIO_Init(void);
static void MX_SPI1_Init(void);
/* USER CODE BEGIN PFP */
void MostrarCartas();
void GerarParesAleatorios();
void IniciarJogo();
void NavegarCursor(int nav);
void SelecionarCarta();
void CompararCarta();
void VerificarFimDeJogo();
void AtualizarTentativas();
void AtualizarRecorde();
void ExibirFimDeJogo();
void ModificarJogador();
void TamanhoMatriz();
/* USER CODE END PFP */

int main(void)
{

  /* MCU Configuration--------------------------------------------------------*/

  /* Reset of all peripherals, Initializes the Flash interface and the Systick. */
  HAL_Init();

  /* Configure the system clock */
  SystemClock_Config();

  /* Initialize all configured peripherals */
  MX_GPIO_Init();
  MX_SPI1_Init();
  /* USER CODE BEGIN 2 */
  ST7735_Init();
  /* USER CODE END 2 */

  /* Infinite loop */
  /* USER CODE BEGIN WHILE */
  while (1)
  {
	  IniciarJogo();
	  NavegarCursor(8);
	  while(JogoAndamento == 1)
	  {
		  int nav = 0;
		  int cima = HAL_GPIO_ReadPin(GPIOA, GPIO_PIN_12);
		  int direita = HAL_GPIO_ReadPin(GPIOA, GPIO_PIN_11);
		  int esquerda = HAL_GPIO_ReadPin(GPIOA, GPIO_PIN_9);
		  int btnSelec = HAL_GPIO_ReadPin(GPIOA, GPIO_PIN_10);
		  if(esquerda == 0)
		  {
			  nav = 1;
			  NavegarCursor(nav);
		  }
		  if(cima == 0)
		  {
			  nav = 2;
			  NavegarCursor(nav);
		  }
		  if(direita == 0)
		  {
			  nav = 3;
			  NavegarCursor(nav);
		  }
		  if(btnSelec == 0)
		  {
			  //HAL_Delay(200);
			  CompararCarta();
			  VerificarFimDeJogo();
		  }
	  }
	  AtualizarRecorde();
	  ExibirFimDeJogo();

    /* USER CODE END WHILE */

  }
}

void SystemClock_Config(void)
{
  RCC_OscInitTypeDef RCC_OscInitStruct = {0};
  RCC_ClkInitTypeDef RCC_ClkInitStruct = {0};

  /** Initializes the RCC Oscillators according to the specified parameters
  * in the RCC_OscInitTypeDef structure.
  */
  RCC_OscInitStruct.OscillatorType = RCC_OSCILLATORTYPE_HSI;
  RCC_OscInitStruct.HSIState = RCC_HSI_ON;
  RCC_OscInitStruct.HSICalibrationValue = RCC_HSICALIBRATION_DEFAULT;
  RCC_OscInitStruct.PLL.PLLState = RCC_PLL_ON;
  RCC_OscInitStruct.PLL.PLLSource = RCC_PLLSOURCE_HSI_DIV2;
  RCC_OscInitStruct.PLL.PLLMUL = RCC_PLL_MUL16;
  if (HAL_RCC_OscConfig(&RCC_OscInitStruct) != HAL_OK)
  {
    Error_Handler();
  }
  /** Initializes the CPU, AHB and APB buses clocks
  */
  RCC_ClkInitStruct.ClockType = RCC_CLOCKTYPE_HCLK|RCC_CLOCKTYPE_SYSCLK
                              |RCC_CLOCKTYPE_PCLK1|RCC_CLOCKTYPE_PCLK2;
  RCC_ClkInitStruct.SYSCLKSource = RCC_SYSCLKSOURCE_PLLCLK;
  RCC_ClkInitStruct.AHBCLKDivider = RCC_SYSCLK_DIV1;
  RCC_ClkInitStruct.APB1CLKDivider = RCC_HCLK_DIV2;
  RCC_ClkInitStruct.APB2CLKDivider = RCC_HCLK_DIV1;

  if (HAL_RCC_ClockConfig(&RCC_ClkInitStruct, FLASH_LATENCY_2) != HAL_OK)
  {
    Error_Handler();
  }
}

static void MX_SPI1_Init(void)
{

  /* SPI1 parameter configuration*/
  hspi1.Instance = SPI1;
  hspi1.Init.Mode = SPI_MODE_MASTER;
  hspi1.Init.Direction = SPI_DIRECTION_1LINE;
  hspi1.Init.DataSize = SPI_DATASIZE_8BIT;
  hspi1.Init.CLKPolarity = SPI_POLARITY_LOW;
  hspi1.Init.CLKPhase = SPI_PHASE_1EDGE;
  hspi1.Init.NSS = SPI_NSS_SOFT;
  hspi1.Init.BaudRatePrescaler = SPI_BAUDRATEPRESCALER_32;
  hspi1.Init.FirstBit = SPI_FIRSTBIT_MSB;
  hspi1.Init.TIMode = SPI_TIMODE_DISABLE;
  hspi1.Init.CRCCalculation = SPI_CRCCALCULATION_DISABLE;
  hspi1.Init.CRCPolynomial = 10;
  if (HAL_SPI_Init(&hspi1) != HAL_OK)
  {
    Error_Handler();
  }

}

static void MX_GPIO_Init(void)
{
  GPIO_InitTypeDef GPIO_InitStruct = {0};

  /* GPIO Ports Clock Enable */
  __HAL_RCC_GPIOA_CLK_ENABLE();
  __HAL_RCC_GPIOB_CLK_ENABLE();

  /*Configure GPIO pin Output Level */
  HAL_GPIO_WritePin(ST7735_CS_GPIO_Port, ST7735_CS_Pin, GPIO_PIN_RESET);

  /*Configure GPIO pin Output Level */
  HAL_GPIO_WritePin(GPIOB, ST7735_DC_Pin|ST7735_RES_Pin|GPIO_PIN_3|GPIO_PIN_4
                          |GPIO_PIN_5|GPIO_PIN_6, GPIO_PIN_RESET);

  /*Configure GPIO pin : ST7735_CS_Pin */
  GPIO_InitStruct.Pin = ST7735_CS_Pin;
  GPIO_InitStruct.Mode = GPIO_MODE_OUTPUT_PP;
  GPIO_InitStruct.Pull = GPIO_NOPULL;
  GPIO_InitStruct.Speed = GPIO_SPEED_FREQ_LOW;
  HAL_GPIO_Init(ST7735_CS_GPIO_Port, &GPIO_InitStruct);

  /*Configure GPIO pins : ST7735_DC_Pin ST7735_RES_Pin PB3 PB4
                           PB5 PB6 */
  GPIO_InitStruct.Pin = ST7735_DC_Pin|ST7735_RES_Pin|GPIO_PIN_3|GPIO_PIN_4
                          |GPIO_PIN_5|GPIO_PIN_6;
  GPIO_InitStruct.Mode = GPIO_MODE_OUTPUT_PP;
  GPIO_InitStruct.Pull = GPIO_NOPULL;
  GPIO_InitStruct.Speed = GPIO_SPEED_FREQ_LOW;
  HAL_GPIO_Init(GPIOB, &GPIO_InitStruct);

  /*Configure GPIO pins : PA9 PA10 PA11 PA12 */
  GPIO_InitStruct.Pin = GPIO_PIN_9|GPIO_PIN_10|GPIO_PIN_11|GPIO_PIN_12;
  GPIO_InitStruct.Mode = GPIO_MODE_INPUT;
  GPIO_InitStruct.Pull = GPIO_PULLUP;
  HAL_GPIO_Init(GPIOA, &GPIO_InitStruct);

}

/* USER CODE BEGIN 4 */

void IniciarJogo(){
	int sair = 0;
	QuantidadeJogadores = 0;
	ST7735_FillScreen(BLACK);
	ST7735_WriteString(39, 0, "Escolha", Font_11x18, WHITE, BLACK);
	ST7735_WriteString(43, 20, "1P", Font_11x18, WHITE, BLACK);
	ST7735_WriteString(95, 20, "2P", Font_11x18, WHITE, BLACK);
	ST7735_WriteString(0, 50, "Recorde:", Font_11x18, WHITE, BLACK);
	itoa(TentativasRecorde, po, 10);
	ST7735_WriteString(98, 50, po, Font_11x18, WHITE, BLACK);
	int escolha = 1;
	while(HAL_GPIO_ReadPin(GPIOA, GPIO_PIN_10)== 1)
	{
		int esquerdaMenu = HAL_GPIO_ReadPin(GPIOA, GPIO_PIN_9);
		int direitaMenu = HAL_GPIO_ReadPin(GPIOA, GPIO_PIN_11);
		if(esquerdaMenu == 0)
		{
			escolha--;
		}
		if(direitaMenu == 0)
		{
			escolha++;
		}
		if(escolha == 1)
		{
			ST7735_FillRectangle(95, 40, 22, 3, BLACK);
			ST7735_FillRectangle(43, 40, 22, 3, MAGENTA);
		}
		else if(escolha == 2)
		{
			ST7735_FillRectangle(43, 40, 22, 3, BLACK);
			ST7735_FillRectangle(95, 40, 22, 3, MAGENTA);
		}
		else if(escolha > 2)
		{
			escolha = 2;
		}
		else
		{
			escolha = 1;
		}
	}

	QuantidadeJogadores = escolha;
	HAL_Delay(1000);
	TamanhoMatriz();

	GerarParesAleatorios();

	while(sair==0){
		ST7735_FillScreen(BLACK);
		MostrarCartas();
		HAL_Delay(1000);
		for(int j=0;j<ColunaMatriz;j++)
		{
			for(int i = 0; i < LinhaMatriz; i++)
			{
				ST7735_DrawImage((PaddingX + j*(PaddingX+15)), (i*(15+PaddingY))+PaddingY, 15, 15, Carta);
				HAL_Delay(200);
			}
		}
		sair = 1;
	}
	JogoAndamento = 1;
	PontosJogador1 = 0;
	PontosJogador2 = 0;
	tentativas = 0;
	linha = 0;
	coluna = 0;
}

void TamanhoMatriz()
{
	ST7735_FillScreen(BLACK);
	ST7735_WriteString(39, 0, "Tamanho", Font_11x18, WHITE, BLACK);
	ST7735_WriteString(19, 20, "4x4", Font_11x18, WHITE, BLACK);
	ST7735_WriteString(109, 20, "4x3", Font_11x18, WHITE, BLACK);
	ST7735_WriteString(19, 50, "4x2", Font_11x18, WHITE, BLACK);
	ST7735_WriteString(109, 50, "2x2", Font_11x18, WHITE, BLACK);
	int escolhaTamanho = 1;
	while(HAL_GPIO_ReadPin(GPIOA, GPIO_PIN_10)== 1)
	{
		int esquerdaTamanho = HAL_GPIO_ReadPin(GPIOA, GPIO_PIN_9);
		int direitaTamanho = HAL_GPIO_ReadPin(GPIOA, GPIO_PIN_11);
		if(esquerdaTamanho == 0)
		{
			escolhaTamanho--;
		}
		if(direitaTamanho == 0)
		{
			escolhaTamanho++;
		}
		if(escolhaTamanho == 1)
		{
			ST7735_FillRectangle(109, 40, 33, 3, BLACK);
			ST7735_FillRectangle(19, 70, 33, 3, BLACK);
			ST7735_FillRectangle(109, 70, 33, 3, BLACK);
			ST7735_FillRectangle(19, 40, 33, 3, MAGENTA);
		}
		else if(escolhaTamanho == 2)
		{
			ST7735_FillRectangle(19, 40, 33, 3, BLACK);
			ST7735_FillRectangle(19, 70, 33, 3, BLACK);
			ST7735_FillRectangle(109, 70, 33, 3, BLACK);
			ST7735_FillRectangle(109, 40, 33, 3, MAGENTA);
		}
		else if(escolhaTamanho == 3)
		{
			ST7735_FillRectangle(109, 70, 33, 3, BLACK);
			ST7735_FillRectangle(19, 40, 33, 3, BLACK);
			ST7735_FillRectangle(109, 40, 33, 3, BLACK);
			ST7735_FillRectangle(19, 70, 33, 3, MAGENTA);
		}
		else if(escolhaTamanho == 4)
		{
			ST7735_FillRectangle(19, 40, 33, 3, BLACK);
			ST7735_FillRectangle(109, 40, 33, 3, BLACK);
			ST7735_FillRectangle(19, 70, 33, 3, BLACK);
			ST7735_FillRectangle(109, 70, 33, 3, MAGENTA);
		}
		else if(escolhaTamanho > 4)
		{
			escolhaTamanho = 4;
		}
		else
		{
			escolhaTamanho = 1;
		}
		HAL_Delay(150);
	}
	if(escolhaTamanho == 1)
	{
		ColunaMatriz = 4;
		LinhaMatriz = 4;
	}
	else if( escolhaTamanho == 2)
	{
		ColunaMatriz = 4;
		LinhaMatriz = 3;
	}
	else if( escolhaTamanho == 3)
	{
		ColunaMatriz = 4;
		LinhaMatriz = 2;
	}
	else
	{
		ColunaMatriz = 2;
		LinhaMatriz = 2;
	}
	PaddingX = ((160 - ColunaMatriz * 15))/(ColunaMatriz + 1);
	PaddingY = ((80 - LinhaMatriz * 15))/(LinhaMatriz + 1);
}

void GerarParesAleatorios(){

	for(int i = 0; i < ((ColunaMatriz * LinhaMatriz)/2); i++)
	{
		int contador = 0;
		while(contador < 2)
		{

			int n1 = (rand()%ColunaMatriz);
			HAL_Delay(5);
			int n2 = (rand()%LinhaMatriz);
			HAL_Delay(5);

			if(posicoes[n1][n2] == 8)
			{
				posicoes[n1][n2] = i;
				contador++;
			}

		}
	}

}

void NavegarCursor(int nav){
	if(nav == 1)
	{
		if(coluna != 0)
		{
			coluna--;
		}
	}
	else if(nav == 2)
	{
		if(linha == 0)
		{
			linha = LinhaMatriz - 1;
		}
		else
		{
			linha--;
		}
	}
	else if(nav == 3)
	{
		if(coluna != (ColunaMatriz - 1))
		{
			coluna++;
		}
	}
	for(int j=0;j<ColunaMatriz;j++)
				{
					for(int i = 0; i < LinhaMatriz; i++)
					{
						ST7735_FillRectangle((PaddingX + j*(PaddingX+15)), (i*(15+PaddingY))+(PaddingY + 15), 15, 3, BLACK);
					}
				}
	HAL_Delay(200);
	if(VerificarJogador % 2 == 0)
	{
		ST7735_FillRectangle((PaddingX + coluna*(PaddingX+15)), (linha*(15+PaddingY))+(PaddingY + 15), 15, 3, RED);
	}
	else
	{
		ST7735_FillRectangle((PaddingX + coluna*(PaddingX+15)), (linha*(15+PaddingY))+(PaddingY + 15), 15, 3, BLUE);
	}
}

void SelecionarCarta()
{
	ST7735_FillRectangle((PaddingX + coluna*(PaddingX+15)), (linha*(15+PaddingY))+PaddingY, 15, 15, cores[posicoes[coluna][linha]]);
}

void CompararCarta()
{
	if(pos_selec1[0] == 8 && pos_selec1[1] == 8)
	{
		pos_selec1[0] = coluna;
		pos_selec1[1] = linha;
		if(posicoes[pos_selec1[0]][pos_selec1[1]] == 8)
		{
			pos_selec1[0] = 8;
			pos_selec1[1] = 8;
		}
		else
		{
			SelecionarCarta();
		}
	}
	else if(pos_selec2[0] == 8 && pos_selec2[1] == 8)
	{
		pos_selec2[0] = coluna;
		pos_selec2[1] = linha;
		if(posicoes[pos_selec2[0]][pos_selec2[1]] != 8 && (pos_selec2[0] != pos_selec1[0] || pos_selec2[1] != pos_selec1[1]))
		{
			SelecionarCarta();
			HAL_Delay(500);
			if(posicoes[pos_selec1[0]][pos_selec1[1]] == posicoes[pos_selec2[0]][pos_selec2[1]])
			{
				posicoes[pos_selec1[0]][pos_selec1[1]] = 8;
				posicoes[pos_selec2[0]][pos_selec2[1]] = 8;
			}
			else
			{
				ST7735_DrawImage((PaddingX + pos_selec1[0]*(PaddingX+15)), (pos_selec1[1]*(15+PaddingY))+PaddingY, 15, 15, Carta);
				ST7735_DrawImage((PaddingX + pos_selec2[0]*(PaddingX+15)), (pos_selec2[1]*(15+PaddingY))+PaddingY, 15, 15, Carta);
			}
			pos_selec1[0]= 8;
			pos_selec1[1]= 8;
			pos_selec2[0]= 8;
			pos_selec2[1]= 8;
			if(QuantidadeJogadores == 2)
			{
				ModificarJogador();
			}
			else
			{
				AtualizarTentativas();
			}
		}
		else
		{
			pos_selec2[0]= 8;
			pos_selec2[1]= 8;
		}
	}
}

void VerificarFimDeJogo()
{
	int ContadorJogadas = 0;
	for(int j = 0; j < ColunaMatriz; j++)
	{
		for(int i = 0; i < LinhaMatriz; i++)
		{
			if(posicoes[j][i] == 8)
			{
				ContadorJogadas++;
			}
		}
	}
	if(ContadorJogadas == (ColunaMatriz * LinhaMatriz))JogoAndamento = 0;
}

void AtualizarTentativas()
{
	tentativas++;
}

void AtualizarRecorde()
{
	if(TentativasRecorde == 0)
	{
		TentativasRecorde = tentativas;
	}
	else if(tentativas < TentativasRecorde)
	{
		TentativasRecorde = tentativas;
	}
}

void ExibirFimDeJogo()
{
	if(QuantidadeJogadores == 1)
	{
		while(1)
		{
			ST7735_FillScreen(BLACK);
			ST7735_DrawImage(40, 10, 80, 60, ImagemVitoria1);
			HAL_Delay(100);
			if(HAL_GPIO_ReadPin(GPIOA, GPIO_PIN_10) == 0)break;
			ST7735_FillScreen(BLACK);
			ST7735_DrawImage(40, 10, 80, 60, ImagemVitoria2);
			HAL_Delay(100);
			if(HAL_GPIO_ReadPin(GPIOA, GPIO_PIN_10) == 0)break;
			ST7735_FillScreen(BLACK);
			ST7735_DrawImage(40, 10, 80, 60, ImagemVitoria3);
			HAL_Delay(100);
			if(HAL_GPIO_ReadPin(GPIOA, GPIO_PIN_10) == 0)break;
			ST7735_FillScreen(BLACK);
			ST7735_DrawImage(40, 10, 80, 60, ImagemVitoria4);
			HAL_Delay(100);
			if(HAL_GPIO_ReadPin(GPIOA, GPIO_PIN_10) == 0)break;
		}
		HAL_Delay(500);
		itoa(tentativas, po, 10);
		ST7735_FillScreen(BLACK);
		ST7735_WriteString(0, 0, "Tentativas:", Font_11x18, WHITE, BLACK);
		ST7735_WriteString(120, 00, po, Font_11x18, WHITE, BLACK);
		ST7735_WriteString(0, 20, "Recorde:", Font_11x18, WHITE, BLACK);
		itoa(TentativasRecorde, po, 10);
		ST7735_WriteString(100, 20, po, Font_11x18, WHITE, BLACK);
		HAL_Delay(1000);
		while(HAL_GPIO_ReadPin(GPIOA, GPIO_PIN_10) == 1);
		HAL_Delay(500);
	}
	else
	{
		ST7735_FillScreen(BLACK);
		ST7735_FillScreen(BLACK);
		ST7735_WriteString(0, 0, "Tentativas P1:", Font_11x18, WHITE, BLACK);
		itoa(PontosJogador1, po, 10);
		ST7735_WriteString(0, 20, po, Font_11x18, WHITE, BLACK);
		ST7735_WriteString(0, 40, "Tentativas P2:", Font_11x18, WHITE, BLACK);
		itoa(PontosJogador2, po, 10);
		ST7735_WriteString(0, 60, po, Font_11x18, WHITE, BLACK);
		while(HAL_GPIO_ReadPin(GPIOA, GPIO_PIN_10) == 1);
		HAL_Delay(500);
	}
}

void MostrarCartas()
{
	for(int j = 0; j < ColunaMatriz; j++)
	{
		for(int i = 0; i < LinhaMatriz; i++)
		{
			ST7735_FillRectangle((PaddingX + j*(PaddingX+15)), (i*(15+PaddingY))+PaddingY, 15, 15, cores[posicoes[j][i]]);
			HAL_Delay(200);
		}
	}
}

void ModificarJogador()
{
	if(VerificarJogador % 2 == 0)
	{
		PontosJogador2++;
		VerificarJogador++;
	}
	else
	{
		PontosJogador1++;
		VerificarJogador++;
	}
	linha = 0;
	coluna = 0;
	NavegarCursor(0);
}

/* USER CODE END 4 */

void Error_Handler(void)
{
  __disable_irq();
  while (1)
  {
  }
}

/************************ (C) COPYRIGHT STMicroelectronics *****END OF FILE****/
